[part 20 of 23: package /ComponentTypes]
AUTOSAR XML (schema 4-3-0)
package /ComponentTypes  (continued)
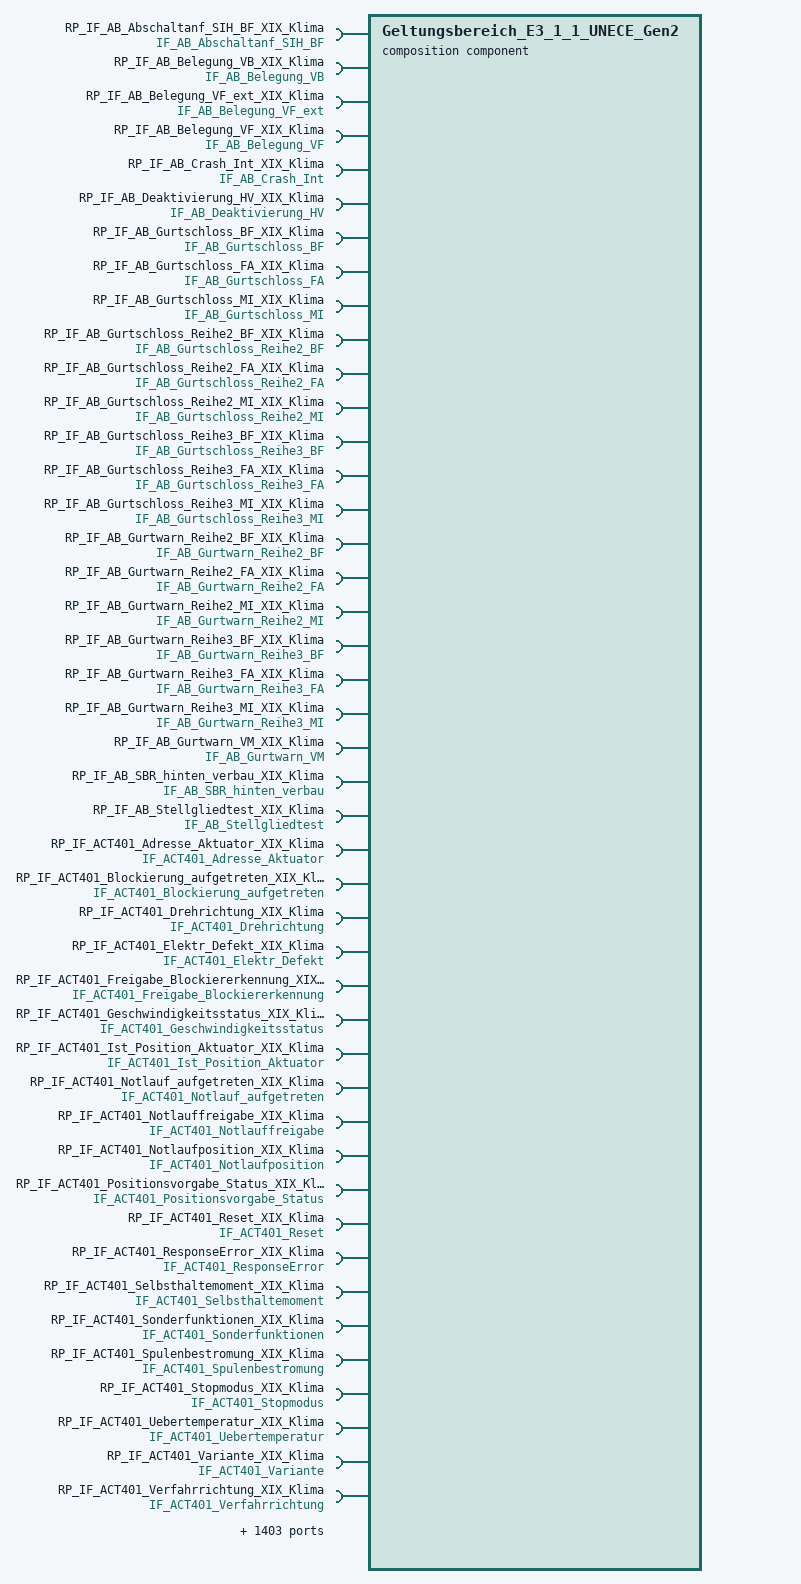
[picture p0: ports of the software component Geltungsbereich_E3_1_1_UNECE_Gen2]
  composition sw component type Geltungsbereich_E3_1_1_UNECE_Gen2  (continued)
    1485 x require port:
      RP_IF_AB_Abschaltanf_SIH_BF_XIX_Klima: required-interface=IF_AB_Abschaltanf_SIH_BF
      RP_IF_AB_Belegung_VB_XIX_Klima: required-interface=IF_AB_Belegung_VB
      RP_IF_AB_Belegung_VF_ext_XIX_Klima: required-interface=IF_AB_Belegung_VF_ext
      RP_IF_AB_Belegung_VF_XIX_Klima: required-interface=IF_AB_Belegung_VF
      RP_IF_AB_Crash_Int_XIX_Klima: required-interface=IF_AB_Crash_Int
      RP_IF_AB_Deaktivierung_HV_XIX_Klima: required-interface=IF_AB_Deaktivierung_HV
      RP_IF_AB_Gurtschloss_BF_XIX_Klima: required-interface=IF_AB_Gurtschloss_BF
      RP_IF_AB_Gurtschloss_FA_XIX_Klima: required-interface=IF_AB_Gurtschloss_FA
      RP_IF_AB_Gurtschloss_MI_XIX_Klima: required-interface=IF_AB_Gurtschloss_MI
      RP_IF_AB_Gurtschloss_Reihe2_BF_XIX_Klima: required-interface=IF_AB_Gurtschloss_Reihe2_BF
      RP_IF_AB_Gurtschloss_Reihe2_FA_XIX_Klima: required-interface=IF_AB_Gurtschloss_Reihe2_FA
      RP_IF_AB_Gurtschloss_Reihe2_MI_XIX_Klima: required-interface=IF_AB_Gurtschloss_Reihe2_MI
      RP_IF_AB_Gurtschloss_Reihe3_BF_XIX_Klima: required-interface=IF_AB_Gurtschloss_Reihe3_BF
      RP_IF_AB_Gurtschloss_Reihe3_FA_XIX_Klima: required-interface=IF_AB_Gurtschloss_Reihe3_FA
      RP_IF_AB_Gurtschloss_Reihe3_MI_XIX_Klima: required-interface=IF_AB_Gurtschloss_Reihe3_MI
      RP_IF_AB_Gurtwarn_Reihe2_BF_XIX_Klima: required-interface=IF_AB_Gurtwarn_Reihe2_BF
      RP_IF_AB_Gurtwarn_Reihe2_FA_XIX_Klima: required-interface=IF_AB_Gurtwarn_Reihe2_FA
      RP_IF_AB_Gurtwarn_Reihe2_MI_XIX_Klima: required-interface=IF_AB_Gurtwarn_Reihe2_MI
      RP_IF_AB_Gurtwarn_Reihe3_BF_XIX_Klima: required-interface=IF_AB_Gurtwarn_Reihe3_BF
      RP_IF_AB_Gurtwarn_Reihe3_FA_XIX_Klima: required-interface=IF_AB_Gurtwarn_Reihe3_FA
      RP_IF_AB_Gurtwarn_Reihe3_MI_XIX_Klima: required-interface=IF_AB_Gurtwarn_Reihe3_MI
      RP_IF_AB_Gurtwarn_VM_XIX_Klima: required-interface=IF_AB_Gurtwarn_VM
      RP_IF_AB_SBR_hinten_verbau_XIX_Klima: required-interface=IF_AB_SBR_hinten_verbau
      RP_IF_AB_Stellgliedtest_XIX_Klima: required-interface=IF_AB_Stellgliedtest
      RP_IF_ACT401_Adresse_Aktuator_XIX_Klima: required-interface=IF_ACT401_Adresse_Aktuator
      RP_IF_ACT401_Blockierung_aufgetreten_XIX_Klima: required-interface=IF_ACT401_Blockierung_aufgetreten
      RP_IF_ACT401_Drehrichtung_XIX_Klima: required-interface=IF_ACT401_Drehrichtung
      RP_IF_ACT401_Elektr_Defekt_XIX_Klima: required-interface=IF_ACT401_Elektr_Defekt
      RP_IF_ACT401_Freigabe_Blockiererkennung_XIX_Klima: required-interface=IF_ACT401_Freigabe_Blockiererkennung
      RP_IF_ACT401_Geschwindigkeitsstatus_XIX_Klima: required-interface=IF_ACT401_Geschwindigkeitsstatus
      RP_IF_ACT401_Ist_Position_Aktuator_XIX_Klima: required-interface=IF_ACT401_Ist_Position_Aktuator
      RP_IF_ACT401_Notlauf_aufgetreten_XIX_Klima: required-interface=IF_ACT401_Notlauf_aufgetreten
      RP_IF_ACT401_Notlauffreigabe_XIX_Klima: required-interface=IF_ACT401_Notlauffreigabe
      RP_IF_ACT401_Notlaufposition_XIX_Klima: required-interface=IF_ACT401_Notlaufposition
      RP_IF_ACT401_Positionsvorgabe_Status_XIX_Klima: required-interface=IF_ACT401_Positionsvorgabe_Status
      RP_IF_ACT401_Reset_XIX_Klima: required-interface=IF_ACT401_Reset
      RP_IF_ACT401_ResponseError_XIX_Klima: required-interface=IF_ACT401_ResponseError
      RP_IF_ACT401_Selbsthaltemoment_XIX_Klima: required-interface=IF_ACT401_Selbsthaltemoment
      RP_IF_ACT401_Sonderfunktionen_XIX_Klima: required-interface=IF_ACT401_Sonderfunktionen
      RP_IF_ACT401_Spulenbestromung_XIX_Klima: required-interface=IF_ACT401_Spulenbestromung
      RP_IF_ACT401_Stopmodus_XIX_Klima: required-interface=IF_ACT401_Stopmodus
      RP_IF_ACT401_Uebertemperatur_XIX_Klima: required-interface=IF_ACT401_Uebertemperatur
      RP_IF_ACT401_Variante_XIX_Klima: required-interface=IF_ACT401_Variante
      RP_IF_ACT401_Verfahrrichtung_XIX_Klima: required-interface=IF_ACT401_Verfahrrichtung
      RP_IF_ACT401_Versorgungsspannung_XIX_Klima: required-interface=IF_ACT401_Versorgungsspannung
      RP_IF_ACT402_Adresse_Aktuator_XIX_Klima: required-interface=IF_ACT402_Adresse_Aktuator
      RP_IF_ACT402_Blockierung_aufgetreten_XIX_Klima: required-interface=IF_ACT402_Blockierung_aufgetreten
      RP_IF_ACT402_Drehrichtung_XIX_Klima: required-interface=IF_ACT402_Drehrichtung
      RP_IF_ACT402_Elektr_Defekt_XIX_Klima: required-interface=IF_ACT402_Elektr_Defekt
      RP_IF_ACT402_Freigabe_Blockiererkennung_XIX_Klima: required-interface=IF_ACT402_Freigabe_Blockiererkennung
      RP_IF_ACT402_Geschwindigkeitsstatus_XIX_Klima: required-interface=IF_ACT402_Geschwindigkeitsstatus
      RP_IF_ACT402_Ist_Position_Aktuator_XIX_Klima: required-interface=IF_ACT402_Ist_Position_Aktuator
      RP_IF_ACT402_Notlauf_aufgetreten_XIX_Klima: required-interface=IF_ACT402_Notlauf_aufgetreten
      RP_IF_ACT402_Notlauffreigabe_XIX_Klima: required-interface=IF_ACT402_Notlauffreigabe
      RP_IF_ACT402_Notlaufposition_XIX_Klima: required-interface=IF_ACT402_Notlaufposition
      RP_IF_ACT402_Positionsvorgabe_Status_XIX_Klima: required-interface=IF_ACT402_Positionsvorgabe_Status
      RP_IF_ACT402_Reset_XIX_Klima: required-interface=IF_ACT402_Reset
      RP_IF_ACT402_ResponseError_XIX_Klima: required-interface=IF_ACT402_ResponseError
      RP_IF_ACT402_Selbsthaltemoment_XIX_Klima: required-interface=IF_ACT402_Selbsthaltemoment
      RP_IF_ACT402_Sonderfunktionen_XIX_Klima: required-interface=IF_ACT402_Sonderfunktionen
      RP_IF_ACT402_Spulenbestromung_XIX_Klima: required-interface=IF_ACT402_Spulenbestromung
      RP_IF_ACT402_Stopmodus_XIX_Klima: required-interface=IF_ACT402_Stopmodus
      RP_IF_ACT402_Uebertemperatur_XIX_Klima: required-interface=IF_ACT402_Uebertemperatur
      RP_IF_ACT402_Variante_XIX_Klima: required-interface=IF_ACT402_Variante
      RP_IF_ACT402_Verfahrrichtung_XIX_Klima: required-interface=IF_ACT402_Verfahrrichtung
      RP_IF_ACT402_Versorgungsspannung_XIX_Klima: required-interface=IF_ACT402_Versorgungsspannung
      RP_IF_ACT403_Adresse_Aktuator_XIX_Klima: required-interface=IF_ACT403_Adresse_Aktuator
      RP_IF_ACT403_Blockierung_aufgetreten_XIX_Klima: required-interface=IF_ACT403_Blockierung_aufgetreten
      RP_IF_ACT403_Drehrichtung_XIX_Klima: required-interface=IF_ACT403_Drehrichtung
      RP_IF_ACT403_Elektr_Defekt_XIX_Klima: required-interface=IF_ACT403_Elektr_Defekt
      RP_IF_ACT403_Freigabe_Blockiererkennung_XIX_Klima: required-interface=IF_ACT403_Freigabe_Blockiererkennung
      RP_IF_ACT403_Geschwindigkeitsstatus_XIX_Klima: required-interface=IF_ACT403_Geschwindigkeitsstatus
      RP_IF_ACT403_Ist_Position_Aktuator_XIX_Klima: required-interface=IF_ACT403_Ist_Position_Aktuator
      RP_IF_ACT403_Notlauf_aufgetreten_XIX_Klima: required-interface=IF_ACT403_Notlauf_aufgetreten
      RP_IF_ACT403_Notlauffreigabe_XIX_Klima: required-interface=IF_ACT403_Notlauffreigabe
      RP_IF_ACT403_Notlaufposition_XIX_Klima: required-interface=IF_ACT403_Notlaufposition
      RP_IF_ACT403_Positionsvorgabe_Status_XIX_Klima: required-interface=IF_ACT403_Positionsvorgabe_Status
      RP_IF_ACT403_Reset_XIX_Klima: required-interface=IF_ACT403_Reset
      RP_IF_ACT403_ResponseError_XIX_Klima: required-interface=IF_ACT403_ResponseError
      RP_IF_ACT403_Selbsthaltemoment_XIX_Klima: required-interface=IF_ACT403_Selbsthaltemoment
      RP_IF_ACT403_Sonderfunktionen_XIX_Klima: required-interface=IF_ACT403_Sonderfunktionen
      RP_IF_ACT403_Spulenbestromung_XIX_Klima: required-interface=IF_ACT403_Spulenbestromung
      RP_IF_ACT403_Stopmodus_XIX_Klima: required-interface=IF_ACT403_Stopmodus
      RP_IF_ACT403_Uebertemperatur_XIX_Klima: required-interface=IF_ACT403_Uebertemperatur
      RP_IF_ACT403_Variante_XIX_Klima: required-interface=IF_ACT403_Variante
      RP_IF_ACT403_Verfahrrichtung_XIX_Klima: required-interface=IF_ACT403_Verfahrrichtung
      RP_IF_ACT403_Versorgungsspannung_XIX_Klima: required-interface=IF_ACT403_Versorgungsspannung
      RP_IF_ACT404_Adresse_Aktuator_XIX_Klima: required-interface=IF_ACT404_Adresse_Aktuator
      RP_IF_ACT404_Blockierung_aufgetreten_XIX_Klima: required-interface=IF_ACT404_Blockierung_aufgetreten
      RP_IF_ACT404_Drehrichtung_XIX_Klima: required-interface=IF_ACT404_Drehrichtung
      RP_IF_ACT404_Elektr_Defekt_XIX_Klima: required-interface=IF_ACT404_Elektr_Defekt
      RP_IF_ACT404_Freigabe_Blockiererkennung_XIX_Klima: required-interface=IF_ACT404_Freigabe_Blockiererkennung
      RP_IF_ACT404_Geschwindigkeitsstatus_XIX_Klima: required-interface=IF_ACT404_Geschwindigkeitsstatus
      RP_IF_ACT404_Ist_Position_Aktuator_XIX_Klima: required-interface=IF_ACT404_Ist_Position_Aktuator
      RP_IF_ACT404_Notlauf_aufgetreten_XIX_Klima: required-interface=IF_ACT404_Notlauf_aufgetreten
      RP_IF_ACT404_Notlauffreigabe_XIX_Klima: required-interface=IF_ACT404_Notlauffreigabe
      RP_IF_ACT404_Notlaufposition_XIX_Klima: required-interface=IF_ACT404_Notlaufposition
      RP_IF_ACT404_Positionsvorgabe_Status_XIX_Klima: required-interface=IF_ACT404_Positionsvorgabe_Status
      RP_IF_ACT404_Reset_XIX_Klima: required-interface=IF_ACT404_Reset
      RP_IF_ACT404_ResponseError_XIX_Klima: required-interface=IF_ACT404_ResponseError
      RP_IF_ACT404_Selbsthaltemoment_XIX_Klima: required-interface=IF_ACT404_Selbsthaltemoment
      RP_IF_ACT404_Sonderfunktionen_XIX_Klima: required-interface=IF_ACT404_Sonderfunktionen
      RP_IF_ACT404_Spulenbestromung_XIX_Klima: required-interface=IF_ACT404_Spulenbestromung
      RP_IF_ACT404_Stopmodus_XIX_Klima: required-interface=IF_ACT404_Stopmodus
      RP_IF_ACT404_Uebertemperatur_XIX_Klima: required-interface=IF_ACT404_Uebertemperatur
      RP_IF_ACT404_Variante_XIX_Klima: required-interface=IF_ACT404_Variante
      RP_IF_ACT404_Verfahrrichtung_XIX_Klima: required-interface=IF_ACT404_Verfahrrichtung
      RP_IF_ACT404_Versorgungsspannung_XIX_Klima: required-interface=IF_ACT404_Versorgungsspannung
      RP_IF_ACT405_Adresse_Aktuator_XIX_Klima: required-interface=IF_ACT405_Adresse_Aktuator
      RP_IF_ACT405_Blockierung_aufgetreten_XIX_Klima: required-interface=IF_ACT405_Blockierung_aufgetreten
      RP_IF_ACT405_Drehrichtung_XIX_Klima: required-interface=IF_ACT405_Drehrichtung
      RP_IF_ACT405_Elektr_Defekt_XIX_Klima: required-interface=IF_ACT405_Elektr_Defekt
      RP_IF_ACT405_Freigabe_Blockiererkennung_XIX_Klima: required-interface=IF_ACT405_Freigabe_Blockiererkennung
      RP_IF_ACT405_Geschwindigkeitsstatus_XIX_Klima: required-interface=IF_ACT405_Geschwindigkeitsstatus
      RP_IF_ACT405_Ist_Position_Aktuator_XIX_Klima: required-interface=IF_ACT405_Ist_Position_Aktuator
      RP_IF_ACT405_Notlauf_aufgetreten_XIX_Klima: required-interface=IF_ACT405_Notlauf_aufgetreten
      RP_IF_ACT405_Notlauffreigabe_XIX_Klima: required-interface=IF_ACT405_Notlauffreigabe
      RP_IF_ACT405_Notlaufposition_XIX_Klima: required-interface=IF_ACT405_Notlaufposition
      RP_IF_ACT405_Positionsvorgabe_Status_XIX_Klima: required-interface=IF_ACT405_Positionsvorgabe_Status
      RP_IF_ACT405_Reset_XIX_Klima: required-interface=IF_ACT405_Reset
      RP_IF_ACT405_ResponseError_XIX_Klima: required-interface=IF_ACT405_ResponseError
      RP_IF_ACT405_Selbsthaltemoment_XIX_Klima: required-interface=IF_ACT405_Selbsthaltemoment
      RP_IF_ACT405_Sonderfunktionen_XIX_Klima: required-interface=IF_ACT405_Sonderfunktionen
      RP_IF_ACT405_Spulenbestromung_XIX_Klima: required-interface=IF_ACT405_Spulenbestromung
      RP_IF_ACT405_Stopmodus_XIX_Klima: required-interface=IF_ACT405_Stopmodus
      RP_IF_ACT405_Uebertemperatur_XIX_Klima: required-interface=IF_ACT405_Uebertemperatur
      RP_IF_ACT405_Variante_XIX_Klima: required-interface=IF_ACT405_Variante
      RP_IF_ACT405_Verfahrrichtung_XIX_Klima: required-interface=IF_ACT405_Verfahrrichtung
      RP_IF_ACT405_Versorgungsspannung_XIX_Klima: required-interface=IF_ACT405_Versorgungsspannung
      RP_IF_ACT406_Adresse_Aktuator_XIX_Klima: required-interface=IF_ACT406_Adresse_Aktuator
      RP_IF_ACT406_Blockierung_aufgetreten_XIX_Klima: required-interface=IF_ACT406_Blockierung_aufgetreten
      RP_IF_ACT406_Drehrichtung_XIX_Klima: required-interface=IF_ACT406_Drehrichtung
      RP_IF_ACT406_Elektr_Defekt_XIX_Klima: required-interface=IF_ACT406_Elektr_Defekt
      RP_IF_ACT406_Freigabe_Blockiererkennung_XIX_Klima: required-interface=IF_ACT406_Freigabe_Blockiererkennung
      RP_IF_ACT406_Geschwindigkeitsstatus_XIX_Klima: required-interface=IF_ACT406_Geschwindigkeitsstatus
      RP_IF_ACT406_Ist_Position_Aktuator_XIX_Klima: required-interface=IF_ACT406_Ist_Position_Aktuator
      RP_IF_ACT406_Notlauf_aufgetreten_XIX_Klima: required-interface=IF_ACT406_Notlauf_aufgetreten
      RP_IF_ACT406_Notlauffreigabe_XIX_Klima: required-interface=IF_ACT406_Notlauffreigabe
      RP_IF_ACT406_Notlaufposition_XIX_Klima: required-interface=IF_ACT406_Notlaufposition
      RP_IF_ACT406_Positionsvorgabe_Status_XIX_Klima: required-interface=IF_ACT406_Positionsvorgabe_Status
      RP_IF_ACT406_Reset_XIX_Klima: required-interface=IF_ACT406_Reset
      RP_IF_ACT406_ResponseError_XIX_Klima: required-interface=IF_ACT406_ResponseError
      RP_IF_ACT406_Selbsthaltemoment_XIX_Klima: required-interface=IF_ACT406_Selbsthaltemoment
      RP_IF_ACT406_Sonderfunktionen_XIX_Klima: required-interface=IF_ACT406_Sonderfunktionen
      RP_IF_ACT406_Spulenbestromung_XIX_Klima: required-interface=IF_ACT406_Spulenbestromung
      RP_IF_ACT406_Stopmodus_XIX_Klima: required-interface=IF_ACT406_Stopmodus
      RP_IF_ACT406_Uebertemperatur_XIX_Klima: required-interface=IF_ACT406_Uebertemperatur
      RP_IF_ACT406_Variante_XIX_Klima: required-interface=IF_ACT406_Variante
      RP_IF_ACT406_Verfahrrichtung_XIX_Klima: required-interface=IF_ACT406_Verfahrrichtung
      RP_IF_ACT406_Versorgungsspannung_XIX_Klima: required-interface=IF_ACT406_Versorgungsspannung
      RP_IF_ACT407_Adresse_Aktuator_XIX_Klima: required-interface=IF_ACT407_Adresse_Aktuator
      RP_IF_ACT407_Blockierung_aufgetreten_XIX_Klima: required-interface=IF_ACT407_Blockierung_aufgetreten
      RP_IF_ACT407_Drehrichtung_XIX_Klima: required-interface=IF_ACT407_Drehrichtung
      RP_IF_ACT407_Elektr_Defekt_XIX_Klima: required-interface=IF_ACT407_Elektr_Defekt
      RP_IF_ACT407_Freigabe_Blockiererkennung_XIX_Klima: required-interface=IF_ACT407_Freigabe_Blockiererkennung
      RP_IF_ACT407_Geschwindigkeitsstatus_XIX_Klima: required-interface=IF_ACT407_Geschwindigkeitsstatus
      RP_IF_ACT407_Ist_Position_Aktuator_XIX_Klima: required-interface=IF_ACT407_Ist_Position_Aktuator
      RP_IF_ACT407_Notlauf_aufgetreten_XIX_Klima: required-interface=IF_ACT407_Notlauf_aufgetreten
      RP_IF_ACT407_Notlauffreigabe_XIX_Klima: required-interface=IF_ACT407_Notlauffreigabe
      RP_IF_ACT407_Notlaufposition_XIX_Klima: required-interface=IF_ACT407_Notlaufposition
      RP_IF_ACT407_Positionsvorgabe_Status_XIX_Klima: required-interface=IF_ACT407_Positionsvorgabe_Status
      RP_IF_ACT407_Reset_XIX_Klima: required-interface=IF_ACT407_Reset
      RP_IF_ACT407_ResponseError_XIX_Klima: required-interface=IF_ACT407_ResponseError
      RP_IF_ACT407_Selbsthaltemoment_XIX_Klima: required-interface=IF_ACT407_Selbsthaltemoment
      RP_IF_ACT407_Sonderfunktionen_XIX_Klima: required-interface=IF_ACT407_Sonderfunktionen
      RP_IF_ACT407_Spulenbestromung_XIX_Klima: required-interface=IF_ACT407_Spulenbestromung
      RP_IF_ACT407_Stopmodus_XIX_Klima: required-interface=IF_ACT407_Stopmodus
      RP_IF_ACT407_Uebertemperatur_XIX_Klima: required-interface=IF_ACT407_Uebertemperatur
      RP_IF_ACT407_Variante_XIX_Klima: required-interface=IF_ACT407_Variante
      RP_IF_ACT407_Verfahrrichtung_XIX_Klima: required-interface=IF_ACT407_Verfahrrichtung
      RP_IF_ACT407_Versorgungsspannung_XIX_Klima: required-interface=IF_ACT407_Versorgungsspannung
      RP_IF_ACT408_Adresse_Aktuator_XIX_Klima: required-interface=IF_ACT408_Adresse_Aktuator
      RP_IF_ACT408_Blockierung_aufgetreten_XIX_Klima: required-interface=IF_ACT408_Blockierung_aufgetreten
      RP_IF_ACT408_Drehrichtung_XIX_Klima: required-interface=IF_ACT408_Drehrichtung
      RP_IF_ACT408_Elektr_Defekt_XIX_Klima: required-interface=IF_ACT408_Elektr_Defekt
      RP_IF_ACT408_Freigabe_Blockiererkennung_XIX_Klima: required-interface=IF_ACT408_Freigabe_Blockiererkennung
      RP_IF_ACT408_Geschwindigkeitsstatus_XIX_Klima: required-interface=IF_ACT408_Geschwindigkeitsstatus
      RP_IF_ACT408_Ist_Position_Aktuator_XIX_Klima: required-interface=IF_ACT408_Ist_Position_Aktuator
      RP_IF_ACT408_Notlauf_aufgetreten_XIX_Klima: required-interface=IF_ACT408_Notlauf_aufgetreten
      RP_IF_ACT408_Notlauffreigabe_XIX_Klima: required-interface=IF_ACT408_Notlauffreigabe
      RP_IF_ACT408_Notlaufposition_XIX_Klima: required-interface=IF_ACT408_Notlaufposition
      RP_IF_ACT408_Positionsvorgabe_Status_XIX_Klima: required-interface=IF_ACT408_Positionsvorgabe_Status
      RP_IF_ACT408_Reset_XIX_Klima: required-interface=IF_ACT408_Reset
      RP_IF_ACT408_ResponseError_XIX_Klima: required-interface=IF_ACT408_ResponseError
      RP_IF_ACT408_Selbsthaltemoment_XIX_Klima: required-interface=IF_ACT408_Selbsthaltemoment
      RP_IF_ACT408_Sonderfunktionen_XIX_Klima: required-interface=IF_ACT408_Sonderfunktionen
      RP_IF_ACT408_Spulenbestromung_XIX_Klima: required-interface=IF_ACT408_Spulenbestromung
      RP_IF_ACT408_Stopmodus_XIX_Klima: required-interface=IF_ACT408_Stopmodus
      RP_IF_ACT408_Uebertemperatur_XIX_Klima: required-interface=IF_ACT408_Uebertemperatur
      RP_IF_ACT408_Variante_XIX_Klima: required-interface=IF_ACT408_Variante
      RP_IF_ACT408_Verfahrrichtung_XIX_Klima: required-interface=IF_ACT408_Verfahrrichtung
      RP_IF_ACT408_Versorgungsspannung_XIX_Klima: required-interface=IF_ACT408_Versorgungsspannung
      RP_IF_ACT409_Adresse_Aktuator_XIX_Klima: required-interface=IF_ACT409_Adresse_Aktuator
      RP_IF_ACT409_Blockierung_aufgetreten_XIX_Klima: required-interface=IF_ACT409_Blockierung_aufgetreten
      RP_IF_ACT409_Drehrichtung_XIX_Klima: required-interface=IF_ACT409_Drehrichtung
      RP_IF_ACT409_Elektr_Defekt_XIX_Klima: required-interface=IF_ACT409_Elektr_Defekt
      RP_IF_ACT409_Freigabe_Blockiererkennung_XIX_Klima: required-interface=IF_ACT409_Freigabe_Blockiererkennung
      RP_IF_ACT409_Geschwindigkeitsstatus_XIX_Klima: required-interface=IF_ACT409_Geschwindigkeitsstatus
      RP_IF_ACT409_Ist_Position_Aktuator_XIX_Klima: required-interface=IF_ACT409_Ist_Position_Aktuator
      RP_IF_ACT409_Notlauf_aufgetreten_XIX_Klima: required-interface=IF_ACT409_Notlauf_aufgetreten
      RP_IF_ACT409_Notlauffreigabe_XIX_Klima: required-interface=IF_ACT409_Notlauffreigabe
      RP_IF_ACT409_Notlaufposition_XIX_Klima: required-interface=IF_ACT409_Notlaufposition
      RP_IF_ACT409_Positionsvorgabe_Status_XIX_Klima: required-interface=IF_ACT409_Positionsvorgabe_Status
      RP_IF_ACT409_Reset_XIX_Klima: required-interface=IF_ACT409_Reset
      RP_IF_ACT409_ResponseError_XIX_Klima: required-interface=IF_ACT409_ResponseError
      RP_IF_ACT409_Selbsthaltemoment_XIX_Klima: required-interface=IF_ACT409_Selbsthaltemoment
      RP_IF_ACT409_Sonderfunktionen_XIX_Klima: required-interface=IF_ACT409_Sonderfunktionen
      RP_IF_ACT409_Spulenbestromung_XIX_Klima: required-interface=IF_ACT409_Spulenbestromung
      RP_IF_ACT409_Stopmodus_XIX_Klima: required-interface=IF_ACT409_Stopmodus
      RP_IF_ACT409_Uebertemperatur_XIX_Klima: required-interface=IF_ACT409_Uebertemperatur
      RP_IF_ACT409_Variante_XIX_Klima: required-interface=IF_ACT409_Variante
      RP_IF_ACT409_Verfahrrichtung_XIX_Klima: required-interface=IF_ACT409_Verfahrrichtung
      RP_IF_ACT409_Versorgungsspannung_XIX_Klima: required-interface=IF_ACT409_Versorgungsspannung
      RP_IF_ACT410_Adresse_Aktuator_XIX_Klima: required-interface=IF_ACT410_Adresse_Aktuator
      RP_IF_ACT410_Blockierung_aufgetreten_XIX_Klima: required-interface=IF_ACT410_Blockierung_aufgetreten
      RP_IF_ACT410_Drehrichtung_XIX_Klima: required-interface=IF_ACT410_Drehrichtung
      RP_IF_ACT410_Elektr_Defekt_XIX_Klima: required-interface=IF_ACT410_Elektr_Defekt
      RP_IF_ACT410_Freigabe_Blockiererkennung_XIX_Klima: required-interface=IF_ACT410_Freigabe_Blockiererkennung
      RP_IF_ACT410_Geschwindigkeitsstatus_XIX_Klima: required-interface=IF_ACT410_Geschwindigkeitsstatus
      RP_IF_ACT410_Ist_Position_Aktuator_XIX_Klima: required-interface=IF_ACT410_Ist_Position_Aktuator
      RP_IF_ACT410_Notlauf_aufgetreten_XIX_Klima: required-interface=IF_ACT410_Notlauf_aufgetreten
      RP_IF_ACT410_Notlauffreigabe_XIX_Klima: required-interface=IF_ACT410_Notlauffreigabe
      RP_IF_ACT410_Notlaufposition_XIX_Klima: required-interface=IF_ACT410_Notlaufposition
      RP_IF_ACT410_Positionsvorgabe_Status_XIX_Klima: required-interface=IF_ACT410_Positionsvorgabe_Status
      RP_IF_ACT410_Reset_XIX_Klima: required-interface=IF_ACT410_Reset
      RP_IF_ACT410_ResponseError_XIX_Klima: required-interface=IF_ACT410_ResponseError
      RP_IF_ACT410_Selbsthaltemoment_XIX_Klima: required-interface=IF_ACT410_Selbsthaltemoment
      RP_IF_ACT410_Sonderfunktionen_XIX_Klima: required-interface=IF_ACT410_Sonderfunktionen
      RP_IF_ACT410_Spulenbestromung_XIX_Klima: required-interface=IF_ACT410_Spulenbestromung
      RP_IF_ACT410_Stopmodus_XIX_Klima: required-interface=IF_ACT410_Stopmodus
      RP_IF_ACT410_Uebertemperatur_XIX_Klima: required-interface=IF_ACT410_Uebertemperatur
      RP_IF_ACT410_Variante_XIX_Klima: required-interface=IF_ACT410_Variante
      RP_IF_ACT410_Verfahrrichtung_XIX_Klima: required-interface=IF_ACT410_Verfahrrichtung
      RP_IF_ACT410_Versorgungsspannung_XIX_Klima: required-interface=IF_ACT410_Versorgungsspannung
      RP_IF_ACT411_Adresse_Aktuator_XIX_Klima: required-interface=IF_ACT411_Adresse_Aktuator
      RP_IF_ACT411_Blockierung_aufgetreten_XIX_Klima: required-interface=IF_ACT411_Blockierung_aufgetreten
      RP_IF_ACT411_Drehrichtung_XIX_Klima: required-interface=IF_ACT411_Drehrichtung
      RP_IF_ACT411_Elektr_Defekt_XIX_Klima: required-interface=IF_ACT411_Elektr_Defekt
      RP_IF_ACT411_Freigabe_Blockiererkennung_XIX_Klima: required-interface=IF_ACT411_Freigabe_Blockiererkennung
      RP_IF_ACT411_Geschwindigkeitsstatus_XIX_Klima: required-interface=IF_ACT411_Geschwindigkeitsstatus
      RP_IF_ACT411_Ist_Position_Aktuator_XIX_Klima: required-interface=IF_ACT411_Ist_Position_Aktuator
      RP_IF_ACT411_Notlauf_aufgetreten_XIX_Klima: required-interface=IF_ACT411_Notlauf_aufgetreten
      RP_IF_ACT411_Notlauffreigabe_XIX_Klima: required-interface=IF_ACT411_Notlauffreigabe
      RP_IF_ACT411_Notlaufposition_XIX_Klima: required-interface=IF_ACT411_Notlaufposition
      RP_IF_ACT411_Positionsvorgabe_Status_XIX_Klima: required-interface=IF_ACT411_Positionsvorgabe_Status
      RP_IF_ACT411_Reset_XIX_Klima: required-interface=IF_ACT411_Reset
      RP_IF_ACT411_ResponseError_XIX_Klima: required-interface=IF_ACT411_ResponseError
      RP_IF_ACT411_Selbsthaltemoment_XIX_Klima: required-interface=IF_ACT411_Selbsthaltemoment
      RP_IF_ACT411_Sonderfunktionen_XIX_Klima: required-interface=IF_ACT411_Sonderfunktionen
      RP_IF_ACT411_Spulenbestromung_XIX_Klima: required-interface=IF_ACT411_Spulenbestromung
      RP_IF_ACT411_Stopmodus_XIX_Klima: required-interface=IF_ACT411_Stopmodus
      RP_IF_ACT411_Uebertemperatur_XIX_Klima: required-interface=IF_ACT411_Uebertemperatur
      RP_IF_ACT411_Variante_XIX_Klima: required-interface=IF_ACT411_Variante
      RP_IF_ACT411_Verfahrrichtung_XIX_Klima: required-interface=IF_ACT411_Verfahrrichtung
      RP_IF_ACT411_Versorgungsspannung_XIX_Klima: required-interface=IF_ACT411_Versorgungsspannung
      RP_IF_ACT412_Adresse_Aktuator_XIX_Klima: required-interface=IF_ACT412_Adresse_Aktuator
      RP_IF_ACT412_Blockierung_aufgetreten_XIX_Klima: required-interface=IF_ACT412_Blockierung_aufgetreten
      RP_IF_ACT412_Drehrichtung_XIX_Klima: required-interface=IF_ACT412_Drehrichtung
      RP_IF_ACT412_Elektr_Defekt_XIX_Klima: required-interface=IF_ACT412_Elektr_Defekt
      RP_IF_ACT412_Freigabe_Blockiererkennung_XIX_Klima: required-interface=IF_ACT412_Freigabe_Blockiererkennung
      RP_IF_ACT412_Geschwindigkeitsstatus_XIX_Klima: required-interface=IF_ACT412_Geschwindigkeitsstatus
      RP_IF_ACT412_Ist_Position_Aktuator_XIX_Klima: required-interface=IF_ACT412_Ist_Position_Aktuator
      RP_IF_ACT412_Notlauf_aufgetreten_XIX_Klima: required-interface=IF_ACT412_Notlauf_aufgetreten
      RP_IF_ACT412_Notlauffreigabe_XIX_Klima: required-interface=IF_ACT412_Notlauffreigabe
      RP_IF_ACT412_Notlaufposition_XIX_Klima: required-interface=IF_ACT412_Notlaufposition
      RP_IF_ACT412_Positionsvorgabe_Status_XIX_Klima: required-interface=IF_ACT412_Positionsvorgabe_Status
      RP_IF_ACT412_Reset_XIX_Klima: required-interface=IF_ACT412_Reset
      RP_IF_ACT412_ResponseError_XIX_Klima: required-interface=IF_ACT412_ResponseError
      RP_IF_ACT412_Selbsthaltemoment_XIX_Klima: required-interface=IF_ACT412_Selbsthaltemoment
      RP_IF_ACT412_Sonderfunktionen_XIX_Klima: required-interface=IF_ACT412_Sonderfunktionen
      RP_IF_ACT412_Spulenbestromung_XIX_Klima: required-interface=IF_ACT412_Spulenbestromung
      RP_IF_ACT412_Stopmodus_XIX_Klima: required-interface=IF_ACT412_Stopmodus
      RP_IF_ACT412_Uebertemperatur_XIX_Klima: required-interface=IF_ACT412_Uebertemperatur
      RP_IF_ACT412_Variante_XIX_Klima: required-interface=IF_ACT412_Variante
      RP_IF_ACT412_Verfahrrichtung_XIX_Klima: required-interface=IF_ACT412_Verfahrrichtung
      RP_IF_ACT412_Versorgungsspannung_XIX_Klima: required-interface=IF_ACT412_Versorgungsspannung
      RP_IF_AQS_COBereich_XIX_Klima: required-interface=IF_AQS_COBereich
      RP_IF_AQS_COStatus_XIX_Klima: required-interface=IF_AQS_COStatus
      RP_IF_AQS_COWert_XIX_Klima: required-interface=IF_AQS_COWert
      RP_IF_AQS_HW_XIX_Klima: required-interface=IF_AQS_HW
      RP_IF_AQS_Luftguete_XIX_Klima: required-interface=IF_AQS_Luftguete
      RP_IF_AQS_NoxBereich_XIX_Klima: required-interface=IF_AQS_NoxBereich
      RP_IF_AQS_NoxStatus_XIX_Klima: required-interface=IF_AQS_NoxStatus
      RP_IF_AQS_NoxWert_XIX_Klima: required-interface=IF_AQS_NoxWert
      RP_IF_AQS_Parameter_XIX_Klima: required-interface=IF_AQS_Parameter
      RP_IF_AQS_ResponseError_XIX_Klima: required-interface=IF_AQS_ResponseError
      RP_IF_AQS_Sensorheizung_Status_XIX_Klima: required-interface=IF_AQS_Sensorheizung_Status
      RP_IF_AQS_SW_XIX_Klima: required-interface=IF_AQS_SW
      RP_IF_AQS_Toggle_XIX_Klima: required-interface=IF_AQS_Toggle
      RP_IF_AQS_Traffic_XIX_Klima: required-interface=IF_AQS_Traffic
      RP_IF_BCM1_Aussen_Temp_ungef_XIX_Klima: required-interface=IF_BCM1_Aussen_Temp_ungef
      RP_IF_BCM1_FStatus_Aussentemp_ungef_XIX_Klima: required-interface=IF_BCM1_FStatus_Aussentemp_ungef
      RP_IF_BCM1_OBD_FStatus_ATemp_XIX_Klima: required-interface=IF_BCM1_OBD_FStatus_ATemp
      RP_IF_BEM_Red_Innengeblaese_XIX_Klima: required-interface=IF_BEM_Red_Innengeblaese
      RP_IF_BLOWER1_HW_XIX_Klima: required-interface=IF_BLOWER1_HW
      RP_IF_BLOWER1_IBATT_XIX_Klima: required-interface=IF_BLOWER1_IBATT
      RP_IF_BLOWER1_ResponseError_XIX_Klima: required-interface=IF_BLOWER1_ResponseError
      RP_IF_BLOWER1_STATUS1_XIX_Klima: required-interface=IF_BLOWER1_STATUS1
      RP_IF_BLOWER1_STATUS2_XIX_Klima: required-interface=IF_BLOWER1_STATUS2
      RP_IF_BLOWER1_SUPPLIER_XIX_Klima: required-interface=IF_BLOWER1_SUPPLIER
      RP_IF_BLOWER1_SW_XIX_Klima: required-interface=IF_BLOWER1_SW
      RP_IF_BLOWER1_TEMPERATURE_XIX_Klima: required-interface=IF_BLOWER1_TEMPERATURE
      RP_IF_BLOWER1_UBATT_XIX_Klima: required-interface=IF_BLOWER1_UBATT
      RP_IF_BLOWER1_UMOTOR_XIX_Klima: required-interface=IF_BLOWER1_UMOTOR
      RP_IF_BLOWER1b_HW_XIX_Klima: required-interface=IF_BLOWER1b_HW
      RP_IF_BLOWER1b_IBATT_XIX_Klima: required-interface=IF_BLOWER1b_IBATT
      RP_IF_BLOWER1b_ResponseError_XIX_Klima: required-interface=IF_BLOWER1b_ResponseError
      RP_IF_BLOWER1b_STATUS1_XIX_Klima: required-interface=IF_BLOWER1b_STATUS1
      RP_IF_BLOWER1b_STATUS2_XIX_Klima: required-interface=IF_BLOWER1b_STATUS2
      RP_IF_BLOWER1b_SUPPLIER_XIX_Klima: required-interface=IF_BLOWER1b_SUPPLIER
      RP_IF_BLOWER1b_SW_XIX_Klima: required-interface=IF_BLOWER1b_SW
      RP_IF_BLOWER1b_TEMPERATURE_XIX_Klima: required-interface=IF_BLOWER1b_TEMPERATURE
      RP_IF_BLOWER1b_UBATT_XIX_Klima: required-interface=IF_BLOWER1b_UBATT
      RP_IF_BLOWER1b_UMOTOR_XIX_Klima: required-interface=IF_BLOWER1b_UMOTOR
      RP_IF_BLOWER1c_HW_XIX_Klima: required-interface=IF_BLOWER1c_HW
      RP_IF_BLOWER1c_IBATT_XIX_Klima: required-interface=IF_BLOWER1c_IBATT
      RP_IF_BLOWER1c_ResponseError_XIX_Klima: required-interface=IF_BLOWER1c_ResponseError
      RP_IF_BLOWER1c_STATUS1_XIX_Klima: required-interface=IF_BLOWER1c_STATUS1
      RP_IF_BLOWER1c_STATUS2_XIX_Klima: required-interface=IF_BLOWER1c_STATUS2
      RP_IF_BLOWER1c_SUPPLIER_XIX_Klima: required-interface=IF_BLOWER1c_SUPPLIER
      RP_IF_BLOWER1c_SW_XIX_Klima: required-interface=IF_BLOWER1c_SW
      RP_IF_BLOWER1c_TEMPERATURE_XIX_Klima: required-interface=IF_BLOWER1c_TEMPERATURE
      RP_IF_BLOWER1c_UBATT_XIX_Klima: required-interface=IF_BLOWER1c_UBATT
      RP_IF_BLOWER1c_UMOTOR_XIX_Klima: required-interface=IF_BLOWER1c_UMOTOR
      RP_IF_BLOWER2_HW_XIX_Klima: required-interface=IF_BLOWER2_HW
      RP_IF_BLOWER2_IBATT_XIX_Klima: required-interface=IF_BLOWER2_IBATT
      RP_IF_BLOWER2_ResponseError_XIX_Klima: required-interface=IF_BLOWER2_ResponseError
      RP_IF_BLOWER2_STATUS1_INVALID_XIX_Klima: required-interface=IF_BLOWER2_STATUS1_INVALID
      RP_IF_BLOWER2_STATUS1_XIX_Klima: required-interface=IF_BLOWER2_STATUS1
      RP_IF_BLOWER2_STATUS2_XIX_Klima: required-interface=IF_BLOWER2_STATUS2
      RP_IF_BLOWER2_SUPPLIER_XIX_Klima: required-interface=IF_BLOWER2_SUPPLIER
      RP_IF_BLOWER2_SW_XIX_Klima: required-interface=IF_BLOWER2_SW
      RP_IF_BLOWER2_TEMPERATURE_XIX_Klima: required-interface=IF_BLOWER2_TEMPERATURE
      RP_IF_BLOWER2_UBATT_XIX_Klima: required-interface=IF_BLOWER2_UBATT
      RP_IF_BLOWER2_UMOTOR_XIX_Klima: required-interface=IF_BLOWER2_UMOTOR
      RP_IF_BLOWER2b_HW_XIX_Klima: required-interface=IF_BLOWER2b_HW
      RP_IF_BLOWER2b_IBATT_XIX_Klima: required-interface=IF_BLOWER2b_IBATT
      RP_IF_BLOWER2b_ResponseError_XIX_Klima: required-interface=IF_BLOWER2b_ResponseError
      RP_IF_BLOWER2b_STATUS1_INVALID_XIX_Klima: required-interface=IF_BLOWER2b_STATUS1_INVALID
      RP_IF_BLOWER2b_STATUS1_XIX_Klima: required-interface=IF_BLOWER2b_STATUS1
      RP_IF_BLOWER2b_STATUS2_XIX_Klima: required-interface=IF_BLOWER2b_STATUS2
      RP_IF_BLOWER2b_SUPPLIER_XIX_Klima: required-interface=IF_BLOWER2b_SUPPLIER
      RP_IF_BLOWER2b_SW_XIX_Klima: required-interface=IF_BLOWER2b_SW
      RP_IF_BLOWER2b_TEMPERATURE_XIX_Klima: required-interface=IF_BLOWER2b_TEMPERATURE
      RP_IF_BLOWER2b_UBATT_XIX_Klima: required-interface=IF_BLOWER2b_UBATT
      RP_IF_BLOWER2b_UMOTOR_XIX_Klima: required-interface=IF_BLOWER2b_UMOTOR
      RP_IF_BLOWER_DIAG_FLAG1_XIX_Klima: required-interface=IF_BLOWER_DIAG_FLAG1
      RP_IF_BLOWER_DIAG_FLAG2_XIX_Klima: required-interface=IF_BLOWER_DIAG_FLAG2
      RP_IF_BLOWER_IBATT_XIX_Klima: required-interface=IF_BLOWER_IBATT
      RP_IF_BLOWER_ResponseError_XIX_Klima: required-interface=IF_BLOWER_ResponseError
      RP_IF_BLOWER_ROTATION_SPEED_XIX_Klima: required-interface=IF_BLOWER_ROTATION_SPEED
      RP_IF_BLOWER_STATUS_MOTOR_XIX_Klima: required-interface=IF_BLOWER_STATUS_MOTOR
      RP_IF_BLOWER_SUPPLIER_XIX_Klima: required-interface=IF_BLOWER_SUPPLIER
      RP_IF_BLOWER_TEMPERATURE_XIX_Klima: required-interface=IF_BLOWER_TEMPERATURE
      RP_IF_BLOWER_TORQUE_XIX_Klima: required-interface=IF_BLOWER_TORQUE
      RP_IF_BLOWER_UBATT_XIX_Klima: required-interface=IF_BLOWER_UBATT
      RP_IF_BLOWER_UMOTOR_XIX_Klima: required-interface=IF_BLOWER_UMOTOR
      RP_IF_BMS_BattHeizung_Anf_XIX_Klima: required-interface=IF_BMS_BattHeizung_Anf
      RP_IF_BMS_DC_Ladeprofil_XIX_Klima: required-interface=IF_BMS_DC_Ladeprofil
      RP_IF_BMS_Fehler_NTKreis_XIX_Klima: required-interface=IF_BMS_Fehler_NTKreis
      RP_IF_BMS_Kuehlung_Anf_XIX_Klima: required-interface=IF_BMS_Kuehlung_Anf
      RP_IF_BMS_KundenWarnung_XIX_Klima: required-interface=IF_BMS_KundenWarnung
      RP_IF_BMS_Ladezustand_XIX_Klima: required-interface=IF_BMS_Ladezustand
      RP_IF_BMS_Pumpe1_Ansteuerung_XIX_Klima: required-interface=IF_BMS_Pumpe1_Ansteuerung
      RP_IF_BMS_Pumpe2_Ansteuerung_XIX_Klima: required-interface=IF_BMS_Pumpe2_Ansteuerung
      RP_IF_BMS_RuecklaufTemperatur_XIX_Klima: required-interface=IF_BMS_RuecklaufTemperatur
      RP_IF_BMS_SollVorlauftemperatur_XIX_Klima: required-interface=IF_BMS_SollVorlauftemperatur
      RP_IF_BMS_Spannung_XIX_Klima: required-interface=IF_BMS_Spannung
      RP_IF_BMS_Status_Ventil1_XIX_Klima: required-interface=IF_BMS_Status_Ventil1
      RP_IF_BMS_Status_Ventil2_XIX_Klima: required-interface=IF_BMS_Status_Ventil2
      RP_IF_BMS_Strom_XIX_Klima: required-interface=IF_BMS_Strom
      RP_IF_BMS_Temperatur_XIX_Klima: required-interface=IF_BMS_Temperatur
      RP_IF_BMS_Temperierung_Anf_XIX_Klima: required-interface=IF_BMS_Temperierung_Anf
      RP_IF_BMS_TMA_Betriebsart_XIX_Klima: required-interface=IF_BMS_TMA_Betriebsart
      RP_IF_BMS_TMA_Kuehlkreis_Status_XIX_Klima: required-interface=IF_BMS_TMA_Kuehlkreis_Status
      RP_IF_BMS_UBE_T_XIX_Klima: required-interface=IF_BMS_UBE_T
      RP_IF_BMS_VorlaufTemperatur_XIX_Klima: required-interface=IF_BMS_VorlaufTemperatur
      RP_IF_BT_FH_Oeffnung_XIX_Klima: required-interface=IF_BT_FH_Oeffnung
      RP_IF_BT_Tuer_geoeffnet_XIX_Klima: required-interface=IF_BT_Tuer_geoeffnet
      RP_IF_CHA_Fahrer_Umschaltung_XIX_Klima: required-interface=IF_CHA_Fahrer_Umschaltung
      RP_IF_CHA_Ziel_FahrPr_KL_XIX_Klima: required-interface=IF_CHA_Ziel_FahrPr_KL
      RP_IF_DGN_Verlernzaehler_XIX_Klima: required-interface=IF_DGN_Verlernzaehler
      RP_IF_DI_KL_58xd_XIX_Klima: required-interface=IF_DI_KL_58xd
      RP_IF_DI_KL_58xs_XIX_Klima: required-interface=IF_DI_KL_58xs
      RP_IF_DiETa_Defrost_Taste_XIX_Klima: required-interface=IF_DiETa_Defrost_Taste
      RP_IF_DiETa_FSH_Taste_XIX_Klima: required-interface=IF_DiETa_FSH_Taste
      RP_IF_DiETa_HSH_Taste_XIX_Klima: required-interface=IF_DiETa_HSH_Taste
      RP_IF_DiETa_Klima_XIX_Klima: required-interface=IF_DiETa_Klima
      RP_IF_DS_BitError_XIX_Klima: required-interface=IF_DS_BitError
      RP_IF_DS_ChecksumError_XIX_Klima: required-interface=IF_DS_ChecksumError
      RP_IF_DS_DruckError_XIX_Klima: required-interface=IF_DS_DruckError
      RP_IF_DS_HW_XIX_Klima: required-interface=IF_DS_HW
      RP_IF_DS_Kaeltemittel_P_XIX_Klima: required-interface=IF_DS_Kaeltemittel_P
      RP_IF_DS_SW_XIX_Klima: required-interface=IF_DS_SW
      RP_IF_DS_TempError_XIX_Klima: required-interface=IF_DS_TempError
      RP_IF_DTS1_Fehler_XIX_Klima: required-interface=IF_DTS1_Fehler
      RP_IF_DTS1_interne_Sensor_T_XIX_Klima: required-interface=IF_DTS1_interne_Sensor_T
      RP_IF_DTS1_Kaeltemittel_p_XIX_Klima: required-interface=IF_DTS1_Kaeltemittel_p
      RP_IF_DTS1_Kaeltemittel_T_XIX_Klima: required-interface=IF_DTS1_Kaeltemittel_T
      RP_IF_DTS1_Kommunikation_XIX_Klima: required-interface=IF_DTS1_Kommunikation
      RP_IF_DTS1_R744_Fehler_XIX_Klima: required-interface=IF_DTS1_R744_Fehler
      RP_IF_DTS1_R744_interne_Sensor_T_XIX_Klima: required-interface=IF_DTS1_R744_interne_Sensor_T
      RP_IF_DTS1_R744_Kaeltemittel_p_XIX_Klima: required-interface=IF_DTS1_R744_Kaeltemittel_p
      RP_IF_DTS1_R744_Kaeltemittel_t_XIX_Klima: required-interface=IF_DTS1_R744_Kaeltemittel_t
      RP_IF_DTS1_R744_Kommunikation_XIX_Klima: required-interface=IF_DTS1_R744_Kommunikation
      RP_IF_DTS1_R744_ResponseError_XIX_Klima: required-interface=IF_DTS1_R744_ResponseError
      RP_IF_DTS1_R744_TNCTOC_XIX_Klima: required-interface=IF_DTS1_R744_TNCTOC
      RP_IF_DTS1_ResponseError_XIX_Klima: required-interface=IF_DTS1_ResponseError
      RP_IF_DTS1_TNCTOC_XIX_Klima: required-interface=IF_DTS1_TNCTOC
      RP_IF_DTS2_Fehler_XIX_Klima: required-interface=IF_DTS2_Fehler
      RP_IF_DTS2_interne_Sensor_T_XIX_Klima: required-interface=IF_DTS2_interne_Sensor_T
      RP_IF_DTS2_Kaeltemittel_p_XIX_Klima: required-interface=IF_DTS2_Kaeltemittel_p
      RP_IF_DTS2_Kaeltemittel_T_XIX_Klima: required-interface=IF_DTS2_Kaeltemittel_T
      RP_IF_DTS2_Kommunikation_XIX_Klima: required-interface=IF_DTS2_Kommunikation
      RP_IF_DTS2_R744_Fehler_XIX_Klima: required-interface=IF_DTS2_R744_Fehler
      RP_IF_DTS2_R744_interne_Sensor_T_XIX_Klima: required-interface=IF_DTS2_R744_interne_Sensor_T
      RP_IF_DTS2_R744_Kaeltemittel_p_XIX_Klima: required-interface=IF_DTS2_R744_Kaeltemittel_p
      RP_IF_DTS2_R744_Kaeltemittel_t_XIX_Klima: required-interface=IF_DTS2_R744_Kaeltemittel_t
      RP_IF_DTS2_R744_Kommunikation_XIX_Klima: required-interface=IF_DTS2_R744_Kommunikation
      RP_IF_DTS2_R744_ResponseError_XIX_Klima: required-interface=IF_DTS2_R744_ResponseError
      RP_IF_DTS2_R744_TNCTOC_XIX_Klima: required-interface=IF_DTS2_R744_TNCTOC
      RP_IF_DTS2_ResponseError_XIX_Klima: required-interface=IF_DTS2_ResponseError
      RP_IF_DTS2_TNCTOC_XIX_Klima: required-interface=IF_DTS2_TNCTOC
      RP_IF_DTS2b_R744_Fehler_XIX_Klima: required-interface=IF_DTS2b_R744_Fehler
      RP_IF_DTS2b_R744_interne_Sensor_T_XIX_Klima: required-interface=IF_DTS2b_R744_interne_Sensor_T
      RP_IF_DTS2b_R744_Kaeltemittel_p_XIX_Klima: required-interface=IF_DTS2b_R744_Kaeltemittel_p
      RP_IF_DTS2b_R744_Kaeltemittel_t_XIX_Klima: required-interface=IF_DTS2b_R744_Kaeltemittel_t
      RP_IF_DTS2b_R744_Kommunikation_XIX_Klima: required-interface=IF_DTS2b_R744_Kommunikation
      RP_IF_DTS2b_R744_ResponseError_XIX_Klima: required-interface=IF_DTS2b_R744_ResponseError
      RP_IF_DTS2b_R744_TNCTOC_XIX_Klima: required-interface=IF_DTS2b_R744_TNCTOC
      RP_IF_DTS2c_R744_Fehler_XIX_Klima: required-interface=IF_DTS2c_R744_Fehler
      RP_IF_DTS2c_R744_interne_Sensor_T_XIX_Klima: required-interface=IF_DTS2c_R744_interne_Sensor_T
      RP_IF_DTS2c_R744_Kaeltemittel_p_XIX_Klima: required-interface=IF_DTS2c_R744_Kaeltemittel_p
      RP_IF_DTS2c_R744_Kaeltemittel_t_XIX_Klima: required-interface=IF_DTS2c_R744_Kaeltemittel_t
      RP_IF_DTS2c_R744_Kommunikation_XIX_Klima: required-interface=IF_DTS2c_R744_Kommunikation
      RP_IF_DTS2c_R744_ResponseError_XIX_Klima: required-interface=IF_DTS2c_R744_ResponseError
      RP_IF_DTS2c_R744_TNCTOC_XIX_Klima: required-interface=IF_DTS2c_R744_TNCTOC
      RP_IF_DTS3_Fehler_XIX_Klima: required-interface=IF_DTS3_Fehler
      RP_IF_DTS3_interne_Sensor_T_XIX_Klima: required-interface=IF_DTS3_interne_Sensor_T
      RP_IF_DTS3_Kaeltemittel_p_XIX_Klima: required-interface=IF_DTS3_Kaeltemittel_p
      RP_IF_DTS3_Kaeltemittel_T_XIX_Klima: required-interface=IF_DTS3_Kaeltemittel_T
      RP_IF_DTS3_Kommunikation_XIX_Klima: required-interface=IF_DTS3_Kommunikation
      RP_IF_DTS3_R744_Fehler_XIX_Klima: required-interface=IF_DTS3_R744_Fehler
      RP_IF_DTS3_R744_interne_Sensor_T_XIX_Klima: required-interface=IF_DTS3_R744_interne_Sensor_T
      RP_IF_DTS3_R744_Kaeltemittel_p_XIX_Klima: required-interface=IF_DTS3_R744_Kaeltemittel_p
      RP_IF_DTS3_R744_Kaeltemittel_t_XIX_Klima: required-interface=IF_DTS3_R744_Kaeltemittel_t
      RP_IF_DTS3_R744_Kommunikation_XIX_Klima: required-interface=IF_DTS3_R744_Kommunikation
      RP_IF_DTS3_R744_ResponseError_XIX_Klima: required-interface=IF_DTS3_R744_ResponseError
      RP_IF_DTS3_R744_TNCTOC_XIX_Klima: required-interface=IF_DTS3_R744_TNCTOC
      RP_IF_DTS3_ResponseError_XIX_Klima: required-interface=IF_DTS3_ResponseError
      RP_IF_DTS3_TNCTOC_XIX_Klima: required-interface=IF_DTS3_TNCTOC
      RP_IF_DTS3b_R744_Fehler_XIX_Klima: required-interface=IF_DTS3b_R744_Fehler
      RP_IF_DTS3b_R744_interne_Sensor_T_XIX_Klima: required-interface=IF_DTS3b_R744_interne_Sensor_T
      RP_IF_DTS3b_R744_Kaeltemittel_p_XIX_Klima: required-interface=IF_DTS3b_R744_Kaeltemittel_p
      RP_IF_DTS3b_R744_Kaeltemittel_t_XIX_Klima: required-interface=IF_DTS3b_R744_Kaeltemittel_t
      RP_IF_DTS3b_R744_Kommunikation_XIX_Klima: required-interface=IF_DTS3b_R744_Kommunikation
      RP_IF_DTS3b_R744_ResponseError_XIX_Klima: required-interface=IF_DTS3b_R744_ResponseError
      RP_IF_DTS3b_R744_TNCTOC_XIX_Klima: required-interface=IF_DTS3b_R744_TNCTOC
      RP_IF_EASV1_Err_Blockierung_TF_XIX_Klima: required-interface=IF_EASV1_Err_Blockierung_TF
      RP_IF_EASV1_Err_Blockierung_TNCTOC_XIX_Klima: required-interface=IF_EASV1_Err_Blockierung_TNCTOC
      RP_IF_EASV1_Err_EDefekt_MoKomp_TF_XIX_Klima: required-interface=IF_EASV1_Err_EDefekt_MoKomp_TF
      RP_IF_EASV1_Err_EDefekt_MoKomp_TNCTOC_XIX_Klima: required-interface=IF_EASV1_Err_EDefekt_MoKomp_TNCTOC
      RP_IF_EASV1_Err_EDefekt_TSens_TF_XIX_Klima: required-interface=IF_EASV1_Err_EDefekt_TSens_TF
      RP_IF_EASV1_Err_EDefekt_TSens_TNCTOC_XIX_Klima: required-interface=IF_EASV1_Err_EDefekt_TSens_TNCTOC
      RP_IF_EASV1_Err_Notlaufpos_TF_XIX_Klima: required-interface=IF_EASV1_Err_Notlaufpos_TF
      RP_IF_EASV1_Err_Notlaufpos_TNCTOC_XIX_Klima: required-interface=IF_EASV1_Err_Notlaufpos_TNCTOC
      RP_IF_EASV1_Err_RAMROMNADChange_TF_XIX_Klima: required-interface=IF_EASV1_Err_RAMROMNADChange_TF
      RP_IF_EASV1_Err_RAMROMNADChange_TNCTOC_XIX_Klima: required-interface=IF_EASV1_Err_RAMROMNADChange_TNCTOC
      RP_IF_EASV1_Err_Ueberspannung_TF_XIX_Klima: required-interface=IF_EASV1_Err_Ueberspannung_TF
      RP_IF_EASV1_Err_Ueberspannung_TNCTOC_XIX_Klima: required-interface=IF_EASV1_Err_Ueberspannung_TNCTOC
      RP_IF_EASV1_Err_Uebertemperatur_TF_XIX_Klima: required-interface=IF_EASV1_Err_Uebertemperatur_TF
      RP_IF_EASV1_Err_Uebertemperatur_TNCTOC_XIX_Klima: required-interface=IF_EASV1_Err_Uebertemperatur_TNCTOC
      RP_IF_EASV1_Err_Unterspannung_TF_XIX_Klima: required-interface=IF_EASV1_Err_Unterspannung_TF
      RP_IF_EASV1_Err_Unterspannung_TNCTOC_XIX_Klima: required-interface=IF_EASV1_Err_Unterspannung_TNCTOC
      RP_IF_EASV1_ErrMem_State_XIX_Klima: required-interface=IF_EASV1_ErrMem_State
      RP_IF_EASV1_Geschwindigkeitsstatus_XIX_Klima: required-interface=IF_EASV1_Geschwindigkeitsstatus
      RP_IF_EASV1_Ist_Position_Aktuator_XIX_Klima: required-interface=IF_EASV1_Ist_Position_Aktuator
      RP_IF_EASV1_ResponseError_TNCTOC_XIX_Klima: required-interface=IF_EASV1_ResponseError_TNCTOC
      RP_IF_EASV1_ResponseError_XIX_Klima: required-interface=IF_EASV1_ResponseError
      RP_IF_EASV1_Spulenbestromung_XIX_Klima: required-interface=IF_EASV1_Spulenbestromung
      RP_IF_EASV1_Temp_Warning_XIX_Klima: required-interface=IF_EASV1_Temp_Warning
      RP_IF_EASV1_Temp_XIX_Klima: required-interface=IF_EASV1_Temp
      RP_IF_EASV2_Err_Blockierung_TF_XIX_Klima: required-interface=IF_EASV2_Err_Blockierung_TF
      RP_IF_EASV2_Err_Blockierung_TNCTOC_XIX_Klima: required-interface=IF_EASV2_Err_Blockierung_TNCTOC
      RP_IF_EASV2_Err_EDefekt_MoKomp_TF_XIX_Klima: required-interface=IF_EASV2_Err_EDefekt_MoKomp_TF
      RP_IF_EASV2_Err_EDefekt_MoKomp_TNCTOC_XIX_Klima: required-interface=IF_EASV2_Err_EDefekt_MoKomp_TNCTOC
      RP_IF_EASV2_Err_EDefekt_TSens_TF_XIX_Klima: required-interface=IF_EASV2_Err_EDefekt_TSens_TF
      RP_IF_EASV2_Err_EDefekt_TSens_TNCTOC_XIX_Klima: required-interface=IF_EASV2_Err_EDefekt_TSens_TNCTOC
      RP_IF_EASV2_Err_Notlaufpos_TF_XIX_Klima: required-interface=IF_EASV2_Err_Notlaufpos_TF
      RP_IF_EASV2_Err_Notlaufpos_TNCTOC_XIX_Klima: required-interface=IF_EASV2_Err_Notlaufpos_TNCTOC
      RP_IF_EASV2_Err_RAMROMNADChange_TF_XIX_Klima: required-interface=IF_EASV2_Err_RAMROMNADChange_TF
      RP_IF_EASV2_Err_RAMROMNADChange_TNCTOC_XIX_Klima: required-interface=IF_EASV2_Err_RAMROMNADChange_TNCTOC
      RP_IF_EASV2_Err_Ueberspannung_TF_XIX_Klima: required-interface=IF_EASV2_Err_Ueberspannung_TF
      RP_IF_EASV2_Err_Ueberspannung_TNCTOC_XIX_Klima: required-interface=IF_EASV2_Err_Ueberspannung_TNCTOC
      RP_IF_EASV2_Err_Uebertemperatur_TF_XIX_Klima: required-interface=IF_EASV2_Err_Uebertemperatur_TF
      RP_IF_EASV2_Err_Uebertemperatur_TNCTOC_XIX_Klima: required-interface=IF_EASV2_Err_Uebertemperatur_TNCTOC
      RP_IF_EASV2_Err_Unterspannung_TF_XIX_Klima: required-interface=IF_EASV2_Err_Unterspannung_TF
      RP_IF_EASV2_Err_Unterspannung_TNCTOC_XIX_Klima: required-interface=IF_EASV2_Err_Unterspannung_TNCTOC
      RP_IF_EASV2_ErrMem_State_XIX_Klima: required-interface=IF_EASV2_ErrMem_State
      RP_IF_EASV2_Geschwindigkeitsstatus_XIX_Klima: required-interface=IF_EASV2_Geschwindigkeitsstatus
      RP_IF_EASV2_Ist_Position_Aktuator_XIX_Klima: required-interface=IF_EASV2_Ist_Position_Aktuator
      RP_IF_EASV2_ResponseError_TNCTOC_XIX_Klima: required-interface=IF_EASV2_ResponseError_TNCTOC
      RP_IF_EASV2_ResponseError_XIX_Klima: required-interface=IF_EASV2_ResponseError
      RP_IF_EASV2_Spulenbestromung_XIX_Klima: required-interface=IF_EASV2_Spulenbestromung
      RP_IF_EASV2_Temp_Warning_XIX_Klima: required-interface=IF_EASV2_Temp_Warning
      RP_IF_EASV2_Temp_XIX_Klima: required-interface=IF_EASV2_Temp
      RP_IF_EASV3_Err_Blockierung_TF_XIX_Klima: required-interface=IF_EASV3_Err_Blockierung_TF
      RP_IF_EASV3_Err_Blockierung_TNCTOC_XIX_Klima: required-interface=IF_EASV3_Err_Blockierung_TNCTOC
      RP_IF_EASV3_Err_EDefekt_MoKomp_TF_XIX_Klima: required-interface=IF_EASV3_Err_EDefekt_MoKomp_TF
      RP_IF_EASV3_Err_EDefekt_MoKomp_TNCTOC_XIX_Klima: required-interface=IF_EASV3_Err_EDefekt_MoKomp_TNCTOC
      RP_IF_EASV3_Err_EDefekt_TSens_TF_XIX_Klima: required-interface=IF_EASV3_Err_EDefekt_TSens_TF
      RP_IF_EASV3_Err_EDefekt_TSens_TNCTOC_XIX_Klima: required-interface=IF_EASV3_Err_EDefekt_TSens_TNCTOC
      RP_IF_EASV3_Err_Notlaufpos_TF_XIX_Klima: required-interface=IF_EASV3_Err_Notlaufpos_TF
      RP_IF_EASV3_Err_Notlaufpos_TNCTOC_XIX_Klima: required-interface=IF_EASV3_Err_Notlaufpos_TNCTOC
      RP_IF_EASV3_Err_RAMROMNADChange_TF_XIX_Klima: required-interface=IF_EASV3_Err_RAMROMNADChange_TF
      RP_IF_EASV3_Err_RAMROMNADChange_TNCTOC_XIX_Klima: required-interface=IF_EASV3_Err_RAMROMNADChange_TNCTOC
      RP_IF_EASV3_Err_Ueberspannung_TF_XIX_Klima: required-interface=IF_EASV3_Err_Ueberspannung_TF
      RP_IF_EASV3_Err_Ueberspannung_TNCTOC_XIX_Klima: required-interface=IF_EASV3_Err_Ueberspannung_TNCTOC
      RP_IF_EASV3_Err_Uebertemperatur_TF_XIX_Klima: required-interface=IF_EASV3_Err_Uebertemperatur_TF
      RP_IF_EASV3_Err_Uebertemperatur_TNCTOC_XIX_Klima: required-interface=IF_EASV3_Err_Uebertemperatur_TNCTOC
      RP_IF_EASV3_Err_Unterspannung_TF_XIX_Klima: required-interface=IF_EASV3_Err_Unterspannung_TF
      RP_IF_EASV3_Err_Unterspannung_TNCTOC_XIX_Klima: required-interface=IF_EASV3_Err_Unterspannung_TNCTOC
      RP_IF_EASV3_ErrMem_State_XIX_Klima: required-interface=IF_EASV3_ErrMem_State
      RP_IF_EASV3_Geschwindigkeitsstatus_XIX_Klima: required-interface=IF_EASV3_Geschwindigkeitsstatus
      RP_IF_EASV3_Ist_Position_Aktuator_XIX_Klima: required-interface=IF_EASV3_Ist_Position_Aktuator
      RP_IF_EASV3_ResponseError_TNCTOC_XIX_Klima: required-interface=IF_EASV3_ResponseError_TNCTOC
      RP_IF_EASV3_ResponseError_XIX_Klima: required-interface=IF_EASV3_ResponseError
      RP_IF_EASV3_Spulenbestromung_XIX_Klima: required-interface=IF_EASV3_Spulenbestromung
      RP_IF_EASV3_Temp_Warning_XIX_Klima: required-interface=IF_EASV3_Temp_Warning
      RP_IF_EASV3_Temp_XIX_Klima: required-interface=IF_EASV3_Temp
      RP_IF_EASV4_Err_Blockierung_TF_XIX_Klima: required-interface=IF_EASV4_Err_Blockierung_TF
      RP_IF_EASV4_Err_Blockierung_TNCTOC_XIX_Klima: required-interface=IF_EASV4_Err_Blockierung_TNCTOC
      RP_IF_EASV4_Err_EDefekt_MoKomp_TF_XIX_Klima: required-interface=IF_EASV4_Err_EDefekt_MoKomp_TF
      RP_IF_EASV4_Err_EDefekt_MoKomp_TNCTOC_XIX_Klima: required-interface=IF_EASV4_Err_EDefekt_MoKomp_TNCTOC
      RP_IF_EASV4_Err_EDefekt_TSens_TF_XIX_Klima: required-interface=IF_EASV4_Err_EDefekt_TSens_TF
      RP_IF_EASV4_Err_EDefekt_TSens_TNCTOC_XIX_Klima: required-interface=IF_EASV4_Err_EDefekt_TSens_TNCTOC
      RP_IF_EASV4_Err_Notlaufpos_TF_XIX_Klima: required-interface=IF_EASV4_Err_Notlaufpos_TF
      RP_IF_EASV4_Err_Notlaufpos_TNCTOC_XIX_Klima: required-interface=IF_EASV4_Err_Notlaufpos_TNCTOC
      RP_IF_EASV4_Err_RAMROMNADChange_TF_XIX_Klima: required-interface=IF_EASV4_Err_RAMROMNADChange_TF
      RP_IF_EASV4_Err_RAMROMNADChange_TNCTOC_XIX_Klima: required-interface=IF_EASV4_Err_RAMROMNADChange_TNCTOC
      RP_IF_EASV4_Err_Ueberspannung_TF_XIX_Klima: required-interface=IF_EASV4_Err_Ueberspannung_TF
      RP_IF_EASV4_Err_Ueberspannung_TNCTOC_XIX_Klima: required-interface=IF_EASV4_Err_Ueberspannung_TNCTOC
      RP_IF_EASV4_Err_Uebertemperatur_TF_XIX_Klima: required-interface=IF_EASV4_Err_Uebertemperatur_TF
      RP_IF_EASV4_Err_Uebertemperatur_TNCTOC_XIX_Klima: required-interface=IF_EASV4_Err_Uebertemperatur_TNCTOC
      RP_IF_EASV4_Err_Unterspannung_TF_XIX_Klima: required-interface=IF_EASV4_Err_Unterspannung_TF
      RP_IF_EASV4_Err_Unterspannung_TNCTOC_XIX_Klima: required-interface=IF_EASV4_Err_Unterspannung_TNCTOC
      RP_IF_EASV4_ErrMem_State_XIX_Klima: required-interface=IF_EASV4_ErrMem_State
      RP_IF_EASV4_Geschwindigkeitsstatus_XIX_Klima: required-interface=IF_EASV4_Geschwindigkeitsstatus
      RP_IF_EASV4_Ist_Position_Aktuator_XIX_Klima: required-interface=IF_EASV4_Ist_Position_Aktuator
      RP_IF_EASV4_ResponseError_TNCTOC_XIX_Klima: required-interface=IF_EASV4_ResponseError_TNCTOC
      RP_IF_EASV4_ResponseError_XIX_Klima: required-interface=IF_EASV4_ResponseError
      RP_IF_EASV4_Spulenbestromung_XIX_Klima: required-interface=IF_EASV4_Spulenbestromung
      RP_IF_EASV4_Temp_Warning_XIX_Klima: required-interface=IF_EASV4_Temp_Warning
      RP_IF_EASV4_Temp_XIX_Klima: required-interface=IF_EASV4_Temp
      RP_IF_EASV5_Err_Blockierung_TF_XIX_Klima: required-interface=IF_EASV5_Err_Blockierung_TF
      RP_IF_EASV5_Err_Blockierung_TNCTOC_XIX_Klima: required-interface=IF_EASV5_Err_Blockierung_TNCTOC
      RP_IF_EASV5_Err_EDefekt_MoKomp_TF_XIX_Klima: required-interface=IF_EASV5_Err_EDefekt_MoKomp_TF
      RP_IF_EASV5_Err_EDefekt_MoKomp_TNCTOC_XIX_Klima: required-interface=IF_EASV5_Err_EDefekt_MoKomp_TNCTOC
      RP_IF_EASV5_Err_EDefekt_TSens_TF_XIX_Klima: required-interface=IF_EASV5_Err_EDefekt_TSens_TF
      RP_IF_EASV5_Err_EDefekt_TSens_TNCTOC_XIX_Klima: required-interface=IF_EASV5_Err_EDefekt_TSens_TNCTOC
      RP_IF_EASV5_Err_Notlaufpos_TF_XIX_Klima: required-interface=IF_EASV5_Err_Notlaufpos_TF
      RP_IF_EASV5_Err_Notlaufpos_TNCTOC_XIX_Klima: required-interface=IF_EASV5_Err_Notlaufpos_TNCTOC
      RP_IF_EASV5_Err_RAMROMNADChange_TF_XIX_Klima: required-interface=IF_EASV5_Err_RAMROMNADChange_TF
      RP_IF_EASV5_Err_RAMROMNADChange_TNCTOC_XIX_Klima: required-interface=IF_EASV5_Err_RAMROMNADChange_TNCTOC
      RP_IF_EASV5_Err_Ueberspannung_TF_XIX_Klima: required-interface=IF_EASV5_Err_Ueberspannung_TF
      RP_IF_EASV5_Err_Ueberspannung_TNCTOC_XIX_Klima: required-interface=IF_EASV5_Err_Ueberspannung_TNCTOC
      RP_IF_EASV5_Err_Uebertemperatur_TF_XIX_Klima: required-interface=IF_EASV5_Err_Uebertemperatur_TF
      RP_IF_EASV5_Err_Uebertemperatur_TNCTOC_XIX_Klima: required-interface=IF_EASV5_Err_Uebertemperatur_TNCTOC
      RP_IF_EASV5_Err_Unterspannung_TF_XIX_Klima: required-interface=IF_EASV5_Err_Unterspannung_TF
      RP_IF_EASV5_Err_Unterspannung_TNCTOC_XIX_Klima: required-interface=IF_EASV5_Err_Unterspannung_TNCTOC
      RP_IF_EASV5_ErrMem_State_XIX_Klima: required-interface=IF_EASV5_ErrMem_State
      RP_IF_EASV5_Geschwindigkeitsstatus_XIX_Klima: required-interface=IF_EASV5_Geschwindigkeitsstatus
      RP_IF_EASV5_Ist_Position_Aktuator_XIX_Klima: required-interface=IF_EASV5_Ist_Position_Aktuator
      RP_IF_EASV5_ResponseError_TNCTOC_XIX_Klima: required-interface=IF_EASV5_ResponseError_TNCTOC
      RP_IF_EASV5_ResponseError_XIX_Klima: required-interface=IF_EASV5_ResponseError
      RP_IF_EASV5_Spulenbestromung_XIX_Klima: required-interface=IF_EASV5_Spulenbestromung
      RP_IF_EASV5_Temp_Warning_XIX_Klima: required-interface=IF_EASV5_Temp_Warning
      RP_IF_EASV5_temp_XIX_Klima: required-interface=IF_EASV5_temp
      RP_IF_eCall_Funktionsstatus_02_XIX_Klima: required-interface=IF_eCall_Funktionsstatus_02
      RP_IF_EKK4_Comp_Error_Mask_Nr_XIX_Klima: required-interface=IF_EKK4_Comp_Error_Mask_Nr
      RP_IF_EKK4_COMP_SPEED_XIX_Klima: required-interface=IF_EKK4_COMP_SPEED
      RP_IF_EKK4_COMP_ST_XIX_Klima: required-interface=IF_EKK4_COMP_ST
      RP_IF_EKK4_Err_Ind_Nr_1_8_15_22_XIX_Klima: required-interface=IF_EKK4_Err_Ind_Nr_1_8_15_22
      RP_IF_EKK4_Err_Ind_Nr_2_9_16_23_XIX_Klima: required-interface=IF_EKK4_Err_Ind_Nr_2_9_16_23
      RP_IF_EKK4_Err_Ind_Nr_3_10_17_24_XIX_Klima: required-interface=IF_EKK4_Err_Ind_Nr_3_10_17_24
      RP_IF_EKK4_Err_Ind_Nr_4_11_18_25_XIX_Klima: required-interface=IF_EKK4_Err_Ind_Nr_4_11_18_25
      RP_IF_EKK4_Err_Ind_Nr_5_12_19_26_XIX_Klima: required-interface=IF_EKK4_Err_Ind_Nr_5_12_19_26
      RP_IF_EKK4_Err_Ind_Nr_6_13_20_27_XIX_Klima: required-interface=IF_EKK4_Err_Ind_Nr_6_13_20_27
      RP_IF_EKK4_Err_Ind_Nr_7_14_21_28_XIX_Klima: required-interface=IF_EKK4_Err_Ind_Nr_7_14_21_28
      RP_IF_EKK4_Err_Ind_TF_1_7_XIX_Klima: required-interface=IF_EKK4_Err_Ind_TF_1_7
      RP_IF_EKK4_Err_Ind_TF_2_8_XIX_Klima: required-interface=IF_EKK4_Err_Ind_TF_2_8
      RP_IF_EKK4_Err_Ind_TF_3_9_XIX_Klima: required-interface=IF_EKK4_Err_Ind_TF_3_9
      RP_IF_EKK4_Err_Ind_TF_4_10_XIX_Klima: required-interface=IF_EKK4_Err_Ind_TF_4_10
      RP_IF_EKK4_Err_Ind_TF_5_11_XIX_Klima: required-interface=IF_EKK4_Err_Ind_TF_5_11
      RP_IF_EKK4_Err_Ind_TF_6_12_XIX_Klima: required-interface=IF_EKK4_Err_Ind_TF_6_12
      RP_IF_EKK4_ErrMem_State_XIX_Klima: required-interface=IF_EKK4_ErrMem_State
      RP_IF_EKK4_Fehler_AE_XIX_Klima: required-interface=IF_EKK4_Fehler_AE
      RP_IF_EKK4_HIGH_VOLTAGE_XIX_Klima: required-interface=IF_EKK4_HIGH_VOLTAGE
      RP_IF_EKK4_INPUT_CURRENT_XIX_Klima: required-interface=IF_EKK4_INPUT_CURRENT
      RP_IF_EKK4_INV_TEMP_XIX_Klima: required-interface=IF_EKK4_INV_TEMP
      RP_IF_EKK4_Level_Rsp_XIX_Klima: required-interface=IF_EKK4_Level_Rsp
      RP_IF_EKK4_Match_XIX_Klima: required-interface=IF_EKK4_Match
      RP_IF_EKK4_MUX_Err_Ind_XIX_Klima: required-interface=IF_EKK4_MUX_Err_Ind
      RP_IF_EKK4_Number_of_Err_Ind_TF_XIX_Klima: required-interface=IF_EKK4_Number_of_Err_Ind_TF
      RP_IF_EKK4_ParameterChange_XIX_Klima: required-interface=IF_EKK4_ParameterChange
      RP_IF_EKK4_Q_High_Voltage_XIX_Klima: required-interface=IF_EKK4_Q_High_Voltage
      RP_IF_EKK4_Reason_Err_Ind_TF_1_7_XIX_Klima: required-interface=IF_EKK4_Reason_Err_Ind_TF_1_7
      RP_IF_EKK4_Reason_Err_Ind_TF_2_8_XIX_Klima: required-interface=IF_EKK4_Reason_Err_Ind_TF_2_8
      RP_IF_EKK4_Reason_Err_Ind_TF_3_9_XIX_Klima: required-interface=IF_EKK4_Reason_Err_Ind_TF_3_9
      RP_IF_EKK4_Reason_Err_Ind_TF_4_10_XIX_Klima: required-interface=IF_EKK4_Reason_Err_Ind_TF_4_10
      RP_IF_EKK4_Reason_Err_Ind_TF_5_11_XIX_Klima: required-interface=IF_EKK4_Reason_Err_Ind_TF_5_11
      RP_IF_EKK4_Reason_Err_Ind_TF_6_12_XIX_Klima: required-interface=IF_EKK4_Reason_Err_Ind_TF_6_12
      RP_IF_EKK4_ResponseError_XIX_Klima: required-interface=IF_EKK4_ResponseError
      RP_IF_EKK4_TF_Change_XIX_Klima: required-interface=IF_EKK4_TF_Change
      RP_IF_EM1_MinVorlauftemperatur_XIX_Klima: required-interface=IF_EM1_MinVorlauftemperatur
      RP_IF_ESC_Anf_KV_XIX_Klima: required-interface=IF_ESC_Anf_KV
      RP_IF_ESC_Anf_Mindestreku_XIX_Klima: required-interface=IF_ESC_Anf_Mindestreku
      RP_IF_ESP_QBit_v_Signal_XIX_Klima: required-interface=IF_ESP_QBit_v_Signal
      RP_IF_ESP_v_Signal_XIX_Klima: required-interface=IF_ESP_v_Signal
      RP_IF_eTM_Batterieheizen_Anf_XIX_Klima: required-interface=IF_eTM_Batterieheizen_Anf
      RP_IF_eTM_BMS_Pumpe1_Befuellung_XIX_Klima: required-interface=IF_eTM_BMS_Pumpe1_Befuellung
      RP_IF_eTM_BMS_Pumpe1_SollAnsteuerung_XIX_Klima: required-interface=IF_eTM_BMS_Pumpe1_SollAnsteuerung
      RP_IF_eTM_BMS_ThermischeIstLeistung_XIX_Klima: required-interface=IF_eTM_BMS_ThermischeIstLeistung
      RP_IF_eTM_BMS_Ventil1_Befuellung_XIX_Klima: required-interface=IF_eTM_BMS_Ventil1_Befuellung
      RP_IF_eTM_BMS_Ventil2_Befuellung_XIX_Klima: required-interface=IF_eTM_BMS_Ventil2_Befuellung
      RP_IF_eTM_HVBatt_IstVolumenstrom_XIX_Klima: required-interface=IF_eTM_HVBatt_IstVolumenstrom
      RP_IF_eTM_HWT_IstVolumenstrom_XIX_Klima: required-interface=IF_eTM_HWT_IstVolumenstrom
      RP_IF_eTM_Ist_rLM_XIX_Klima: required-interface=IF_eTM_Ist_rLM
      RP_IF_eTM_Kuehlung_Status_XIX_Klima: required-interface=IF_eTM_Kuehlung_Status
      RP_IF_eTM_Pumpe1_Status_XIX_Klima: required-interface=IF_eTM_Pumpe1_Status
      RP_IF_eTM_Pumpe1_Volumenstrom_XIX_Klima: required-interface=IF_eTM_Pumpe1_Volumenstrom
      RP_IF_eTM_Pumpe2_Status_XIX_Klima: required-interface=IF_eTM_Pumpe2_Status
      RP_IF_eTM_Pumpe2_Volumenstrom_XIX_Klima: required-interface=IF_eTM_Pumpe2_Volumenstrom
      RP_IF_eTM_PumpeAntrieb_Ansteuerung_XIX_Klima: required-interface=IF_eTM_PumpeAntrieb_Ansteuerung
      RP_IF_eTM_PumpeBat_Ansteuerung_XIX_Klima: required-interface=IF_eTM_PumpeBat_Ansteuerung
      RP_IF_eTM_PumpeHWT_Ansteuerung_XIX_Klima: required-interface=IF_eTM_PumpeHWT_Ansteuerung
      RP_IF_eTM_PV1_Ansteuerung_XIX_Klima: required-interface=IF_eTM_PV1_Ansteuerung
      RP_IF_eTM_PV2_Ansteuerung_XIX_Klima: required-interface=IF_eTM_PV2_Ansteuerung
      RP_IF_eTM_PWR_MinVorlaufTemp_XIX_Klima: required-interface=IF_eTM_PWR_MinVorlaufTemp
      RP_IF_eTM_Temperatur_1_XIX_Klima: required-interface=IF_eTM_Temperatur_1
      RP_IF_eTM_Temperatur_2_XIX_Klima: required-interface=IF_eTM_Temperatur_2
      RP_IF_eTM_Ventil{1..3}_Status_XIX_Klima: required-interface=IF_eTM_Ventil{1..3}_Status
      RP_IF_eTM_Wasserheizer_IstVolumenstrom_XIX_Klima: required-interface=IF_eTM_Wasserheizer_IstVolumenstrom
      RP_IF_eTM_Wasserheizer_SollTemp_Ausgng_XIX_Klima: required-interface=IF_eTM_Wasserheizer_SollTemp_Ausgng
      RP_IF_EXV1_Err_Blockierung_TF_XIX_Klima: required-interface=IF_EXV1_Err_Blockierung_TF
      RP_IF_EXV1_Err_Blockierung_TNCTOC_XIX_Klima: required-interface=IF_EXV1_Err_Blockierung_TNCTOC
      RP_IF_EXV1_Err_EDefekt_MoKomp_TF_XIX_Klima: required-interface=IF_EXV1_Err_EDefekt_MoKomp_TF
      RP_IF_EXV1_Err_EDefekt_MoKomp_TNCTOC_XIX_Klima: required-interface=IF_EXV1_Err_EDefekt_MoKomp_TNCTOC
      RP_IF_EXV1_Err_EDefekt_TSens_TF_XIX_Klima: required-interface=IF_EXV1_Err_EDefekt_TSens_TF
      RP_IF_EXV1_Err_EDefekt_TSens_TNCTOC_XIX_Klima: required-interface=IF_EXV1_Err_EDefekt_TSens_TNCTOC
      RP_IF_EXV1_Err_Notlaufpos_TF_XIX_Klima: required-interface=IF_EXV1_Err_Notlaufpos_TF
      RP_IF_EXV1_Err_Notlaufpos_TNCTOC_XIX_Klima: required-interface=IF_EXV1_Err_Notlaufpos_TNCTOC
      RP_IF_EXV1_Err_RAMROMNADChange_TF_XIX_Klima: required-interface=IF_EXV1_Err_RAMROMNADChange_TF
      RP_IF_EXV1_Err_RAMROMNADChange_TNCTOC_XIX_Klima: required-interface=IF_EXV1_Err_RAMROMNADChange_TNCTOC
      RP_IF_EXV1_Err_Ueberspannung_TF_XIX_Klima: required-interface=IF_EXV1_Err_Ueberspannung_TF
      RP_IF_EXV1_Err_Ueberspannung_TNCTOC_XIX_Klima: required-interface=IF_EXV1_Err_Ueberspannung_TNCTOC
      RP_IF_EXV1_Err_Uebertemperatur_TF_XIX_Klima: required-interface=IF_EXV1_Err_Uebertemperatur_TF
      RP_IF_EXV1_Err_Uebertemperatur_TNCTOC_XIX_Klima: required-interface=IF_EXV1_Err_Uebertemperatur_TNCTOC
      RP_IF_EXV1_Err_Unterspannung_TF_XIX_Klima: required-interface=IF_EXV1_Err_Unterspannung_TF
      RP_IF_EXV1_Err_Unterspannung_TNCTOC_XIX_Klima: required-interface=IF_EXV1_Err_Unterspannung_TNCTOC
      RP_IF_EXV1_ErrMem_State_XIX_Klima: required-interface=IF_EXV1_ErrMem_State
      RP_IF_EXV1_Geschwindigkeitsstatus_XIX_Klima: required-interface=IF_EXV1_Geschwindigkeitsstatus
      RP_IF_EXV1_Ist_Position_Aktuator_XIX_Klima: required-interface=IF_EXV1_Ist_Position_Aktuator
      RP_IF_EXV1_ResponseError_TNCTOC_XIX_Klima: required-interface=IF_EXV1_ResponseError_TNCTOC
      RP_IF_EXV1_ResponseError_XIX_Klima: required-interface=IF_EXV1_ResponseError
      RP_IF_EXV1_Spulenbestromung_XIX_Klima: required-interface=IF_EXV1_Spulenbestromung
      RP_IF_EXV1_Temp_Warning_XIX_Klima: required-interface=IF_EXV1_Temp_Warning
      RP_IF_EXV1_Temp_XIX_Klima: required-interface=IF_EXV1_Temp
      RP_IF_EXV2_Err_Blockierung_TF_XIX_Klima: required-interface=IF_EXV2_Err_Blockierung_TF
      RP_IF_EXV2_Err_Blockierung_TNCTOC_XIX_Klima: required-interface=IF_EXV2_Err_Blockierung_TNCTOC
      RP_IF_EXV2_Err_EDefekt_MoKomp_TF_XIX_Klima: required-interface=IF_EXV2_Err_EDefekt_MoKomp_TF
      RP_IF_EXV2_Err_EDefekt_MoKomp_TNCTOC_XIX_Klima: required-interface=IF_EXV2_Err_EDefekt_MoKomp_TNCTOC
      RP_IF_EXV2_Err_EDefekt_TSens_TF_XIX_Klima: required-interface=IF_EXV2_Err_EDefekt_TSens_TF
      RP_IF_EXV2_Err_EDefekt_TSens_TNCTOC_XIX_Klima: required-interface=IF_EXV2_Err_EDefekt_TSens_TNCTOC
      RP_IF_EXV2_Err_Notlaufpos_TF_XIX_Klima: required-interface=IF_EXV2_Err_Notlaufpos_TF
      RP_IF_EXV2_Err_Notlaufpos_TNCTOC_XIX_Klima: required-interface=IF_EXV2_Err_Notlaufpos_TNCTOC
      RP_IF_EXV2_Err_RAMROMNADChange_TF_XIX_Klima: required-interface=IF_EXV2_Err_RAMROMNADChange_TF
      RP_IF_EXV2_Err_RAMROMNADChange_TNCTOC_XIX_Klima: required-interface=IF_EXV2_Err_RAMROMNADChange_TNCTOC
      RP_IF_EXV2_Err_Ueberspannung_TF_XIX_Klima: required-interface=IF_EXV2_Err_Ueberspannung_TF
      RP_IF_EXV2_Err_Ueberspannung_TNCTOC_XIX_Klima: required-interface=IF_EXV2_Err_Ueberspannung_TNCTOC
      RP_IF_EXV2_Err_Uebertemperatur_TF_XIX_Klima: required-interface=IF_EXV2_Err_Uebertemperatur_TF
      RP_IF_EXV2_Err_Uebertemperatur_TNCTOC_XIX_Klima: required-interface=IF_EXV2_Err_Uebertemperatur_TNCTOC
      RP_IF_EXV2_Err_Unterspannung_TF_XIX_Klima: required-interface=IF_EXV2_Err_Unterspannung_TF
      RP_IF_EXV2_Err_Unterspannung_TNCTOC_XIX_Klima: required-interface=IF_EXV2_Err_Unterspannung_TNCTOC
      RP_IF_EXV2_ErrMem_State_XIX_Klima: required-interface=IF_EXV2_ErrMem_State
      RP_IF_EXV2_Geschwindigkeitsstatus_XIX_Klima: required-interface=IF_EXV2_Geschwindigkeitsstatus
      RP_IF_EXV2_Ist_Position_Aktuator_XIX_Klima: required-interface=IF_EXV2_Ist_Position_Aktuator
      RP_IF_EXV2_ResponseError_TNCTOC_XIX_Klima: required-interface=IF_EXV2_ResponseError_TNCTOC
      RP_IF_EXV2_ResponseError_XIX_Klima: required-interface=IF_EXV2_ResponseError
      RP_IF_EXV2_Spulenbestromung_XIX_Klima: required-interface=IF_EXV2_Spulenbestromung
      RP_IF_EXV2_Temp_Warning_XIX_Klima: required-interface=IF_EXV2_Temp_Warning
      RP_IF_EXV2_Temp_XIX_Klima: required-interface=IF_EXV2_Temp
      RP_IF_EXV3_Err_Blockierung_TF_XIX_Klima: required-interface=IF_EXV3_Err_Blockierung_TF
      RP_IF_EXV3_Err_Blockierung_TNCTOC_XIX_Klima: required-interface=IF_EXV3_Err_Blockierung_TNCTOC
      RP_IF_EXV3_Err_EDefekt_MoKomp_TF_XIX_Klima: required-interface=IF_EXV3_Err_EDefekt_MoKomp_TF
      RP_IF_EXV3_Err_EDefekt_MoKomp_TNCTOC_XIX_Klima: required-interface=IF_EXV3_Err_EDefekt_MoKomp_TNCTOC
      RP_IF_EXV3_Err_EDefekt_TSens_TF_XIX_Klima: required-interface=IF_EXV3_Err_EDefekt_TSens_TF
      RP_IF_EXV3_Err_EDefekt_TSens_TNCTOC_XIX_Klima: required-interface=IF_EXV3_Err_EDefekt_TSens_TNCTOC
      RP_IF_EXV3_Err_Notlaufpos_TF_XIX_Klima: required-interface=IF_EXV3_Err_Notlaufpos_TF
      RP_IF_EXV3_Err_Notlaufpos_TNCTOC_XIX_Klima: required-interface=IF_EXV3_Err_Notlaufpos_TNCTOC
      RP_IF_EXV3_Err_RAMROMNADChange_TF_XIX_Klima: required-interface=IF_EXV3_Err_RAMROMNADChange_TF
      RP_IF_EXV3_Err_RAMROMNADChange_TNCTOC_XIX_Klima: required-interface=IF_EXV3_Err_RAMROMNADChange_TNCTOC
      RP_IF_EXV3_Err_Ueberspannung_TF_XIX_Klima: required-interface=IF_EXV3_Err_Ueberspannung_TF
      RP_IF_EXV3_Err_Ueberspannung_TNCTOC_XIX_Klima: required-interface=IF_EXV3_Err_Ueberspannung_TNCTOC
      RP_IF_EXV3_Err_Uebertemperatur_TF_XIX_Klima: required-interface=IF_EXV3_Err_Uebertemperatur_TF
      RP_IF_EXV3_Err_Uebertemperatur_TNCTOC_XIX_Klima: required-interface=IF_EXV3_Err_Uebertemperatur_TNCTOC
      RP_IF_EXV3_Err_Unterspannung_TF_XIX_Klima: required-interface=IF_EXV3_Err_Unterspannung_TF
      RP_IF_EXV3_Err_Unterspannung_TNCTOC_XIX_Klima: required-interface=IF_EXV3_Err_Unterspannung_TNCTOC
      RP_IF_EXV3_ErrMem_State_XIX_Klima: required-interface=IF_EXV3_ErrMem_State
      RP_IF_EXV3_Geschwindigkeitsstatus_XIX_Klima: required-interface=IF_EXV3_Geschwindigkeitsstatus
      RP_IF_EXV3_Ist_Position_Aktuator_XIX_Klima: required-interface=IF_EXV3_Ist_Position_Aktuator
      RP_IF_EXV3_ResponseError_TNCTOC_XIX_Klima: required-interface=IF_EXV3_ResponseError_TNCTOC
      RP_IF_EXV3_ResponseError_XIX_Klima: required-interface=IF_EXV3_ResponseError
      RP_IF_EXV3_Spulenbestromung_XIX_Klima: required-interface=IF_EXV3_Spulenbestromung
      RP_IF_EXV3_Temp_Warning_XIX_Klima: required-interface=IF_EXV3_Temp_Warning
      RP_IF_EXV3_Temp_XIX_Klima: required-interface=IF_EXV3_Temp
      RP_IF_EXV4_Err_Blockierung_TF_XIX_Klima: required-interface=IF_EXV4_Err_Blockierung_TF
      RP_IF_EXV4_Err_Blockierung_TNCTOC_XIX_Klima: required-interface=IF_EXV4_Err_Blockierung_TNCTOC
      RP_IF_EXV4_Err_EDefekt_MoKomp_TF_XIX_Klima: required-interface=IF_EXV4_Err_EDefekt_MoKomp_TF
      RP_IF_EXV4_Err_EDefekt_MoKomp_TNCTOC_XIX_Klima: required-interface=IF_EXV4_Err_EDefekt_MoKomp_TNCTOC
      RP_IF_EXV4_Err_EDefekt_TSens_TF_XIX_Klima: required-interface=IF_EXV4_Err_EDefekt_TSens_TF
      RP_IF_EXV4_Err_EDefekt_TSens_TNCTOC_XIX_Klima: required-interface=IF_EXV4_Err_EDefekt_TSens_TNCTOC
      RP_IF_EXV4_Err_Notlaufpos_TF_XIX_Klima: required-interface=IF_EXV4_Err_Notlaufpos_TF
      RP_IF_EXV4_Err_Notlaufpos_TNCTOC_XIX_Klima: required-interface=IF_EXV4_Err_Notlaufpos_TNCTOC
      RP_IF_EXV4_Err_RAMROMNADChange_TF_XIX_Klima: required-interface=IF_EXV4_Err_RAMROMNADChange_TF
      RP_IF_EXV4_Err_RAMROMNADChange_TNCTOC_XIX_Klima: required-interface=IF_EXV4_Err_RAMROMNADChange_TNCTOC
      RP_IF_EXV4_Err_Ueberspannung_TF_XIX_Klima: required-interface=IF_EXV4_Err_Ueberspannung_TF
      RP_IF_EXV4_Err_Ueberspannung_TNCTOC_XIX_Klima: required-interface=IF_EXV4_Err_Ueberspannung_TNCTOC
      RP_IF_EXV4_Err_Uebertemperatur_TF_XIX_Klima: required-interface=IF_EXV4_Err_Uebertemperatur_TF
      RP_IF_EXV4_Err_Uebertemperatur_TNCTOC_XIX_Klima: required-interface=IF_EXV4_Err_Uebertemperatur_TNCTOC
      RP_IF_EXV4_Err_Unterspannung_TF_XIX_Klima: required-interface=IF_EXV4_Err_Unterspannung_TF
      RP_IF_EXV4_Err_Unterspannung_TNCTOC_XIX_Klima: required-interface=IF_EXV4_Err_Unterspannung_TNCTOC
      RP_IF_EXV4_ErrMem_State_XIX_Klima: required-interface=IF_EXV4_ErrMem_State
      RP_IF_EXV4_Geschwindigkeitsstatus_XIX_Klima: required-interface=IF_EXV4_Geschwindigkeitsstatus
      RP_IF_EXV4_Ist_Position_Aktuator_XIX_Klima: required-interface=IF_EXV4_Ist_Position_Aktuator
      RP_IF_EXV4_ResponseError_TNCTOC_XIX_Klima: required-interface=IF_EXV4_ResponseError_TNCTOC
      RP_IF_EXV4_ResponseError_XIX_Klima: required-interface=IF_EXV4_ResponseError
      RP_IF_EXV4_Spulenbestromung_XIX_Klima: required-interface=IF_EXV4_Spulenbestromung
      RP_IF_EXV4_Temp_Warning_XIX_Klima: required-interface=IF_EXV4_Temp_Warning
      RP_IF_EXV4_Temp_XIX_Klima: required-interface=IF_EXV4_Temp
      RP_IF_FoD_Transmission_Info_XIX_Klima: required-interface=IF_FoD_Transmission_Info
      RP_IF_FRS_active_container_XIX_Klima: required-interface=IF_FRS_active_container
      RP_IF_FRS_CurrentIntensity_XIX_Klima: required-interface=IF_FRS_CurrentIntensity
      RP_IF_FRS_Expiry_Container_{1..3}_XIX_Klima: required-interface=IF_FRS_Expiry_Container_{1..3}
      RP_IF_FRS_Fan_status_XIX_Klima: required-interface=IF_FRS_Fan_status
      RP_IF_FRS_FragranceID_Container_{1..3}_XIX_Klima: required-interface=IF_FRS_FragranceID_Container_{1..3}
      RP_IF_FRS_Level_Container_{1..3}_XIX_Klima: required-interface=IF_FRS_Level_Container_{1..3}
      RP_IF_FRS_ResponseError_XIX_Klima: required-interface=IF_FRS_ResponseError
      RP_IF_FRS_Status_UBatt_XIX_Klima: required-interface=IF_FRS_Status_UBatt
      RP_IF_FRS_Status_XIX_Klima: required-interface=IF_FRS_Status
      RP_IF_FRS_Stepper_Status_XIX_Klima: required-interface=IF_FRS_Stepper_Status
      RP_IF_FS_Luftfeuchte_rel_XIX_Klima: required-interface=IF_FS_Luftfeuchte_rel
      RP_IF_FS_ResponseError_XIX_Klima: required-interface=IF_FS_ResponseError
      RP_IF_FS_Taupunkt_XIX_Klima: required-interface=IF_FS_Taupunkt
      RP_IF_FS_Temp_Scheibe_XIX_Klima: required-interface=IF_FS_Temp_Scheibe
      RP_IF_FS_Temp_Sensor_XIX_Klima: required-interface=IF_FS_Temp_Sensor
      RP_IF_FSA_HW_XIX_Klima: required-interface=IF_FSA_HW
      RP_IF_FSA_Luftfeuchte_rel_XIX_Klima: required-interface=IF_FSA_Luftfeuchte_rel
      RP_IF_FSA_ResponseError_XIX_Klima: required-interface=IF_FSA_ResponseError
      RP_IF_FSA_Sensorheizung_Status_XIX_Klima: required-interface=IF_FSA_Sensorheizung_Status
      RP_IF_FSA_SW_XIX_Klima: required-interface=IF_FSA_SW
      RP_IF_FSA_Taupunkt_XIX_Klima: required-interface=IF_FSA_Taupunkt
      RP_IF_FSA_Temp_Luft_XIX_Klima: required-interface=IF_FSA_Temp_Luft
      RP_IF_FSA_Temp_Sensor_XIX_Klima: required-interface=IF_FSA_Temp_Sensor
      RP_IF_FT_FH_Oeffnung_XIX_Klima: required-interface=IF_FT_FH_Oeffnung
      RP_IF_FT_Tuer_geoeffnet_XIX_Klima: required-interface=IF_FT_Tuer_geoeffnet
      RP_IF_GNSS_Breite_Ortung_XIX_Klima: required-interface=IF_GNSS_Breite_Ortung
      RP_IF_GNSS_DR_Breite_Ortung_XIX_Klima: required-interface=IF_GNSS_DR_Breite_Ortung
      RP_IF_GNSS_DR_Laenge_Ortung_XIX_Klima: required-interface=IF_GNSS_DR_Laenge_Ortung
      RP_IF_GNSS_DR_Ortung_Ausrichtung_XIX_Klima: required-interface=IF_GNSS_DR_Ortung_Ausrichtung
      RP_IF_GNSS_DR_Ortung_Hoehe_XIX_Klima: required-interface=IF_GNSS_DR_Ortung_Hoehe
      RP_IF_GNSS_DR_Richtung_Breite_Ortung_XIX_Klima: required-interface=IF_GNSS_DR_Richtung_Breite_Ortung
      RP_IF_GNSS_DR_Richtung_Laenge_Ortung_XIX_Klima: required-interface=IF_GNSS_DR_Richtung_Laenge_Ortung
      RP_IF_GNSS_DR_UTC_Zeit_XIX_Klima: required-interface=IF_GNSS_DR_UTC_Zeit
      RP_IF_GNSS_Laenge_Ortung_XIX_Klima: required-interface=IF_GNSS_Laenge_Ortung
      RP_IF_GNSS_Ortung_Ausrichtung_XIX_Klima: required-interface=IF_GNSS_Ortung_Ausrichtung
      RP_IF_GNSS_Ortung_Hoehe_XIX_Klima: required-interface=IF_GNSS_Ortung_Hoehe
      RP_IF_GNSS_Richtung_Breite_Ortung_XIX_Klima: required-interface=IF_GNSS_Richtung_Breite_Ortung
      RP_IF_GNSS_Richtung_Laenge_Ortung_XIX_Klima: required-interface=IF_GNSS_Richtung_Laenge_Ortung
      RP_IF_GNSS_UTC_Zeit_XIX_Klima: required-interface=IF_GNSS_UTC_Zeit
      RP_IF_HBFS_FH_Oeffnung_XIX_Klima: required-interface=IF_HBFS_FH_Oeffnung
      RP_IF_HBFS_Tuer_geoeffnet_XIX_Klima: required-interface=IF_HBFS_Tuer_geoeffnet
      RP_IF_HDSG_Anf_Umluftklappe_XIX_Klima: required-interface=IF_HDSG_Anf_Umluftklappe
      RP_IF_HFS_FH_Oeffnung_XIX_Klima: required-interface=IF_HFS_FH_Oeffnung
      RP_IF_HFS_Tuer_geoeffnet_XIX_Klima: required-interface=IF_HFS_Tuer_geoeffnet
      RP_IF_HLR_FSH_Freigabe_XIX_Klima: required-interface=IF_HLR_FSH_Freigabe
      RP_IF_HLR_HSH_Freigabe_XIX_Klima: required-interface=IF_HLR_HSH_Freigabe
      RP_IF_HLR_LRH_Freigabe_XIX_Klima: required-interface=IF_HLR_LRH_Freigabe
      RP_IF_HLR_SIH_Freigabe_HL_XIX_Klima: required-interface=IF_HLR_SIH_Freigabe_HL
      RP_IF_HLR_SIH_Freigabe_HR_XIX_Klima: required-interface=IF_HLR_SIH_Freigabe_HR
      RP_IF_HLR_SIH_Freigabe_VL_XIX_Klima: required-interface=IF_HLR_SIH_Freigabe_VL
      RP_IF_HLR_SIH_Freigabe_VR_XIX_Klima: required-interface=IF_HLR_SIH_Freigabe_VR
      RP_IF_HLR_SIL_Freigabe_HL_XIX_Klima: required-interface=IF_HLR_SIL_Freigabe_HL
      RP_IF_HLR_SIL_Freigabe_HR_XIX_Klima: required-interface=IF_HLR_SIL_Freigabe_HR
      RP_IF_HLR_SIL_Freigabe_VL_XIX_Klima: required-interface=IF_HLR_SIL_Freigabe_VL
      RP_IF_HLR_SIL_Freigabe_VR_XIX_Klima: required-interface=IF_HLR_SIL_Freigabe_VR
      RP_IF_HSH_Status_XIX_Klima: required-interface=IF_HSH_Status
      RP_IF_HV_Bordnetz_aktiv_XIX_Klima: required-interface=IF_HV_Bordnetz_aktiv
      RP_IF_HV_Bordnetz_Fehler_XIX_Klima: required-interface=IF_HV_Bordnetz_Fehler
      RP_IF_HV_H3_Err_intern_XIX_Klima: required-interface=IF_HV_H3_Err_intern
      RP_IF_HV_H3_Err_Leckagestrom_XIX_Klima: required-interface=IF_HV_H3_Err_Leckagestrom
      RP_IF_HV_H3_Err_Temperaturschutz_XIX_Klima: required-interface=IF_HV_H3_Err_Temperaturschutz
      RP_IF_HV_H3_Err_Ueberstromabschaltung_XIX_Klima: required-interface=IF_HV_H3_Err_Ueberstromabschaltung
      RP_IF_HV_H3_HIGH_VOLTAGE_ERR_XIX_Klima: required-interface=IF_HV_H3_HIGH_VOLTAGE_ERR
      RP_IF_HV_H3_HIGH_VOLTAGE_XIX_Klima: required-interface=IF_HV_H3_HIGH_VOLTAGE
      RP_IF_HV_H3_I_ist_XIX_Klima: required-interface=IF_HV_H3_I_ist
      RP_IF_HV_H3_ResponseError_XIX_Klima: required-interface=IF_HV_H3_ResponseError
      RP_IF_HV_H3_Status_Heizer_XIX_Klima: required-interface=IF_HV_H3_Status_Heizer
      RP_IF_HV_H3_Status_Heizkreis_{1..4}_XIX_Klima: required-interface=IF_HV_H3_Status_Heizkreis_{1..4}
      RP_IF_HV_H3_Status_UBatt_NV_XIX_Klima: required-interface=IF_HV_H3_Status_UBatt_NV
      RP_IF_HV_H3_Temp_PCB_XIX_Klima: required-interface=IF_HV_H3_Temp_PCB
      RP_IF_HV_H3_TimeOut_Fehler_XIX_Klima: required-interface=IF_HV_H3_TimeOut_Fehler
      RP_IF_HV_H3_UBatt_NV_XIX_Klima: required-interface=IF_HV_H3_UBatt_NV
      RP_IF_HV_H3b_Err_intern_XIX_Klima: required-interface=IF_HV_H3b_Err_intern
      RP_IF_HV_H3b_Err_Leckagestrom_XIX_Klima: required-interface=IF_HV_H3b_Err_Leckagestrom
      RP_IF_HV_H3b_Err_Temperaturschutz_XIX_Klima: required-interface=IF_HV_H3b_Err_Temperaturschutz
      RP_IF_HV_H3b_Err_Ueberstromabschaltung_XIX_Klima: required-interface=IF_HV_H3b_Err_Ueberstromabschaltung
      RP_IF_HV_H3b_HIGH_VOLTAGE_ERR_XIX_Klima: required-interface=IF_HV_H3b_HIGH_VOLTAGE_ERR
      RP_IF_HV_H3b_HIGH_VOLTAGE_XIX_Klima: required-interface=IF_HV_H3b_HIGH_VOLTAGE
      RP_IF_HV_H3b_I_ist_XIX_Klima: required-interface=IF_HV_H3b_I_ist
      RP_IF_HV_H3b_ResponseError_XIX_Klima: required-interface=IF_HV_H3b_ResponseError
      RP_IF_HV_H3b_Status_Heizer_XIX_Klima: required-interface=IF_HV_H3b_Status_Heizer
      RP_IF_HV_H3b_Status_Heizkreis_{1..4}_XIX_Klima: required-interface=IF_HV_H3b_Status_Heizkreis_{1..4}
      RP_IF_HV_H3b_Status_UBatt_NV_XIX_Klima: required-interface=IF_HV_H3b_Status_UBatt_NV
      RP_IF_HV_H3b_Temp_PCB_XIX_Klima: required-interface=IF_HV_H3b_Temp_PCB
      RP_IF_HV_H3b_TimeOut_Fehler_XIX_Klima: required-interface=IF_HV_H3b_TimeOut_Fehler
      RP_IF_HV_H3b_UBatt_NV_XIX_Klima: required-interface=IF_HV_H3b_UBatt_NV
      RP_IF_HV_H6_aktive_Entladung_Status_XIX_Klima: required-interface=IF_HV_H6_aktive_Entladung_Status
      RP_IF_HV_H6_Err_Leckagestrom_XIX_Klima: required-interface=IF_HV_H6_Err_Leckagestrom
      RP_IF_HV_H6_Error_HVH_XIX_Klima: required-interface=IF_HV_H6_Error_HVH
      RP_IF_HV_H6_Heizmedium_Sensor_1_XIX_Klima: required-interface=IF_HV_H6_Heizmedium_Sensor_1
      RP_IF_HV_H6_Heizmedium_Sensor_2_XIX_Klima: required-interface=IF_HV_H6_Heizmedium_Sensor_2
      RP_IF_HV_H6_High_Voltage_XIX_Klima: required-interface=IF_HV_H6_High_Voltage
      RP_IF_HV_H6_HV_ERR_XIX_Klima: required-interface=IF_HV_H6_HV_ERR
      RP_IF_HV_H6_I_ist_XIX_Klima: required-interface=IF_HV_H6_I_ist
      RP_IF_HV_H6_PTC_ResponseError_XIX_Klima: required-interface=IF_HV_H6_PTC_ResponseError
      RP_IF_HV_H6_Status_HVH_XIX_Klima: required-interface=IF_HV_H6_Status_HVH
      RP_IF_HV_H6_Status_UBatt_XIX_Klima: required-interface=IF_HV_H6_Status_UBatt
      RP_IF_HV_H6_Temp_PCB_XIX_Klima: required-interface=IF_HV_H6_Temp_PCB
      RP_IF_HV_H6_UBatt_XIX_Klima: required-interface=IF_HV_H6_UBatt
      RP_IF_HVEM_Energie_Klima_Vorgabe_HighR_XIX_Klima: required-interface=IF_HVEM_Energie_Klima_Vorgabe_HighR
      RP_IF_HVEM_Energie_Klima_Vorgabe_XIX_Klima: required-interface=IF_HVEM_Energie_Klima_Vorgabe
      RP_IF_HVEM_FreigabeBattHeizung_XIX_Klima: required-interface=IF_HVEM_FreigabeBattHeizung
      RP_IF_HVEM_FreigabeKlimatisierung_XIX_Klima: required-interface=IF_HVEM_FreigabeKlimatisierung
      RP_IF_HVEM_HV_Anf_XIX_Klima: required-interface=IF_HVEM_HV_Anf
      RP_IF_HVEM_Leistung_Bat_Kond_Vorgabe_XIX_Klima: required-interface=IF_HVEM_Leistung_Bat_Kond_Vorgabe
      RP_IF_HVEM_Leistung_Klima_Vorgabe_XIX_Klima: required-interface=IF_HVEM_Leistung_Klima_Vorgabe
      RP_IF_HVEM_Nutzbare_Energie_XIX_Klima: required-interface=IF_HVEM_Nutzbare_Energie
      RP_IF_HVH2_Err_Heizkreis_{1..3}_XIX_Klima: required-interface=IF_HVH2_Err_Heizkreis_{1..3}
      RP_IF_HVH2_Err_intern_XIX_Klima: required-interface=IF_HVH2_Err_intern
      RP_IF_HVH2_Err_Leckagestrom_XIX_Klima: required-interface=IF_HVH2_Err_Leckagestrom
      RP_IF_HVH2_Err_Temperaturschutz_XIX_Klima: required-interface=IF_HVH2_Err_Temperaturschutz
      RP_IF_HVH2_Err_Ueberstromabschaltung_XIX_Klima: required-interface=IF_HVH2_Err_Ueberstromabschaltung
      RP_IF_HVH2_Heizmedium_Sensor_1_XIX_Klima: required-interface=IF_HVH2_Heizmedium_Sensor_1
      RP_IF_HVH2_Heizmedium_Sensor_2_XIX_Klima: required-interface=IF_HVH2_Heizmedium_Sensor_2
      RP_IF_HVH2_High_Voltage_XIX_Klima: required-interface=IF_HVH2_High_Voltage
      RP_IF_HVH2_HV_ERR_XIX_Klima: required-interface=IF_HVH2_HV_ERR
      RP_IF_HVH2_I_ist_XIX_Klima: required-interface=IF_HVH2_I_ist
      RP_IF_HVH2_ResponseError_XIX_Klima: required-interface=IF_HVH2_ResponseError
      RP_IF_HVH2_Status_HVH_XIX_Klima: required-interface=IF_HVH2_Status_HVH
      RP_IF_HVH2_Status_UBatt_XIX_Klima: required-interface=IF_HVH2_Status_UBatt
      RP_IF_HVH2_Temp_PCB_XIX_Klima: required-interface=IF_HVH2_Temp_PCB
      RP_IF_HVH2_Timeout_Fehler_XIX_Klima: required-interface=IF_HVH2_Timeout_Fehler
      RP_IF_HVH2_UBatt_XIX_Klima: required-interface=IF_HVH2_UBatt
      RP_IF_HVH_ErrMem_State_XIX_Klima: required-interface=IF_HVH_ErrMem_State
      RP_IF_HVH_HV_Ilock_Status_XIX_Klima: required-interface=IF_HVH_HV_Ilock_Status
      RP_IF_HVH_HV_Voltage_Offset_XIX_Klima: required-interface=IF_HVH_HV_Voltage_Offset
      RP_IF_HVH_HV_Voltage_XIX_Klima: required-interface=IF_HVH_HV_Voltage
      RP_IF_HVH_HVb_Ilock_Status_XIX_Klima: required-interface=IF_HVH_HVb_Ilock_Status
      RP_IF_HVH_HVb_Voltage_Offset_XIX_Klima: required-interface=IF_HVH_HVb_Voltage_Offset
      RP_IF_HVH_HVb_Voltage_XIX_Klima: required-interface=IF_HVH_HVb_Voltage
      RP_IF_HVH_ParameterChange_XIX_Klima: required-interface=IF_HVH_ParameterChange
      RP_IF_HVHb_ErrMem_State_XIX_Klima: required-interface=IF_HVHb_ErrMem_State
      RP_IF_HVHb_ParameterChange_XIX_Klima: required-interface=IF_HVHb_ParameterChange
      RP_IF_HVK_AktiveEntladung_Anf_XIX_Klima: required-interface=IF_HVK_AktiveEntladung_Anf
      RP_IF_HVK_HV_Netz_Warnungen_XIX_Klima: required-interface=IF_HVK_HV_Netz_Warnungen
      RP_IF_HVK_Iso_Messung_Start_XIX_Klima: required-interface=IF_HVK_Iso_Messung_Start
      RP_IF_HVK_Notabschaltung_Anf_XIX_Klima: required-interface=IF_HVK_Notabschaltung_Anf
      RP_IF_HVK_Vorladung_aktiv_XIX_Klima: required-interface=IF_HVK_Vorladung_aktiv
      RP_IF_HVLM_DCBoostLaden_Anf_XIX_Klima: required-interface=IF_HVLM_DCBoostLaden_Anf
      RP_IF_IAA_Active_User_ID_XIX_Klima: required-interface=IF_IAA_Active_User_ID
      RP_IF_IAA_Identified_User_ID_XIX_Klima: required-interface=IF_IAA_Identified_User_ID
      RP_IF_IAA_PSO_wake_up_XIX_Klima: required-interface=IF_IAA_PSO_wake_up
      RP_IF_ICO2_Alarm_XIX_Klima: required-interface=IF_ICO2_Alarm
      RP_IF_ICO2_BZ_XIX_Klima: required-interface=IF_ICO2_BZ
      RP_IF_ICO2_CO2_Wert_XIX_Klima: required-interface=IF_ICO2_CO2_Wert
      RP_IF_ICO2_defekt_XIX_Klima: required-interface=IF_ICO2_defekt
      RP_IF_ICO2_Gradient_XIX_Klima: required-interface=IF_ICO2_Gradient
      RP_IF_ICO2_Laufzeit_XIX_Klima: required-interface=IF_ICO2_Laufzeit
      RP_IF_ICO2_Luftdruck_XIX_Klima: required-interface=IF_ICO2_Luftdruck
      RP_IF_ICO2_ResponseError_XIX_Klima: required-interface=IF_ICO2_ResponseError
      RP_IF_ICO2b_Alarm_XIX_Klima: required-interface=IF_ICO2b_Alarm
      RP_IF_ICO2b_BZ_XIX_Klima: required-interface=IF_ICO2b_BZ
      RP_IF_ICO2b_CO2_Wert_XIX_Klima: required-interface=IF_ICO2b_CO2_Wert
      RP_IF_ICO2b_defekt_XIX_Klima: required-interface=IF_ICO2b_defekt
      RP_IF_ICO2b_Gradient_XIX_Klima: required-interface=IF_ICO2b_Gradient
      RP_IF_ICO2b_Laufzeit_XIX_Klima: required-interface=IF_ICO2b_Laufzeit
      RP_IF_ICO2b_Luftdruck_XIX_Klima: required-interface=IF_ICO2b_Luftdruck
      RP_IF_ICO2b_ResponseError_XIX_Klima: required-interface=IF_ICO2b_ResponseError
      RP_IF_ION_0s_Dummy_XIX_Klima: required-interface=IF_ION_0s_Dummy
      RP_IF_ION_Adressegment_XIX_Klima: required-interface=IF_ION_Adressegment
      RP_IF_ION_Adressinhalt_XIX_Klima: required-interface=IF_ION_Adressinhalt
      RP_IF_ION_BZ_XIX_Klima: required-interface=IF_ION_BZ
      RP_IF_ION_Fehler_Emitter_2_XIX_Klima: required-interface=IF_ION_Fehler_Emitter_2
      RP_IF_ION_Fehler_Emitter_XIX_Klima: required-interface=IF_ION_Fehler_Emitter
      RP_IF_ION_Fehler_Intern_XIX_Klima: required-interface=IF_ION_Fehler_Intern
      RP_IF_ION_Fehler_LED_XIX_Klima: required-interface=IF_ION_Fehler_LED
      RP_IF_ION_Fehler_Taster_XIX_Klima: required-interface=IF_ION_Fehler_Taster
      RP_IF_ION_FehlerGueltigkeit_XIX_Klima: required-interface=IF_ION_FehlerGueltigkeit
      RP_IF_ION_HW_XIX_Klima: required-interface=IF_ION_HW
      RP_IF_ION_ResponseError_XIX_Klima: required-interface=IF_ION_ResponseError
      RP_IF_ION_Status_LED_XIX_Klima: required-interface=IF_ION_Status_LED
      RP_IF_ION_Status_Taster_XIX_Klima: required-interface=IF_ION_Status_Taster
      RP_IF_ION_Status_XIX_Klima: required-interface=IF_ION_Status
      RP_IF_ION_SW_XIX_Klima: required-interface=IF_ION_SW
      RP_IF_KBF_defekt_XIX_Klima: required-interface=IF_KBF_defekt
      RP_IF_KBF_Einheiten_XIX_Klima: required-interface=IF_KBF_Einheiten
      RP_IF_KBF_ResponseError_XIX_Klima: required-interface=IF_KBF_ResponseError
      RP_IF_KBF_SIH_Diag_XIX_Klima: required-interface=IF_KBF_SIH_Diag
      RP_IF_KBF_SIH_hl_Status_XIX_Klima: required-interface=IF_KBF_SIH_hl_Status
      RP_IF_KBF_SIH_hr_Status_XIX_Klima: required-interface=IF_KBF_SIH_hr_Status
      RP_IF_KBF_Strom_SIH_hl_XIX_Klima: required-interface=IF_KBF_Strom_SIH_hl
      RP_IF_KBF_Strom_SIH_hr_XIX_Klima: required-interface=IF_KBF_Strom_SIH_hr
      RP_IF_KBF_Tasten_Fehler_XIX_Klima: required-interface=IF_KBF_Tasten_Fehler
      RP_IF_KBF_Temp_Fuss_Fond_XIX_Klima: required-interface=IF_KBF_Temp_Fuss_Fond
      RP_IF_KBF_Temp_MA_Fond_XIX_Klima: required-interface=IF_KBF_Temp_MA_Fond
      RP_IF_KBF_Temp_SIH_hl_XIX_Klima: required-interface=IF_KBF_Temp_SIH_hl
      RP_IF_KBF_Temp_SIH_hr_XIX_Klima: required-interface=IF_KBF_Temp_SIH_hr
      RP_IF_KBI_Aussen_Temp_gef_XIX_Klima: required-interface=IF_KBI_Aussen_Temp_gef
      RP_IF_KBI_Einheit_Temp_XIX_Klima: required-interface=IF_KBI_Einheit_Temp
      RP_IF_KBI_Kilometerstand_XIX_Klima: required-interface=IF_KBI_Kilometerstand
      RP_IF_KBI_QBit_Aussen_Temp_gef_XIX_Klima: required-interface=IF_KBI_QBit_Aussen_Temp_gef
      RP_IF_KL_Fond_Status_XIX_Klima: required-interface=IF_KL_Fond_Status
      RP_IF_KL_SL_Soll_hl_XIX_Klima: required-interface=IF_KL_SL_Soll_hl
      RP_IF_KL_SL_Soll_hr_XIX_Klima: required-interface=IF_KL_SL_Soll_hr
      RP_IF_KL_Temp_hl_XIX_Klima: required-interface=IF_KL_Temp_hl
      RP_IF_KL_Temp_Status_hl_XIX_Klima: required-interface=IF_KL_Temp_Status_hl
      RP_IF_KLh_aus_XIX_Klima: required-interface=IF_KLh_aus
      RP_IF_KLh_Ausstattung_KlimaHeck_XIX_Klima: required-interface=IF_KLh_Ausstattung_KlimaHeck
      RP_IF_KLh_Fehler{1..8}_XIX_Klima: required-interface=IF_KLh_Fehler{1..8}
      RP_IF_KLh_Seite_defog_hl_XIX_Klima: required-interface=IF_KLh_Seite_defog_hl
      RP_IF_KLh_SIH_Last_defekt_hl_XIX_Klima: required-interface=IF_KLh_SIH_Last_defekt_hl
      RP_IF_KLh_SIH_Last_defekt_hr_XIX_Klima: required-interface=IF_KLh_SIH_Last_defekt_hr
      RP_IF_KLh_SIH_NTC_defekt_hl_XIX_Klima: required-interface=IF_KLh_SIH_NTC_defekt_hl
      RP_IF_KLh_SIH_NTC_defekt_hr_XIX_Klima: required-interface=IF_KLh_SIH_NTC_defekt_hr
      RP_IF_KLh_SIH_Stufe_hl_XIX_Klima: required-interface=IF_KLh_SIH_Stufe_hl
      RP_IF_KLh_SIH_Stufe_hr_XIX_Klima: required-interface=IF_KLh_SIH_Stufe_hr
      RP_IF_KLh_toggle_LVT_XIX_Klima: required-interface=IF_KLh_toggle_LVT
      RP_IF_KLhl_GeblaeseSoll_XIX_Klima: required-interface=IF_KLhl_GeblaeseSoll
      RP_IF_KLhl_Luft_auto_XIX_Klima: required-interface=IF_KLhl_Luft_auto
      RP_IF_KLhl_Luft_mitte_XIX_Klima: required-interface=IF_KLhl_Luft_mitte
      RP_IF_KLhl_Luft_oben_XIX_Klima: required-interface=IF_KLhl_Luft_oben
      RP_IF_KLhl_Luft_seite_XIX_Klima: required-interface=IF_KLhl_Luft_seite
      RP_IF_KLhl_Luft_unten_XIX_Klima: required-interface=IF_KLhl_Luft_unten
      RP_IF_KLhl_ResponseError_XIX_Klima: required-interface=IF_KLhl_ResponseError
      RP_IF_KLhl_TempSoll_XIX_Klima: required-interface=IF_KLhl_TempSoll
      RP_IF_KLhr_TempSoll_XIX_Klima: required-interface=IF_KLhr_TempSoll
      RP_IF_KPV_AC_max_XIX_Klima: required-interface=IF_KPV_AC_max
      RP_IF_KPV_AC_Taste_XIX_Klima: required-interface=IF_KPV_AC_Taste
      RP_IF_KPV_AC_XIX_Klima: required-interface=IF_KPV_AC
      RP_IF_KPV_Auto_li_XIX_Klima: required-interface=IF_KPV_Auto_li
      RP_IF_KPV_Auto_Taste_XIX_Klima: required-interface=IF_KPV_Auto_Taste
      RP_IF_KPV_AutoSiKli_li_XIX_Klima: required-interface=IF_KPV_AutoSiKli_li
      RP_IF_KPV_AutoSiKli_re_XIX_Klima: required-interface=IF_KPV_AutoSiKli_re
      RP_IF_KPV_AutoUmluft_XIX_Klima: required-interface=IF_KPV_AutoUmluft
      RP_IF_KPV_Beduftung_XIX_Klima: required-interface=IF_KPV_Beduftung
      RP_IF_KPV_Defrost_XIX_Klima: required-interface=IF_KPV_Defrost
      RP_IF_KPV_DefrostMAX_Taste_XIX_Klima: required-interface=IF_KPV_DefrostMAX_Taste
      RP_IF_KPV_ECO_XIX_Klima: required-interface=IF_KPV_ECO
      RP_IF_KPV_FSH_XIX_Klima: required-interface=IF_KPV_FSH
      RP_IF_KPV_Geblaese_Auto_li_XIX_Klima: required-interface=IF_KPV_Geblaese_Auto_li
      RP_IF_KPV_Geblaese_Stufe_li_XIX_Klima: required-interface=IF_KPV_Geblaese_Stufe_li
      RP_IF_KPV_HSH_Taste_XIX_Klima: required-interface=IF_KPV_HSH_Taste
      RP_IF_KPV_HSH_XIX_Klima: required-interface=IF_KPV_HSH
      RP_IF_KPV_Init_2_XIX_Klima: required-interface=IF_KPV_Init_2
      RP_IF_KPV_Init_XIX_Klima: required-interface=IF_KPV_Init
      RP_IF_KPV_Ionisator_XIX_Klima: required-interface=IF_KPV_Ionisator
      RP_IF_KPV_Joker_Taste_XIX_Klima: required-interface=IF_KPV_Joker_Taste
      RP_IF_KPV_Klima_Menue_MMI_XIX_Klima: required-interface=IF_KPV_Klima_Menue_MMI
      RP_IF_KPV_Konditionierung_Taste_XIX_Klima: required-interface=IF_KPV_Konditionierung_Taste
      RP_IF_KPV_Kopfraumheizung_li_XIX_Klima: required-interface=IF_KPV_Kopfraumheizung_li
      RP_IF_KPV_Kopfraumheizung_re_XIX_Klima: required-interface=IF_KPV_Kopfraumheizung_re
      RP_IF_KPV_Lokalaktiv_XIX_Klima: required-interface=IF_KPV_Lokalaktiv
      RP_IF_KPV_Luftverteilung_Auto_li_XIX_Klima: required-interface=IF_KPV_Luftverteilung_Auto_li
      RP_IF_KPV_Luftverteilung_Mitte_li_XIX_Klima: required-interface=IF_KPV_Luftverteilung_Mitte_li
      RP_IF_KPV_Luftverteilung_Oben_li_XIX_Klima: required-interface=IF_KPV_Luftverteilung_Oben_li
      RP_IF_KPV_Luftverteilung_Unten_li_XIX_Klima: required-interface=IF_KPV_Luftverteilung_Unten_li
      RP_IF_KPV_OBD_Gruppe_XIX_Klima: required-interface=IF_KPV_OBD_Gruppe
      RP_IF_KPV_OBD_XIX_Klima: required-interface=IF_KPV_OBD
      RP_IF_KPV_Off_XIX_Klima: required-interface=IF_KPV_Off
      RP_IF_KPV_Panel_Error_XIX_Klima: required-interface=IF_KPV_Panel_Error
      RP_IF_KPV_Popup_Content_ZL1R_XIX_Klima: required-interface=IF_KPV_Popup_Content_ZL1R
      RP_IF_KPV_Popup_Content_ZR1R_XIX_Klima: required-interface=IF_KPV_Popup_Content_ZR1R
      RP_IF_KPV_PureAir_XIX_Klima: required-interface=IF_KPV_PureAir
      RP_IF_KPV_Rear_XIX_Klima: required-interface=IF_KPV_Rear
      RP_IF_KPV_ResponseError_XIX_Klima: required-interface=IF_KPV_ResponseError
      RP_IF_KPV_Restwaerme_XIX_Klima: required-interface=IF_KPV_Restwaerme
      RP_IF_KPV_Sitzheizung_li_XIX_Klima: required-interface=IF_KPV_Sitzheizung_li
      RP_IF_KPV_Sitzheizung_re_XIX_Klima: required-interface=IF_KPV_Sitzheizung_re
      RP_IF_KPV_Sitzlueftung_li_XIX_Klima: required-interface=IF_KPV_Sitzlueftung_li
      RP_IF_KPV_Sitzlueftung_re_XIX_Klima: required-interface=IF_KPV_Sitzlueftung_re
      RP_IF_KPV_Status_Spannung_XIX_Klima: required-interface=IF_KPV_Status_Spannung
      RP_IF_KPV_Sync_XIX_Klima: required-interface=IF_KPV_Sync
      RP_IF_KPV_Tasten_Fehler_XIX_Klima: required-interface=IF_KPV_Tasten_Fehler
      RP_IF_KPV_Temp_li_XIX_Klima: required-interface=IF_KPV_Temp_li
      RP_IF_KPV_Temp_Platine_XIX_Klima: required-interface=IF_KPV_Temp_Platine
      RP_IF_KPV_Temp_re_XIX_Klima: required-interface=IF_KPV_Temp_re
      RP_IF_KPV_Umluft_XIX_Klima: required-interface=IF_KPV_Umluft
      RP_IF_KPV_Zustand_Off_XIX_Klima: required-interface=IF_KPV_Zustand_Off
      RP_IF_KST_Sonderzustand_Status_XIX_Klima: required-interface=IF_KST_Sonderzustand_Status
      RP_IF_KVA_Ist_Pos_XIX_Klima: required-interface=IF_KVA_Ist_Pos
      RP_IF_Ladezustand_02_XIX_Klima: required-interface=IF_Ladezustand_02
      RP_IF_LHR_01_FnAbbruch_Heizkreis_A_XIX_Klima: required-interface=IF_LHR_01_FnAbbruch_Heizkreis_A
      RP_IF_LHR_01_FnAbbruch_Heizkreis_B_XIX_Klima: required-interface=IF_LHR_01_FnAbbruch_Heizkreis_B
      RP_IF_LHR_01_NTC_Temperatur_A_XIX_Klima: required-interface=IF_LHR_01_NTC_Temperatur_A
      RP_IF_LHR_01_NTC_Temperatur_B_XIX_Klima: required-interface=IF_LHR_01_NTC_Temperatur_B
      RP_IF_LHR_01_ResponseError_XIX_Klima: required-interface=IF_LHR_01_ResponseError
      RP_IF_LHR_01_SG_defekt_XIX_Klima: required-interface=IF_LHR_01_SG_defekt
      RP_IF_LHR_01_Status_Ausgang_A_02_XIX_Klima: required-interface=IF_LHR_01_Status_Ausgang_A_02
      RP_IF_LHR_01_Status_Ausgang_B_02_XIX_Klima: required-interface=IF_LHR_01_Status_Ausgang_B_02
      RP_IF_LHR_01_Status_CodierPins_XIX_Klima: required-interface=IF_LHR_01_Status_CodierPins
      RP_IF_LHR_01_Status_PCB_Uebertemp_XIX_Klima: required-interface=IF_LHR_01_Status_PCB_Uebertemp
      RP_IF_LHR_01_Status_Taster_A_XIX_Klima: required-interface=IF_LHR_01_Status_Taster_A
      RP_IF_LHR_01_Status_Taster_B_XIX_Klima: required-interface=IF_LHR_01_Status_Taster_B
      RP_IF_LiSi_Defrost_Taste_XIX_Klima: required-interface=IF_LiSi_Defrost_Taste
      RP_IF_LiSi_FSH_Taste_XIX_Klima: required-interface=IF_LiSi_FSH_Taste
      RP_IF_LiSi_HSH_Taste_XIX_Klima: required-interface=IF_LiSi_HSH_Taste
      RP_IF_LLR_LL1_Blockierung_XIX_Klima: required-interface=IF_LLR_LL1_Blockierung
      RP_IF_LLR_LL1_CodierPinError_XIX_Klima: required-interface=IF_LLR_LL1_CodierPinError
      RP_IF_LLR_LL1_Feuchte01_XIX_Klima: required-interface=IF_LLR_LL1_Feuchte01
      RP_IF_LLR_LL1_Feuchte02_XIX_Klima: required-interface=IF_LLR_LL1_Feuchte02
      RP_IF_LLR_LL1_Feuchtesensor_01_defekt_XIX_Klima: required-interface=IF_LLR_LL1_Feuchtesensor_01_defekt
      RP_IF_LLR_LL1_Feuchtesensor_02_defekt_XIX_Klima: required-interface=IF_LLR_LL1_Feuchtesensor_02_defekt
      RP_IF_LLR_LL1_Ist_Drehzahl_XIX_Klima: required-interface=IF_LLR_LL1_Ist_Drehzahl
      RP_IF_LLR_LL1_Lokalaktiv_XIX_Klima: required-interface=IF_LLR_LL1_Lokalaktiv
      RP_IF_LLR_LL1_Luefter_defekt_XIX_Klima: required-interface=IF_LLR_LL1_Luefter_defekt
      RP_IF_LLR_LL1_ResponseError_XIX_Klima: required-interface=IF_LLR_LL1_ResponseError
      RP_IF_LLR_LL1_Temperatur_01_XIX_Klima: required-interface=IF_LLR_LL1_Temperatur_01
      RP_IF_LLR_LL1_Temperatur_02_XIX_Klima: required-interface=IF_LLR_LL1_Temperatur_02
      RP_IF_LLR_LL1_Ueberspannung_XIX_Klima: required-interface=IF_LLR_LL1_Ueberspannung
      RP_IF_LLR_LL1_Uebertemperatur_XIX_Klima: required-interface=IF_LLR_LL1_Uebertemperatur
      RP_IF_LLR_LL1_Unterspannung_XIX_Klima: required-interface=IF_LLR_LL1_Unterspannung
      RP_IF_LLR_LS1_Blockierung_XIX_Klima: required-interface=IF_LLR_LS1_Blockierung
      RP_IF_LLR_LS1_CodierPinError_XIX_Klima: required-interface=IF_LLR_LS1_CodierPinError
      RP_IF_LLR_LS1_Feuchte01_XIX_Klima: required-interface=IF_LLR_LS1_Feuchte01
      RP_IF_LLR_LS1_Feuchte02_XIX_Klima: required-interface=IF_LLR_LS1_Feuchte02
      RP_IF_LLR_LS1_Feuchtesensor_01_defekt_XIX_Klima: required-interface=IF_LLR_LS1_Feuchtesensor_01_defekt
      RP_IF_LLR_LS1_Feuchtesensor_02_defekt_XIX_Klima: required-interface=IF_LLR_LS1_Feuchtesensor_02_defekt
      RP_IF_LLR_LS1_Ist_Drehzahl_XIX_Klima: required-interface=IF_LLR_LS1_Ist_Drehzahl
      RP_IF_LLR_LS1_Lokalaktiv_XIX_Klima: required-interface=IF_LLR_LS1_Lokalaktiv
      RP_IF_LLR_LS1_Luefter_defekt_XIX_Klima: required-interface=IF_LLR_LS1_Luefter_defekt
      RP_IF_LLR_LS1_ResponseError_XIX_Klima: required-interface=IF_LLR_LS1_ResponseError
      RP_IF_LLR_LS1_Temperatur_01_XIX_Klima: required-interface=IF_LLR_LS1_Temperatur_01
      RP_IF_LLR_LS1_Temperatur_02_XIX_Klima: required-interface=IF_LLR_LS1_Temperatur_02
      RP_IF_LLR_LS1_Ueberspannung_XIX_Klima: required-interface=IF_LLR_LS1_Ueberspannung
      RP_IF_LLR_LS1_Uebertemperatur_XIX_Klima: required-interface=IF_LLR_LS1_Uebertemperatur
      RP_IF_LLR_LS1_Unterspannung_XIX_Klima: required-interface=IF_LLR_LS1_Unterspannung
      RP_IF_LLR_LS2_Blockierung_XIX_Klima: required-interface=IF_LLR_LS2_Blockierung
      RP_IF_LLR_LS2_CodierPinError_XIX_Klima: required-interface=IF_LLR_LS2_CodierPinError
      RP_IF_LLR_LS2_Ist_Drehzahl_XIX_Klima: required-interface=IF_LLR_LS2_Ist_Drehzahl
      RP_IF_LLR_LS2_Lokalaktiv_XIX_Klima: required-interface=IF_LLR_LS2_Lokalaktiv
      RP_IF_LLR_LS2_Luefter_defekt_XIX_Klima: required-interface=IF_LLR_LS2_Luefter_defekt
      RP_IF_LLR_LS2_ResponseError_XIX_Klima: required-interface=IF_LLR_LS2_ResponseError
      RP_IF_LLR_LS2_Ueberspannung_XIX_Klima: required-interface=IF_LLR_LS2_Ueberspannung
      RP_IF_LLR_LS2_Uebertemperatur_XIX_Klima: required-interface=IF_LLR_LS2_Uebertemperatur
      RP_IF_LLR_LS2_Unterspannung_XIX_Klima: required-interface=IF_LLR_LS2_Unterspannung
      RP_IF_LLR_RL1_Blockierung_XIX_Klima: required-interface=IF_LLR_RL1_Blockierung
      RP_IF_LLR_RL1_CodierPinError_XIX_Klima: required-interface=IF_LLR_RL1_CodierPinError
      RP_IF_LLR_RL1_Feuchte01_XIX_Klima: required-interface=IF_LLR_RL1_Feuchte01
      RP_IF_LLR_RL1_Feuchte02_XIX_Klima: required-interface=IF_LLR_RL1_Feuchte02
      RP_IF_LLR_RL1_Feuchtesensor_01_defekt_XIX_Klima: required-interface=IF_LLR_RL1_Feuchtesensor_01_defekt
      RP_IF_LLR_RL1_Feuchtesensor_02_defekt_XIX_Klima: required-interface=IF_LLR_RL1_Feuchtesensor_02_defekt
      RP_IF_LLR_RL1_Ist_Drehzahl_XIX_Klima: required-interface=IF_LLR_RL1_Ist_Drehzahl
      RP_IF_LLR_RL1_Lokalaktiv_XIX_Klima: required-interface=IF_LLR_RL1_Lokalaktiv
      RP_IF_LLR_RL1_Luefter_defekt_XIX_Klima: required-interface=IF_LLR_RL1_Luefter_defekt
      RP_IF_LLR_RL1_ResponseError_XIX_Klima: required-interface=IF_LLR_RL1_ResponseError
      RP_IF_LLR_RL1_Temperatur_01_XIX_Klima: required-interface=IF_LLR_RL1_Temperatur_01
      RP_IF_LLR_RL1_Temperatur_02_XIX_Klima: required-interface=IF_LLR_RL1_Temperatur_02
      RP_IF_LLR_RL1_Ueberspannung_XIX_Klima: required-interface=IF_LLR_RL1_Ueberspannung
      RP_IF_LLR_RL1_Uebertemperatur_XIX_Klima: required-interface=IF_LLR_RL1_Uebertemperatur
      RP_IF_LLR_RL1_Unterspannung_XIX_Klima: required-interface=IF_LLR_RL1_Unterspannung
      RP_IF_LLR_RS1_Blockierung_XIX_Klima: required-interface=IF_LLR_RS1_Blockierung
      RP_IF_LLR_RS1_CodierPinError_XIX_Klima: required-interface=IF_LLR_RS1_CodierPinError
      RP_IF_LLR_RS1_Feuchte01_XIX_Klima: required-interface=IF_LLR_RS1_Feuchte01
      RP_IF_LLR_RS1_Feuchte02_XIX_Klima: required-interface=IF_LLR_RS1_Feuchte02
      RP_IF_LLR_RS1_Feuchtesensor_01_defekt_XIX_Klima: required-interface=IF_LLR_RS1_Feuchtesensor_01_defekt
      RP_IF_LLR_RS1_Feuchtesensor_02_defekt_XIX_Klima: required-interface=IF_LLR_RS1_Feuchtesensor_02_defekt
      RP_IF_LLR_RS1_Ist_Drehzahl_XIX_Klima: required-interface=IF_LLR_RS1_Ist_Drehzahl
      RP_IF_LLR_RS1_Lokalaktiv_XIX_Klima: required-interface=IF_LLR_RS1_Lokalaktiv
      RP_IF_LLR_RS1_Luefter_defekt_XIX_Klima: required-interface=IF_LLR_RS1_Luefter_defekt
      RP_IF_LLR_RS1_ResponseError_XIX_Klima: required-interface=IF_LLR_RS1_ResponseError
      RP_IF_LLR_RS1_Temperatur_01_XIX_Klima: required-interface=IF_LLR_RS1_Temperatur_01
      RP_IF_LLR_RS1_Temperatur_02_XIX_Klima: required-interface=IF_LLR_RS1_Temperatur_02
      RP_IF_LLR_RS1_Ueberspannung_XIX_Klima: required-interface=IF_LLR_RS1_Ueberspannung
      RP_IF_LLR_RS1_Uebertemperatur_XIX_Klima: required-interface=IF_LLR_RS1_Uebertemperatur
      RP_IF_LLR_RS1_Unterspannung_XIX_Klima: required-interface=IF_LLR_RS1_Unterspannung
      RP_IF_LLR_RS2_Blockierung_XIX_Klima: required-interface=IF_LLR_RS2_Blockierung
      RP_IF_LLR_RS2_CodierPinError_XIX_Klima: required-interface=IF_LLR_RS2_CodierPinError
      RP_IF_LLR_RS2_Ist_Drehzahl_XIX_Klima: required-interface=IF_LLR_RS2_Ist_Drehzahl
      RP_IF_LLR_RS2_Lokalaktiv_XIX_Klima: required-interface=IF_LLR_RS2_Lokalaktiv
      RP_IF_LLR_RS2_Luefter_defekt_XIX_Klima: required-interface=IF_LLR_RS2_Luefter_defekt
      RP_IF_LLR_RS2_ResponseError_XIX_Klima: required-interface=IF_LLR_RS2_ResponseError
      RP_IF_LLR_RS2_Ueberspannung_XIX_Klima: required-interface=IF_LLR_RS2_Ueberspannung
      RP_IF_LLR_RS2_Uebertemperatur_XIX_Klima: required-interface=IF_LLR_RS2_Uebertemperatur
      RP_IF_LLR_RS2_Unterspannung_XIX_Klima: required-interface=IF_LLR_RS2_Unterspannung
      RP_IF_LR_HZG_Konfiguration_XIX_Klima: required-interface=IF_LR_HZG_Konfiguration
      RP_IF_LR_HZG_Temp_Sensor_XIX_Klima: required-interface=IF_LR_HZG_Temp_Sensor
      RP_IF_LRH_On_Off_XIX_Klima: required-interface=IF_LRH_On_Off
      RP_IF_LS_Helligkeit_IR_XIX_Klima: required-interface=IF_LS_Helligkeit_IR
      RP_IF_MD1_Lage_XIX_Klima: required-interface=IF_MD1_Lage
      RP_IF_MD1_Position_XIX_Klima: required-interface=IF_MD1_Position
      RP_IF_MD3_Lage_XIX_Klima: required-interface=IF_MD3_Lage
      RP_IF_MFL_Eventcode_1_XIX_Klima: required-interface=IF_MFL_Eventcode_1
      RP_IF_MFL_Eventcode_2_XIX_Klima: required-interface=IF_MFL_Eventcode_2
      RP_IF_MFL_Tastencode_1_XIX_Klima: required-interface=IF_MFL_Tastencode_1
      RP_IF_MFL_Tastencode_2_XIX_Klima: required-interface=IF_MFL_Tastencode_2
      RP_IF_MFL_Variante_XIX_Klima: required-interface=IF_MFL_Variante
      RP_IF_MIK_PetsMode_state_XIX_Klima: required-interface=IF_MIK_PetsMode_state
      RP_IF_MO_HVEM_MaxLeistung_XIX_Klima: required-interface=IF_MO_HVEM_MaxLeistung
      RP_IF_MO_HYB_Fahrbereitschaft_XIX_Klima: required-interface=IF_MO_HYB_Fahrbereitschaft
      RP_IF_MO_Hybridfahrzeug_XIX_Klima: required-interface=IF_MO_Hybridfahrzeug
      RP_IF_MO_Klima_Regelmodus_XIX_Klima: required-interface=IF_MO_Klima_Regelmodus
      RP_IF_MO_Kuehlerluefter_1_XIX_Klima: required-interface=IF_MO_Kuehlerluefter_1
      RP_IF_MO_Kuehlerluefter_2_XIX_Klima: required-interface=IF_MO_Kuehlerluefter_2
      RP_IF_MO_Kuehlerluefter_MUX_XIX_Klima: required-interface=IF_MO_Kuehlerluefter_MUX
      RP_IF_MO_OBD_Typ_XIX_Klima: required-interface=IF_MO_OBD_Typ
      RP_IF_MO_QBit_Aussen_Temp_XIX_Klima: required-interface=IF_MO_QBit_Aussen_Temp
      RP_IF_MO_RedFahrleistung_Lampe_XIX_Klima: required-interface=IF_MO_RedFahrleistung_Lampe
      RP_IF_MRollo_Lage_XIX_Klima: required-interface=IF_MRollo_Lage
      RP_IF_MRollo_Position_XIX_Klima: required-interface=IF_MRollo_Position
      RP_IF_ND_PSD_Tunnel_Status_XIX_Klima: required-interface=IF_ND_PSD_Tunnel_Status
      RP_IF_NM_DCDC_NV_NM_State_XIX_Klima: required-interface=IF_NM_DCDC_NV_NM_State
      RP_IF_NM_Gateway_NM_State_XIX_Klima: required-interface=IF_NM_Gateway_NM_State
      RP_IF_NM_Hybrid_01_NM_State_XIX_Klima: required-interface=IF_NM_Hybrid_01_NM_State
      RP_IF_NM_Ladegeraet_NM_State_XIX_Klima: required-interface=IF_NM_Ladegeraet_NM_State
      RP_IF_NVEM_Abschaltstufe_XIX_Klima: required-interface=IF_NVEM_Abschaltstufe
      RP_IF_NVEM_Last_Anf_XIX_Klima: required-interface=IF_NVEM_Last_Anf
      RP_IF_OBD_Abs_Load_Val_XIX_Klima: required-interface=IF_OBD_Abs_Load_Val
      RP_IF_OBD_Abs_Pedal_Pos_XIX_Klima: required-interface=IF_OBD_Abs_Pedal_Pos
      RP_IF_OBD_Abs_Throttle_Pos_XIX_Klima: required-interface=IF_OBD_Abs_Throttle_Pos
      RP_IF_OBD_Calc_Load_Val_XIX_Klima: required-interface=IF_OBD_Calc_Load_Val
      RP_IF_OBD_Driving_Cycle_XIX_Klima: required-interface=IF_OBD_Driving_Cycle
      RP_IF_OBD_Eng_Cool_Temp_XIX_Klima: required-interface=IF_OBD_Eng_Cool_Temp
      RP_IF_OBD_Kaltstart_Denominator_XIX_Klima: required-interface=IF_OBD_Kaltstart_Denominator
      RP_IF_OBD_Minimum_Trip_XIX_Klima: required-interface=IF_OBD_Minimum_Trip
      RP_IF_OBD_Normed_Trip_XIX_Klima: required-interface=IF_OBD_Normed_Trip
      RP_IF_OBD_Sperrung_IUMPR_XIX_Klima: required-interface=IF_OBD_Sperrung_IUMPR
      RP_IF_OBD_Warm_Up_Cycle_XIX_Klima: required-interface=IF_OBD_Warm_Up_Cycle
      RP_IF_OBDProtocol_req_XIX_Klima: required-interface=IF_OBDProtocol_req
      RP_IF_OPS_ComfortReadyStatus_XIX_Klima: required-interface=IF_OPS_ComfortReadyStatus
      RP_IF_OPS_DriverPresenceStatus_XIX_Klima: required-interface=IF_OPS_DriverPresenceStatus
      RP_IF_OPS_OccupantPresenceStatus_XIX_Klima: required-interface=IF_OPS_OccupantPresenceStatus
      RP_IF_OPS_QBit_DriverPresence_XIX_Klima: required-interface=IF_OPS_QBit_DriverPresence
      RP_IF_ORU_AP_Mode_XIX_Klima: required-interface=IF_ORU_AP_Mode
      RP_IF_ORU_EM_Anfrage_Flashdauer_XIX_Klima: required-interface=IF_ORU_EM_Anfrage_Flashdauer
      RP_IF_ORU_EM_Anfrage_freigegebeneNetze_XIX_Klima: required-interface=IF_ORU_EM_Anfrage_freigegebeneNetze
      RP_IF_ORU_EM_Anfrage_Stromaufnahme_XIX_Klima: required-interface=IF_ORU_EM_Anfrage_Stromaufnahme
      RP_IF_ORU_Status_XIX_Klima: required-interface=IF_ORU_Status
      RP_IF_PCU_Adressinhalt_XIX_Klima: required-interface=IF_PCU_Adressinhalt
      RP_IF_PCU_Betriebsstunden_XIX_Klima: required-interface=IF_PCU_Betriebsstunden
      RP_IF_PCU_Defekt_XIX_Klima: required-interface=IF_PCU_Defekt
      RP_IF_PCU_Fehler_Emitter_XIX_Klima: required-interface=IF_PCU_Fehler_Emitter
      RP_IF_PCU_Fehler_Intern_XIX_Klima: required-interface=IF_PCU_Fehler_Intern
      RP_IF_PCU_I_Sec_XIX_Klima: required-interface=IF_PCU_I_Sec
      RP_IF_PCU_Polarisation_XIX_Klima: required-interface=IF_PCU_Polarisation
      RP_IF_PCU_ResponseError_XIX_Klima: required-interface=IF_PCU_ResponseError
      RP_IF_PCU_State_Polarisation_XIX_Klima: required-interface=IF_PCU_State_Polarisation
      RP_IF_PCU_Status_LED_XIX_Klima: required-interface=IF_PCU_Status_LED
      RP_IF_PCU_Status_XIX_Klima: required-interface=IF_PCU_Status
      RP_IF_PCU_Temp_PCB_XIX_Klima: required-interface=IF_PCU_Temp_PCB
      RP_IF_PCU_U_Sec_XIX_Klima: required-interface=IF_PCU_U_Sec
      RP_IF_Perso_Aktiv_XIX_Klima: required-interface=IF_Perso_Aktiv
      RP_IF_Perso_Bedienstelle_XIX_Klima: required-interface=IF_Perso_Bedienstelle
      RP_IF_Perso_Fahrernummer_XIX_Klima: required-interface=IF_Perso_Fahrernummer
      RP_IF_Perso_Freigabe_Verstellung_XIX_Klima: required-interface=IF_Perso_Freigabe_Verstellung
      RP_IF_Perso_Kontonummer_XIX_Klima: required-interface=IF_Perso_Kontonummer
      RP_IF_Perso_Schreibschutz_XIX_Klima: required-interface=IF_Perso_Schreibschutz
      RP_IF_Perso_Status_XIX_Klima: required-interface=IF_Perso_Status
      RP_IF_Perso_Steuerung_XIX_Klima: required-interface=IF_Perso_Steuerung
      RP_IF_Perso_Steuerungsparameter_XIX_Klima: required-interface=IF_Perso_Steuerungsparameter
      RP_IF_PMS1_Partikel_XIX_Klima: required-interface=IF_PMS1_Partikel
      RP_IF_PMS1_ResponseError_XIX_Klima: required-interface=IF_PMS1_ResponseError
      RP_IF_PMS1_Status_XIX_Klima: required-interface=IF_PMS1_Status
      RP_IF_PSD_06_Mux_XIX_Klima: required-interface=IF_PSD_06_Mux
      RP_IF_PSD_Abzweigerichtung_XIX_Klima: required-interface=IF_PSD_Abzweigerichtung
      RP_IF_PSD_Abzweigewinkel_XIX_Klima: required-interface=IF_PSD_Abzweigewinkel
      RP_IF_PSD_ADAS_Qualitaet_XIX_Klima: required-interface=IF_PSD_ADAS_Qualitaet
      RP_IF_PSD_Anfangskruemmung_Vorz_XIX_Klima: required-interface=IF_PSD_Anfangskruemmung_Vorz
      RP_IF_PSD_Anfangskruemmung_XIX_Klima: required-interface=IF_PSD_Anfangskruemmung
      RP_IF_PSD_Attribut_1_ID_XIX_Klima: required-interface=IF_PSD_Attribut_1_ID
      RP_IF_PSD_Attribut_1_Offset_XIX_Klima: required-interface=IF_PSD_Attribut_1_Offset
      RP_IF_PSD_Attribut_1_Wert_XIX_Klima: required-interface=IF_PSD_Attribut_1_Wert
      RP_IF_PSD_Attribut_2_ID_XIX_Klima: required-interface=IF_PSD_Attribut_2_ID
      RP_IF_PSD_Attribut_2_Offset_XIX_Klima: required-interface=IF_PSD_Attribut_2_Offset
      RP_IF_PSD_Attribut_2_Wert_XIX_Klima: required-interface=IF_PSD_Attribut_2_Wert
      RP_IF_PSD_Attribut_3_ID_XIX_Klima: required-interface=IF_PSD_Attribut_3_ID
      RP_IF_PSD_Attribut_3_Offset_XIX_Klima: required-interface=IF_PSD_Attribut_3_Offset
      RP_IF_PSD_Attribut_3_Wert_XIX_Klima: required-interface=IF_PSD_Attribut_3_Wert
      RP_IF_PSD_Attribut_4_ID_XIX_Klima: required-interface=IF_PSD_Attribut_4_ID
      RP_IF_PSD_Attribut_4_Offset_XIX_Klima: required-interface=IF_PSD_Attribut_4_Offset
      RP_IF_PSD_Attribut_4_Wert_XIX_Klima: required-interface=IF_PSD_Attribut_4_Wert
      RP_IF_PSD_Attribut_5_ID_XIX_Klima: required-interface=IF_PSD_Attribut_5_ID
      RP_IF_PSD_Attribut_5_Offset_XIX_Klima: required-interface=IF_PSD_Attribut_5_Offset
      RP_IF_PSD_Attribut_5_Wert_XIX_Klima: required-interface=IF_PSD_Attribut_5_Wert
      RP_IF_PSD_Attribut_Segment_ID_05_XIX_Klima: required-interface=IF_PSD_Attribut_Segment_ID_05
      RP_IF_PSD_Attribut_Segment_ID_XIX_Klima: required-interface=IF_PSD_Attribut_Segment_ID
      RP_IF_PSD_Attribute_Komplett_05_XIX_Klima: required-interface=IF_PSD_Attribute_Komplett_05
      RP_IF_PSD_Attribute_Komplett_06_XIX_Klima: required-interface=IF_PSD_Attribute_Komplett_06
      RP_IF_PSD_Baum_Ausrichtung_XIX_Klima: required-interface=IF_PSD_Baum_Ausrichtung
      RP_IF_PSD_Baum_Breite_VZ_XIX_Klima: required-interface=IF_PSD_Baum_Breite_VZ
      RP_IF_PSD_Baum_Laenge_VZ_XIX_Klima: required-interface=IF_PSD_Baum_Laenge_VZ
      RP_IF_PSD_Baum_Laenge_XIX_Klima: required-interface=IF_PSD_Baum_Laenge
      RP_IF_PSD_Bebauung_XIX_Klima: required-interface=IF_PSD_Bebauung
      RP_IF_PSD_Endkruemmung_Vorz_XIX_Klima: required-interface=IF_PSD_Endkruemmung_Vorz
      RP_IF_PSD_Endkruemmung_XIX_Klima: required-interface=IF_PSD_Endkruemmung
      RP_IF_PSD_Fahrspuren_Anzahl_XIX_Klima: required-interface=IF_PSD_Fahrspuren_Anzahl
      RP_IF_PSD_Geradester_Pfad_XIX_Klima: required-interface=IF_PSD_Geradester_Pfad
      RP_IF_PSD_Ges_Attribute_Komplett_XIX_Klima: required-interface=IF_PSD_Ges_Attribute_Komplett
      RP_IF_PSD_Ges_Geschwindigkeit_Gespann_XIX_Klima: required-interface=IF_PSD_Ges_Geschwindigkeit_Gespann
      RP_IF_PSD_Ges_Geschwindigkeit_Std_Anf_XIX_Klima: required-interface=IF_PSD_Ges_Geschwindigkeit_Std_Anf
      RP_IF_PSD_Ges_Geschwindigkeit_Std_Ende_XIX_Klima: required-interface=IF_PSD_Ges_Geschwindigkeit_Std_Ende
      RP_IF_PSD_Ges_Geschwindigkeit_Tag_Anf_XIX_Klima: required-interface=IF_PSD_Ges_Geschwindigkeit_Tag_Anf
      RP_IF_PSD_Ges_Geschwindigkeit_Tag_Ende_XIX_Klima: required-interface=IF_PSD_Ges_Geschwindigkeit_Tag_Ende
      RP_IF_PSD_Ges_Geschwindigkeit_Witter_XIX_Klima: required-interface=IF_PSD_Ges_Geschwindigkeit_Witter
      RP_IF_PSD_Ges_Geschwindigkeit_XIX_Klima: required-interface=IF_PSD_Ges_Geschwindigkeit
      RP_IF_PSD_Ges_Gesetzlich_Kategorie_XIX_Klima: required-interface=IF_PSD_Ges_Gesetzlich_Kategorie
      RP_IF_PSD_Ges_Gesetzlich_Zusatz_XIX_Klima: required-interface=IF_PSD_Ges_Gesetzlich_Zusatz
      RP_IF_PSD_Ges_Offset_XIX_Klima: required-interface=IF_PSD_Ges_Offset
      RP_IF_PSD_Ges_Segment_ID_XIX_Klima: required-interface=IF_PSD_Ges_Segment_ID
      RP_IF_PSD_Ges_Spur_Geschw_Begrenzung_XIX_Klima: required-interface=IF_PSD_Ges_Spur_Geschw_Begrenzung
      RP_IF_PSD_Ges_Typ_XIX_Klima: required-interface=IF_PSD_Ges_Typ
      RP_IF_PSD_Ges_Ueberholverbot_XIX_Klima: required-interface=IF_PSD_Ges_Ueberholverbot
      RP_IF_PSD_Ges_Verkehrszeichen_Quelle_XIX_Klima: required-interface=IF_PSD_Ges_Verkehrszeichen_Quelle
      RP_IF_PSD_Ges_Wechselverkehrszeichen_XIX_Klima: required-interface=IF_PSD_Ges_Wechselverkehrszeichen
      RP_IF_PSD_Idenditaets_ID_XIX_Klima: required-interface=IF_PSD_Idenditaets_ID
      RP_IF_PSD_LR_01_MUX_XIX_Klima: required-interface=IF_PSD_LR_01_MUX
      RP_IF_PSD_LR_Attribut_1_Offset_XIX_Klima: required-interface=IF_PSD_LR_Attribut_1_Offset
      RP_IF_PSD_LR_Attribut_1_Wert_XIX_Klima: required-interface=IF_PSD_LR_Attribut_1_Wert
      RP_IF_PSD_LR_Attribut_2_Offset_XIX_Klima: required-interface=IF_PSD_LR_Attribut_2_Offset
      RP_IF_PSD_LR_Attribut_2_Wert_XIX_Klima: required-interface=IF_PSD_LR_Attribut_2_Wert
      RP_IF_PSD_LR_Attribut_3_Offset_XIX_Klima: required-interface=IF_PSD_LR_Attribut_3_Offset
      RP_IF_PSD_LR_Attribut_3_Wert_XIX_Klima: required-interface=IF_PSD_LR_Attribut_3_Wert
      RP_IF_PSD_LR_Fahrzeug_Pos_XIX_Klima: required-interface=IF_PSD_LR_Fahrzeug_Pos
      RP_IF_PSD_LR_Globale_Steigung_Vorz_XIX_Klima: required-interface=IF_PSD_LR_Globale_Steigung_Vorz
      RP_IF_PSD_LR_Globale_Steigung_XIX_Klima: required-interface=IF_PSD_LR_Globale_Steigung
      RP_IF_PSD_LR_Profil_Laenge_XIX_Klima: required-interface=IF_PSD_LR_Profil_Laenge
      RP_IF_PSD_LR_Profil_Nummer_XIX_Klima: required-interface=IF_PSD_LR_Profil_Nummer
      RP_IF_PSD_LR_Reset_XIX_Klima: required-interface=IF_PSD_LR_Reset
      RP_IF_PSD_LR_Steigung_1_Offset_XIX_Klima: required-interface=IF_PSD_LR_Steigung_1_Offset
      RP_IF_PSD_LR_Steigung_1_Vorz_XIX_Klima: required-interface=IF_PSD_LR_Steigung_1_Vorz
      RP_IF_PSD_LR_Steigung_1_Wert_XIX_Klima: required-interface=IF_PSD_LR_Steigung_1_Wert
      RP_IF_PSD_LR_Steigung_2_Offset_XIX_Klima: required-interface=IF_PSD_LR_Steigung_2_Offset
      RP_IF_PSD_LR_Steigung_2_Vorz_XIX_Klima: required-interface=IF_PSD_LR_Steigung_2_Vorz
      RP_IF_PSD_LR_Steigung_2_Wert_XIX_Klima: required-interface=IF_PSD_LR_Steigung_2_Wert
      RP_IF_PSD_LR_Steigung_3_Offset_XIX_Klima: required-interface=IF_PSD_LR_Steigung_3_Offset
      RP_IF_PSD_LR_Steigung_3_Vorz_XIX_Klima: required-interface=IF_PSD_LR_Steigung_3_Vorz
      RP_IF_PSD_LR_Steigung_3_Wert_XIX_Klima: required-interface=IF_PSD_LR_Steigung_3_Wert
      RP_IF_PSD_Pos_Fahrspur_XIX_Klima: required-interface=IF_PSD_Pos_Fahrspur
      RP_IF_PSD_Pos_Fehler_Laengsrichtung_XIX_Klima: required-interface=IF_PSD_Pos_Fehler_Laengsrichtung
      RP_IF_PSD_Pos_Inhibitzeit_XIX_Klima: required-interface=IF_PSD_Pos_Inhibitzeit
      RP_IF_PSD_Pos_Segment_ID_XIX_Klima: required-interface=IF_PSD_Pos_Segment_ID
      RP_IF_PSD_Pos_Segmentlaenge_XIX_Klima: required-interface=IF_PSD_Pos_Segmentlaenge
      RP_IF_PSD_Pos_Standort_Eindeutig_XIX_Klima: required-interface=IF_PSD_Pos_Standort_Eindeutig
      RP_IF_PSD_Rampe_XIX_Klima: required-interface=IF_PSD_Rampe
      RP_IF_PSD_Segment_ID_XIX_Klima: required-interface=IF_PSD_Segment_ID
      RP_IF_PSD_Segment_Komplett_XIX_Klima: required-interface=IF_PSD_Segment_Komplett
      RP_IF_PSD_Segmentlaenge_XIX_Klima: required-interface=IF_PSD_Segmentlaenge
      RP_IF_PSD_Steigung_1_A_Offset_XIX_Klima: required-interface=IF_PSD_Steigung_1_A_Offset
      RP_IF_PSD_Steigung_1_A_Steigung_XIX_Klima: required-interface=IF_PSD_Steigung_1_A_Steigung
      RP_IF_PSD_Steigung_1_A_Vorz_XIX_Klima: required-interface=IF_PSD_Steigung_1_A_Vorz
      RP_IF_PSD_Steigung_1_Attribute_kompl_XIX_Klima: required-interface=IF_PSD_Steigung_1_Attribute_kompl
      RP_IF_PSD_Steigung_1_B_Offset_XIX_Klima: required-interface=IF_PSD_Steigung_1_B_Offset
      RP_IF_PSD_Steigung_1_B_Steigung_XIX_Klima: required-interface=IF_PSD_Steigung_1_B_Steigung
      RP_IF_PSD_Steigung_1_B_Vorz_XIX_Klima: required-interface=IF_PSD_Steigung_1_B_Vorz
      RP_IF_PSD_Steigung_1_Segment_ID_XIX_Klima: required-interface=IF_PSD_Steigung_1_Segment_ID
      RP_IF_PSD_Steigung_2_Attribute_kompl_XIX_Klima: required-interface=IF_PSD_Steigung_2_Attribute_kompl
      RP_IF_PSD_Steigung_2_Offset_XIX_Klima: required-interface=IF_PSD_Steigung_2_Offset
      RP_IF_PSD_Steigung_2_Segment_ID_XIX_Klima: required-interface=IF_PSD_Steigung_2_Segment_ID
      RP_IF_PSD_Steigung_2_Steigung_XIX_Klima: required-interface=IF_PSD_Steigung_2_Steigung
      RP_IF_PSD_Steigung_2_Vorz_XIX_Klima: required-interface=IF_PSD_Steigung_2_Vorz
      RP_IF_PSD_Strassenkategorie_XIX_Klima: required-interface=IF_PSD_Strassenkategorie
      RP_IF_PSD_Sys_Alter_Karte_XIX_Klima: required-interface=IF_PSD_Sys_Alter_Karte
      RP_IF_PSD_Sys_Geometrieguete_erweitert_XIX_Klima: required-interface=IF_PSD_Sys_Geometrieguete_erweitert
      RP_IF_PSD_Sys_Geometrieguete_XIX_Klima: required-interface=IF_PSD_Sys_Geometrieguete
      RP_IF_PSD_Sys_Geschwindigkeit_Einheit_XIX_Klima: required-interface=IF_PSD_Sys_Geschwindigkeit_Einheit
      RP_IF_PSD_Sys_Laendercode_XIX_Klima: required-interface=IF_PSD_Sys_Laendercode
      RP_IF_PSD_Sys_Mapmatchingguete_XIX_Klima: required-interface=IF_PSD_Sys_Mapmatchingguete
      RP_IF_PSD_Sys_Quali_Geometrien_XIX_Klima: required-interface=IF_PSD_Sys_Quali_Geometrien
      RP_IF_PSD_Sys_Quali_Ortsinfo_XIX_Klima: required-interface=IF_PSD_Sys_Quali_Ortsinfo
      RP_IF_PSD_Sys_Quali_sonstige_Attribute_XIX_Klima: required-interface=IF_PSD_Sys_Quali_sonstige_Attribute
      RP_IF_PSD_Sys_Quali_Steigungen_XIX_Klima: required-interface=IF_PSD_Sys_Quali_Steigungen
      RP_IF_PSD_Sys_Quali_Strassenkennz_XIX_Klima: required-interface=IF_PSD_Sys_Quali_Strassenkennz
      RP_IF_PSD_Sys_Quali_Tempolimits_XIX_Klima: required-interface=IF_PSD_Sys_Quali_Tempolimits
      RP_IF_PSD_Sys_Quali_verfuegbar_XIX_Klima: required-interface=IF_PSD_Sys_Quali_verfuegbar
      RP_IF_PSD_Sys_Quali_Vorfahrtsregelung_XIX_Klima: required-interface=IF_PSD_Sys_Quali_Vorfahrtsregelung
      RP_IF_PSD_Sys_Segment_ID_XIX_Klima: required-interface=IF_PSD_Sys_Segment_ID
      RP_IF_PSD_Sys_US_State_XIX_Klima: required-interface=IF_PSD_Sys_US_State
      RP_IF_PSD_Sys_Verkehrsrichtung_XIX_Klima: required-interface=IF_PSD_Sys_Verkehrsrichtung
      RP_IF_PSD_Sys_Zielfuehrung_geaendert_XIX_Klima: required-interface=IF_PSD_Sys_Zielfuehrung_geaendert
      RP_IF_PSD_Sys_Zielfuehrung_XIX_Klima: required-interface=IF_PSD_Sys_Zielfuehrung
      RP_IF_PSD_Vorgaenger_Segment_ID_XIX_Klima: required-interface=IF_PSD_Vorgaenger_Segment_ID
      RP_IF_PSD_wahrscheinlichster_Pfad_XIX_Klima: required-interface=IF_PSD_wahrscheinlichster_Pfad
      RP_IF_PSD_Wechselverkehrszeichen_Typ_XIX_Klima: required-interface=IF_PSD_Wechselverkehrszeichen_Typ
      RP_IF_PTC_HV_Err_Heizkreis_1_TNCTOC_XIX_Klima: required-interface=IF_PTC_HV_Err_Heizkreis_1_TNCTOC
      RP_IF_PTC_HV_Err_Heizkreis_1_XIX_Klima: required-interface=IF_PTC_HV_Err_Heizkreis_1
      RP_IF_PTC_HV_Err_Heizkreis_2_TNCTOC_XIX_Klima: required-interface=IF_PTC_HV_Err_Heizkreis_2_TNCTOC
      RP_IF_PTC_HV_Err_Heizkreis_2_XIX_Klima: required-interface=IF_PTC_HV_Err_Heizkreis_2
      RP_IF_PTC_HV_Err_Heizkreis_3_TNCTOC_XIX_Klima: required-interface=IF_PTC_HV_Err_Heizkreis_3_TNCTOC
      RP_IF_PTC_HV_Err_Heizkreis_3_XIX_Klima: required-interface=IF_PTC_HV_Err_Heizkreis_3
      RP_IF_PTC_HV_Err_Intern_TNCTOC_XIX_Klima: required-interface=IF_PTC_HV_Err_Intern_TNCTOC
      RP_IF_PTC_HV_Err_intern_XIX_Klima: required-interface=IF_PTC_HV_Err_intern
      RP_IF_PTC_HV_Err_Leckagestrom_TNCTOC_XIX_Klima: required-interface=IF_PTC_HV_Err_Leckagestrom_TNCTOC
      RP_IF_PTC_HV_Err_Leckagestrom_XIX_Klima: required-interface=IF_PTC_HV_Err_Leckagestrom
      RP_IF_PTC_HV_Err_Temperaturschutz_XIX_Klima: required-interface=IF_PTC_HV_Err_Temperaturschutz
      RP_IF_PTC_HV_Err_TempSchutz_TNCTOC_XIX_Klima: required-interface=IF_PTC_HV_Err_TempSchutz_TNCTOC
      RP_IF_PTC_HV_ERR_TNCTOC_XIX_Klima: required-interface=IF_PTC_HV_ERR_TNCTOC
      RP_IF_PTC_HV_Err_Ueberstromabs_TNCTOC_XIX_Klima: required-interface=IF_PTC_HV_Err_Ueberstromabs_TNCTOC
      RP_IF_PTC_HV_Err_Ueberstromabschaltung_XIX_Klima: required-interface=IF_PTC_HV_Err_Ueberstromabschaltung
      RP_IF_PTC_HV_ERR_XIX_Klima: required-interface=IF_PTC_HV_ERR
      RP_IF_PTC_HV_Heizmedium_Sensor_1_XIX_Klima: required-interface=IF_PTC_HV_Heizmedium_Sensor_1
      RP_IF_PTC_HV_Heizmedium_Sensor_2_XIX_Klima: required-interface=IF_PTC_HV_Heizmedium_Sensor_2
      RP_IF_PTC_HV_I_ist_XIX_Klima: required-interface=IF_PTC_HV_I_ist
      RP_IF_PTC_HV_ResponseError_XIX_Klima: required-interface=IF_PTC_HV_ResponseError
      RP_IF_PTC_HV_Status_PTC_XIX_Klima: required-interface=IF_PTC_HV_Status_PTC
      RP_IF_PTC_HV_Status_UBatt_XIX_Klima: required-interface=IF_PTC_HV_Status_UBatt
      RP_IF_PTC_HV_Temp_PCB_XIX_Klima: required-interface=IF_PTC_HV_Temp_PCB
      RP_IF_PTC_HV_TimeOut_Fehler_XIX_Klima: required-interface=IF_PTC_HV_TimeOut_Fehler
      RP_IF_PTC_HV_UBatt_XIX_Klima: required-interface=IF_PTC_HV_UBatt
      RP_IF_PTC_HVb_Err_Heizkreis_1_TNCTOC_XIX_Klima: required-interface=IF_PTC_HVb_Err_Heizkreis_1_TNCTOC
      RP_IF_PTC_HVb_Err_Heizkreis_1_XIX_Klima: required-interface=IF_PTC_HVb_Err_Heizkreis_1
      RP_IF_PTC_HVb_Err_Heizkreis_2_TNCTOC_XIX_Klima: required-interface=IF_PTC_HVb_Err_Heizkreis_2_TNCTOC
      RP_IF_PTC_HVb_Err_Heizkreis_2_XIX_Klima: required-interface=IF_PTC_HVb_Err_Heizkreis_2
      RP_IF_PTC_HVb_Err_Heizkreis_3_TNCTOC_XIX_Klima: required-interface=IF_PTC_HVb_Err_Heizkreis_3_TNCTOC
      RP_IF_PTC_HVb_Err_Heizkreis_3_XIX_Klima: required-interface=IF_PTC_HVb_Err_Heizkreis_3
      RP_IF_PTC_HVb_Err_Intern_TNCTOC_XIX_Klima: required-interface=IF_PTC_HVb_Err_Intern_TNCTOC
      RP_IF_PTC_HVb_Err_intern_XIX_Klima: required-interface=IF_PTC_HVb_Err_intern
      RP_IF_PTC_HVb_Err_Leckagestrom_TNCTOC_XIX_Klima: required-interface=IF_PTC_HVb_Err_Leckagestrom_TNCTOC
      RP_IF_PTC_HVb_Err_Leckagestrom_XIX_Klima: required-interface=IF_PTC_HVb_Err_Leckagestrom
      RP_IF_PTC_HVb_Err_Temperaturschutz_XIX_Klima: required-interface=IF_PTC_HVb_Err_Temperaturschutz
      RP_IF_PTC_HVb_Err_TempSchutz_TNCTOC_XIX_Klima: required-interface=IF_PTC_HVb_Err_TempSchutz_TNCTOC
      RP_IF_PTC_HVb_ERR_TNCTOC_XIX_Klima: required-interface=IF_PTC_HVb_ERR_TNCTOC
      RP_IF_PTC_HVb_Err_Ueberstromabs_TNCTOC_XIX_Klima: required-interface=IF_PTC_HVb_Err_Ueberstromabs_TNCTOC
      RP_IF_PTC_HVb_Err_Ueberstromabschaltung_XIX_Klima: required-interface=IF_PTC_HVb_Err_Ueberstromabschaltung
      RP_IF_PTC_HVb_ERR_XIX_Klima: required-interface=IF_PTC_HVb_ERR
      RP_IF_PTC_HVb_Heizmedium_Sensor_1_XIX_Klima: required-interface=IF_PTC_HVb_Heizmedium_Sensor_1
      RP_IF_PTC_HVb_Heizmedium_Sensor_2_XIX_Klima: required-interface=IF_PTC_HVb_Heizmedium_Sensor_2
      RP_IF_PTC_HVb_I_ist_XIX_Klima: required-interface=IF_PTC_HVb_I_ist
      RP_IF_PTC_HVb_ResponseError_XIX_Klima: required-interface=IF_PTC_HVb_ResponseError
      RP_IF_PTC_HVb_Status_PTC_XIX_Klima: required-interface=IF_PTC_HVb_Status_PTC
      RP_IF_PTC_HVb_Status_UBatt_XIX_Klima: required-interface=IF_PTC_HVb_Status_UBatt
      RP_IF_PTC_HVb_Temp_PCB_XIX_Klima: required-interface=IF_PTC_HVb_Temp_PCB
      RP_IF_PTC_HVb_TimeOut_Fehler_XIX_Klima: required-interface=IF_PTC_HVb_TimeOut_Fehler
      RP_IF_PTC_HVb_UBatt_XIX_Klima: required-interface=IF_PTC_HVb_UBatt
      RP_IF_PTC_HW_XIX_Klima: required-interface=IF_PTC_HW
      RP_IF_PTC_I_ist_XIX_Klima: required-interface=IF_PTC_I_ist
      RP_IF_PTC_P_ist_XIX_Klima: required-interface=IF_PTC_P_ist
      RP_IF_PTC_ResponseError_XIX_Klima: required-interface=IF_PTC_ResponseError
      RP_IF_PTC_Status_PTC_XIX_Klima: required-interface=IF_PTC_Status_PTC
      RP_IF_PTC_Status_UBatt_XIX_Klima: required-interface=IF_PTC_Status_UBatt
      RP_IF_PTC_Status_XIX_Klima: required-interface=IF_PTC_Status
      RP_IF_PTC_SW_XIX_Klima: required-interface=IF_PTC_SW
      RP_IF_PTC_Temp_PCB_XIX_Klima: required-interface=IF_PTC_Temp_PCB
      RP_IF_PTC_TimeOut_Fehler_XIX_Klima: required-interface=IF_PTC_TimeOut_Fehler
      RP_IF_PTC_UBatt_XIX_Klima: required-interface=IF_PTC_UBatt
      RP_IF_RS_defekt_XIX_Klima: required-interface=IF_RS_defekt
      RP_IF_RS_Regenmenge_XIX_Klima: required-interface=IF_RS_Regenmenge
      RP_IF_RS_Wischergeschwindigkeit_XIX_Klima: required-interface=IF_RS_Wischergeschwindigkeit
      RP_IF_SI_BUS_04_XIX_Klima: required-interface=IF_SI_BUS_04
      RP_IF_SI_CAB_V15_XIX_Klima: required-interface=IF_SI_CAB_V15
      RP_IF_SI_NWDF_gueltig_XIX_Klima: required-interface=IF_SI_NWDF_gueltig
      RP_IF_SI_NWDF_XIX_Klima: required-interface=IF_SI_NWDF
      RP_IF_SI_P_Mode_gueltig_XIX_Klima: required-interface=IF_SI_P_Mode_gueltig
      RP_IF_SI_P_Mode_XIX_Klima: required-interface=IF_SI_P_Mode
      RP_IF_SI_QRS_Mode_XIX_Klima: required-interface=IF_SI_QRS_Mode
      RP_IF_SI_T_Mode_XIX_Klima: required-interface=IF_SI_T_Mode
      RP_IF_SI_T_Schutz_XIX_Klima: required-interface=IF_SI_T_Schutz
      RP_IF_SIL_Stufe_LED_li_XIX_Klima: required-interface=IF_SIL_Stufe_LED_li
      RP_IF_SIL_Stufe_LED_re_XIX_Klima: required-interface=IF_SIL_Stufe_LED_re
      RP_IF_SMod_SIH_Stufe_hl_XIX_Klima: required-interface=IF_SMod_SIH_Stufe_hl
      RP_IF_SMod_SIH_Stufe_hr_XIX_Klima: required-interface=IF_SMod_SIH_Stufe_hr
      RP_IF_SMod_SIL_Stufe_hl_XIX_Klima: required-interface=IF_SMod_SIL_Stufe_hl
      RP_IF_SMod_SIL_Stufe_hr_XIX_Klima: required-interface=IF_SMod_SIL_Stufe_hr
      RP_IF_SMod_SRH_Fehler_XIX_Klima: required-interface=IF_SMod_SRH_Fehler
      RP_IF_SMod_SRH_ResponseError_XIX_Klima: required-interface=IF_SMod_SRH_ResponseError
      RP_IF_SOK_FoD_Klima_Resp_Challenge_XIX_Klima: required-interface=IF_SOK_FoD_Klima_Resp_Challenge
      RP_IF_SoSe_SunInt_2D_Li_XIX_Klima: required-interface=IF_SoSe_SunInt_2D_Li
      RP_IF_SoSe_SunInt_2D_Re_XIX_Klima: required-interface=IF_SoSe_SunInt_2D_Re
      RP_IF_ST_VLD_BLW_CTRL_1_LIN_XIX_Klima: required-interface=IF_ST_VLD_BLW_CTRL_1_LIN
      RP_IF_ST_VLD_BLWb_CTRL_1_LIN_XIX_Klima: required-interface=IF_ST_VLD_BLWb_CTRL_1_LIN
      RP_IF_ST_VLD_BLWc_CTRL_1_LIN_XIX_Klima: required-interface=IF_ST_VLD_BLWc_CTRL_1_LIN
      RP_IF_STK_AirCLeaner_Anf_XIX_Klima: required-interface=IF_STK_AirCLeaner_Anf
      RP_IF_STK_Anf_AussenspiegelHZ_XIX_Klima: required-interface=IF_STK_Anf_AussenspiegelHZ
      RP_IF_STK_Berechnungsphase_XIX_Klima: required-interface=IF_STK_Berechnungsphase
      RP_IF_STK_Betriebsdauer_XIX_Klima: required-interface=IF_STK_Betriebsdauer
      RP_IF_STK_ErwVK_Anf_XIX_Klima: required-interface=IF_STK_ErwVK_Anf
      RP_IF_STK_ErwVK_Beifahrerzone_XIX_Klima: required-interface=IF_STK_ErwVK_Beifahrerzone
      RP_IF_STK_ErwVK_Fahrerzone_XIX_Klima: required-interface=IF_STK_ErwVK_Fahrerzone
      RP_IF_STK_ErwVK_Heckzone_links_XIX_Klima: required-interface=IF_STK_ErwVK_Heckzone_links
      RP_IF_STK_ErwVK_Heckzone_rechts_XIX_Klima: required-interface=IF_STK_ErwVK_Heckzone_rechts
      RP_IF_STK_ErwVK_Modus_XIX_Klima: required-interface=IF_STK_ErwVK_Modus
      RP_IF_STK_ErwVK_Scheibenheizung_XIX_Klima: required-interface=IF_STK_ErwVK_Scheibenheizung
      RP_IF_STK_FSH_Anf_XIX_Klima: required-interface=IF_STK_FSH_Anf
      RP_IF_STK_HSH_Anf_XIX_Klima: required-interface=IF_STK_HSH_Anf
      RP_IF_STK_Klima_Temp_XIX_Klima: required-interface=IF_STK_Klima_Temp
      RP_IF_STK_KurzVK_Anf_XIX_Klima: required-interface=IF_STK_KurzVK_Anf
      RP_IF_STK_Sofortstart_Sperre_FFB_XIX_Klima: required-interface=IF_STK_Sofortstart_Sperre_FFB
      RP_IF_STK_Standklima_Anf_XIX_Klima: required-interface=IF_STK_Standklima_Anf
      RP_IF_STK_Standklima_Timer_Status_XIX_Klima: required-interface=IF_STK_Standklima_Timer_Status
      RP_IF_STK_VK_Modus_XIX_Klima: required-interface=IF_STK_VK_Modus
      RP_IF_TSK_QBit_Steigung_XIX_Klima: required-interface=IF_TSK_QBit_Steigung
      RP_IF_TSK_Steigung_02_XIX_Klima: required-interface=IF_TSK_Steigung_02
      RP_IF_UH_Jahr_XIX_Klima: required-interface=IF_UH_Jahr
      RP_IF_UH_Minute_XIX_Klima: required-interface=IF_UH_Minute
      RP_IF_UH_Monat_XIX_Klima: required-interface=IF_UH_Monat
      RP_IF_UH_Sekunde_XIX_Klima: required-interface=IF_UH_Sekunde
      RP_IF_UH_Stunde_XIX_Klima: required-interface=IF_UH_Stunde
      RP_IF_UH_Tag_XIX_Klima: required-interface=IF_UH_Tag
      RP_IF_UIF_Itos_roh_XIX_Klima: required-interface=IF_UIF_Itos_roh
      RP_IF_UIF_Ref_roh_XIX_Klima: required-interface=IF_UIF_Ref_roh
      RP_IF_UIF_ResponseError_XIX_Klima: required-interface=IF_UIF_ResponseError
      RP_IF_UIF_Status_XIX_Klima: required-interface=IF_UIF_Status
      RP_IF_UIF_Sun_roh_XIX_Klima: required-interface=IF_UIF_Sun_roh
      RP_IF_UIF_SunInt_XIX_Klima: required-interface=IF_UIF_SunInt
      RP_IF_UIF_Temp_OutOfRange_XIX_Klima: required-interface=IF_UIF_Temp_OutOfRange
      RP_IF_UIF_Temperatur_XIX_Klima: required-interface=IF_UIF_Temperatur
      RP_IF_Vehicle_Driving_Cycle_XIX_Klima: required-interface=IF_Vehicle_Driving_Cycle
      RP_IF_VIN_01_MUX_XIX_Klima: required-interface=IF_VIN_01_MUX
      RP_IF_VIN_{10..17}_XIX_Klima: required-interface=IF_VIN_{10..17}
      RP_IF_VIN_{1..9}_XIX_Klima: required-interface=IF_VIN_{1..9}
      RP_IF_Waschen_vorne_aktiv_XIX_Klima: required-interface=IF_Waschen_vorne_aktiv
      RP_IF_Wischer1_Wischgeschwindigkeit_XIX_Klima: required-interface=IF_Wischer1_Wischgeschwindigkeit
      RP_IF_Wischer_vorne_aktiv_XIX_Klima: required-interface=IF_Wischer_vorne_aktiv
      RP_IF_Wischer_vorne_defekt_XIX_Klima: required-interface=IF_Wischer_vorne_defekt
      RP_IF_ZAS_Kl_15_XIX_Klima: required-interface=IF_ZAS_Kl_15
      RP_IF_ZAS_Kl_S_XIX_Klima: required-interface=IF_ZAS_Kl_S
      RP_IF_ZM_Standzeit_XIX_Klima: required-interface=IF_ZM_Standzeit
      RP_IF_ZV_BT_offen_XIX_Klima: required-interface=IF_ZV_BT_offen
      RP_IF_ZV_FT_offen_XIX_Klima: required-interface=IF_ZV_FT_offen
      RP_IF_ZV_gesafet_extern_ist_XIX_Klima: required-interface=IF_ZV_gesafet_extern_ist
      RP_IF_ZV_HBFS_offen_XIX_Klima: required-interface=IF_ZV_HBFS_offen
      RP_IF_ZV_HD_offen_XIX_Klima: required-interface=IF_ZV_HD_offen
      RP_IF_ZV_HFS_offen_XIX_Klima: required-interface=IF_ZV_HFS_offen
      RP_IF_ZV_Schluessel_Zugang_XIX_Klima: required-interface=IF_ZV_Schluessel_Zugang
      RP_IF_ZV_verriegelt_extern_ist_XIX_Klima: required-interface=IF_ZV_verriegelt_extern_ist
      RP_IF_ZV_verriegelt_extern_soll_XIX_Klima: required-interface=IF_ZV_verriegelt_extern_soll
      RP_IF_ZV_verriegelt_intern_ist_XIX_Klima: required-interface=IF_ZV_verriegelt_intern_ist
      RP_IF_ZV_verriegelt_intern_soll_XIX_Klima: required-interface=IF_ZV_verriegelt_intern_soll
    5 x component:
      Grundumfang_XIX_Klima: type=Grundumfang_XIX_Klima
      HVEM_Auto_NL_XIX_Klima: type=HVEM_Auto_NL_XIX_Klima
      KlimaStandklimatisierung_Klima_C_XIX_Standklima_XIX_Klima: type=KlimaStandklimatisierung_Klima_C_XIX_Standklima_XIX_Klima
      SC_447_FoD_Slave_8_XIX_Softwareblock_XIX_Klima: type=SC_447_FoD_Slave_8_XIX_Softwareblock_XIX_Klima
      VKMS_XIX_Klima: type=VKMS_XIX_Klima
    delegate Grundumfang_XIX_Klima.RP_IF_AB_Abschaltanf_SIH_BF_XIX_Grundumfang_XIX_Klima <-> outer port RP_IF_AB_Abschaltanf_SIH_BF_XIX_Klima
    delegate Grundumfang_XIX_Klima.RP_IF_AB_Belegung_VB_XIX_Grundumfang_XIX_Klima <-> outer port RP_IF_AB_Belegung_VB_XIX_Klima
    delegate Grundumfang_XIX_Klima.RP_IF_AB_Belegung_VF_ext_XIX_Grundumfang_XIX_Klima <-> outer port RP_IF_AB_Belegung_VF_ext_XIX_Klima
    delegate Grundumfang_XIX_Klima.RP_IF_AB_Belegung_VF_XIX_Grundumfang_XIX_Klima <-> outer port RP_IF_AB_Belegung_VF_XIX_Klima
    delegate Grundumfang_XIX_Klima.RP_IF_AB_Crash_Int_XIX_Grundumfang_XIX_Klima <-> outer port RP_IF_AB_Crash_Int_XIX_Klima
    delegate Grundumfang_XIX_Klima.RP_IF_AB_Deaktivierung_HV_XIX_Grundumfang_XIX_Klima <-> outer port RP_IF_AB_Deaktivierung_HV_XIX_Klima
    delegate Grundumfang_XIX_Klima.RP_IF_AB_Gurtschloss_BF_XIX_Grundumfang_XIX_Klima <-> outer port RP_IF_AB_Gurtschloss_BF_XIX_Klima
    delegate Grundumfang_XIX_Klima.RP_IF_AB_Gurtschloss_FA_XIX_Grundumfang_XIX_Klima <-> outer port RP_IF_AB_Gurtschloss_FA_XIX_Klima
    delegate Grundumfang_XIX_Klima.RP_IF_AB_Gurtschloss_MI_XIX_Grundumfang_XIX_Klima <-> outer port RP_IF_AB_Gurtschloss_MI_XIX_Klima
    delegate Grundumfang_XIX_Klima.RP_IF_AB_Gurtschloss_Reihe2_BF_XIX_Grundumfang_XIX_Klima <-> outer port RP_IF_AB_Gurtschloss_Reihe2_BF_XIX_Klima
    delegate Grundumfang_XIX_Klima.RP_IF_AB_Gurtschloss_Reihe2_FA_XIX_Grundumfang_XIX_Klima <-> outer port RP_IF_AB_Gurtschloss_Reihe2_FA_XIX_Klima
    delegate Grundumfang_XIX_Klima.RP_IF_AB_Gurtschloss_Reihe2_MI_XIX_Grundumfang_XIX_Klima <-> outer port RP_IF_AB_Gurtschloss_Reihe2_MI_XIX_Klima
    delegate Grundumfang_XIX_Klima.RP_IF_AB_Gurtschloss_Reihe3_BF_XIX_Grundumfang_XIX_Klima <-> outer port RP_IF_AB_Gurtschloss_Reihe3_BF_XIX_Klima
    delegate Grundumfang_XIX_Klima.RP_IF_AB_Gurtschloss_Reihe3_FA_XIX_Grundumfang_XIX_Klima <-> outer port RP_IF_AB_Gurtschloss_Reihe3_FA_XIX_Klima
    delegate Grundumfang_XIX_Klima.RP_IF_AB_Gurtschloss_Reihe3_MI_XIX_Grundumfang_XIX_Klima <-> outer port RP_IF_AB_Gurtschloss_Reihe3_MI_XIX_Klima
    delegate Grundumfang_XIX_Klima.RP_IF_AB_Gurtwarn_Reihe2_BF_XIX_Grundumfang_XIX_Klima <-> outer port RP_IF_AB_Gurtwarn_Reihe2_BF_XIX_Klima
    delegate Grundumfang_XIX_Klima.RP_IF_AB_Gurtwarn_Reihe2_FA_XIX_Grundumfang_XIX_Klima <-> outer port RP_IF_AB_Gurtwarn_Reihe2_FA_XIX_Klima
    delegate Grundumfang_XIX_Klima.RP_IF_AB_Gurtwarn_Reihe2_MI_XIX_Grundumfang_XIX_Klima <-> outer port RP_IF_AB_Gurtwarn_Reihe2_MI_XIX_Klima
    delegate Grundumfang_XIX_Klima.RP_IF_AB_Gurtwarn_Reihe3_BF_XIX_Grundumfang_XIX_Klima <-> outer port RP_IF_AB_Gurtwarn_Reihe3_BF_XIX_Klima
    delegate Grundumfang_XIX_Klima.RP_IF_AB_Gurtwarn_Reihe3_FA_XIX_Grundumfang_XIX_Klima <-> outer port RP_IF_AB_Gurtwarn_Reihe3_FA_XIX_Klima
    delegate Grundumfang_XIX_Klima.RP_IF_AB_Gurtwarn_Reihe3_MI_XIX_Grundumfang_XIX_Klima <-> outer port RP_IF_AB_Gurtwarn_Reihe3_MI_XIX_Klima
    delegate Grundumfang_XIX_Klima.RP_IF_AB_Gurtwarn_VM_XIX_Grundumfang_XIX_Klima <-> outer port RP_IF_AB_Gurtwarn_VM_XIX_Klima
    delegate Grundumfang_XIX_Klima.RP_IF_AB_SBR_hinten_verbau_XIX_Grundumfang_XIX_Klima <-> outer port RP_IF_AB_SBR_hinten_verbau_XIX_Klima
    delegate Grundumfang_XIX_Klima.RP_IF_AB_Stellgliedtest_XIX_Grundumfang_XIX_Klima <-> outer port RP_IF_AB_Stellgliedtest_XIX_Klima
    delegate Grundumfang_XIX_Klima.RP_IF_ACT401_Adresse_Aktuator_XIX_Grundumfang_XIX_Klima <-> outer port RP_IF_ACT401_Adresse_Aktuator_XIX_Klima
    delegate Grundumfang_XIX_Klima.RP_IF_ACT401_Blockierung_aufgetreten_XIX_Grundumfang_XIX_Klima <-> outer port RP_IF_ACT401_Blockierung_aufgetreten_XIX_Klima
    delegate Grundumfang_XIX_Klima.RP_IF_ACT401_Drehrichtung_XIX_Grundumfang_XIX_Klima <-> outer port RP_IF_ACT401_Drehrichtung_XIX_Klima
    delegate Grundumfang_XIX_Klima.RP_IF_ACT401_Elektr_Defekt_XIX_Grundumfang_XIX_Klima <-> outer port RP_IF_ACT401_Elektr_Defekt_XIX_Klima
    delegate Grundumfang_XIX_Klima.RP_IF_ACT401_Freigabe_Blockiererkennung_XIX_Grundumfang_XIX_Klima <-> outer port RP_IF_ACT401_Freigabe_Blockiererkennung_XIX_Klima
    delegate Grundumfang_XIX_Klima.RP_IF_ACT401_Geschwindigkeitsstatus_XIX_Grundumfang_XIX_Klima <-> outer port RP_IF_ACT401_Geschwindigkeitsstatus_XIX_Klima
    delegate Grundumfang_XIX_Klima.RP_IF_ACT401_Ist_Position_Aktuator_XIX_Grundumfang_XIX_Klima <-> outer port RP_IF_ACT401_Ist_Position_Aktuator_XIX_Klima
    delegate Grundumfang_XIX_Klima.RP_IF_ACT401_Notlauf_aufgetreten_XIX_Grundumfang_XIX_Klima <-> outer port RP_IF_ACT401_Notlauf_aufgetreten_XIX_Klima
    delegate Grundumfang_XIX_Klima.RP_IF_ACT401_Notlauffreigabe_XIX_Grundumfang_XIX_Klima <-> outer port RP_IF_ACT401_Notlauffreigabe_XIX_Klima
    delegate Grundumfang_XIX_Klima.RP_IF_ACT401_Notlaufposition_XIX_Grundumfang_XIX_Klima <-> outer port RP_IF_ACT401_Notlaufposition_XIX_Klima
    delegate Grundumfang_XIX_Klima.RP_IF_ACT401_Positionsvorgabe_Status_XIX_Grundumfang_XIX_Klima <-> outer port RP_IF_ACT401_Positionsvorgabe_Status_XIX_Klima
    delegate Grundumfang_XIX_Klima.RP_IF_ACT401_Reset_XIX_Grundumfang_XIX_Klima <-> outer port RP_IF_ACT401_Reset_XIX_Klima
    delegate Grundumfang_XIX_Klima.RP_IF_ACT401_ResponseError_XIX_Grundumfang_XIX_Klima <-> outer port RP_IF_ACT401_ResponseError_XIX_Klima
    delegate Grundumfang_XIX_Klima.RP_IF_ACT401_Selbsthaltemoment_XIX_Grundumfang_XIX_Klima <-> outer port RP_IF_ACT401_Selbsthaltemoment_XIX_Klima
    delegate Grundumfang_XIX_Klima.RP_IF_ACT401_Sonderfunktionen_XIX_Grundumfang_XIX_Klima <-> outer port RP_IF_ACT401_Sonderfunktionen_XIX_Klima
    delegate Grundumfang_XIX_Klima.RP_IF_ACT401_Spulenbestromung_XIX_Grundumfang_XIX_Klima <-> outer port RP_IF_ACT401_Spulenbestromung_XIX_Klima
    delegate Grundumfang_XIX_Klima.RP_IF_ACT401_Stopmodus_XIX_Grundumfang_XIX_Klima <-> outer port RP_IF_ACT401_Stopmodus_XIX_Klima
    delegate Grundumfang_XIX_Klima.RP_IF_ACT401_Uebertemperatur_XIX_Grundumfang_XIX_Klima <-> outer port RP_IF_ACT401_Uebertemperatur_XIX_Klima
    delegate Grundumfang_XIX_Klima.RP_IF_ACT401_Variante_XIX_Grundumfang_XIX_Klima <-> outer port RP_IF_ACT401_Variante_XIX_Klima
    delegate Grundumfang_XIX_Klima.RP_IF_ACT401_Verfahrrichtung_XIX_Grundumfang_XIX_Klima <-> outer port RP_IF_ACT401_Verfahrrichtung_XIX_Klima
    delegate Grundumfang_XIX_Klima.RP_IF_ACT401_Versorgungsspannung_XIX_Grundumfang_XIX_Klima <-> outer port RP_IF_ACT401_Versorgungsspannung_XIX_Klima
    delegate Grundumfang_XIX_Klima.RP_IF_ACT402_Adresse_Aktuator_XIX_Grundumfang_XIX_Klima <-> outer port RP_IF_ACT402_Adresse_Aktuator_XIX_Klima
    delegate Grundumfang_XIX_Klima.RP_IF_ACT402_Blockierung_aufgetreten_XIX_Grundumfang_XIX_Klima <-> outer port RP_IF_ACT402_Blockierung_aufgetreten_XIX_Klima
    delegate Grundumfang_XIX_Klima.RP_IF_ACT402_Drehrichtung_XIX_Grundumfang_XIX_Klima <-> outer port RP_IF_ACT402_Drehrichtung_XIX_Klima
    delegate Grundumfang_XIX_Klima.RP_IF_ACT402_Elektr_Defekt_XIX_Grundumfang_XIX_Klima <-> outer port RP_IF_ACT402_Elektr_Defekt_XIX_Klima
    delegate Grundumfang_XIX_Klima.RP_IF_ACT402_Freigabe_Blockiererkennung_XIX_Grundumfang_XIX_Klima <-> outer port RP_IF_ACT402_Freigabe_Blockiererkennung_XIX_Klima
    delegate Grundumfang_XIX_Klima.RP_IF_ACT402_Geschwindigkeitsstatus_XIX_Grundumfang_XIX_Klima <-> outer port RP_IF_ACT402_Geschwindigkeitsstatus_XIX_Klima
    delegate Grundumfang_XIX_Klima.RP_IF_ACT402_Ist_Position_Aktuator_XIX_Grundumfang_XIX_Klima <-> outer port RP_IF_ACT402_Ist_Position_Aktuator_XIX_Klima
    delegate Grundumfang_XIX_Klima.RP_IF_ACT402_Notlauf_aufgetreten_XIX_Grundumfang_XIX_Klima <-> outer port RP_IF_ACT402_Notlauf_aufgetreten_XIX_Klima
    delegate Grundumfang_XIX_Klima.RP_IF_ACT402_Notlauffreigabe_XIX_Grundumfang_XIX_Klima <-> outer port RP_IF_ACT402_Notlauffreigabe_XIX_Klima
    delegate Grundumfang_XIX_Klima.RP_IF_ACT402_Notlaufposition_XIX_Grundumfang_XIX_Klima <-> outer port RP_IF_ACT402_Notlaufposition_XIX_Klima
    delegate Grundumfang_XIX_Klima.RP_IF_ACT402_Positionsvorgabe_Status_XIX_Grundumfang_XIX_Klima <-> outer port RP_IF_ACT402_Positionsvorgabe_Status_XIX_Klima
    delegate Grundumfang_XIX_Klima.RP_IF_ACT402_Reset_XIX_Grundumfang_XIX_Klima <-> outer port RP_IF_ACT402_Reset_XIX_Klima
    delegate Grundumfang_XIX_Klima.RP_IF_ACT402_ResponseError_XIX_Grundumfang_XIX_Klima <-> outer port RP_IF_ACT402_ResponseError_XIX_Klima
    delegate Grundumfang_XIX_Klima.RP_IF_ACT402_Selbsthaltemoment_XIX_Grundumfang_XIX_Klima <-> outer port RP_IF_ACT402_Selbsthaltemoment_XIX_Klima
    delegate Grundumfang_XIX_Klima.RP_IF_ACT402_Sonderfunktionen_XIX_Grundumfang_XIX_Klima <-> outer port RP_IF_ACT402_Sonderfunktionen_XIX_Klima
    delegate Grundumfang_XIX_Klima.RP_IF_ACT402_Spulenbestromung_XIX_Grundumfang_XIX_Klima <-> outer port RP_IF_ACT402_Spulenbestromung_XIX_Klima
    delegate Grundumfang_XIX_Klima.RP_IF_ACT402_Stopmodus_XIX_Grundumfang_XIX_Klima <-> outer port RP_IF_ACT402_Stopmodus_XIX_Klima
    delegate Grundumfang_XIX_Klima.RP_IF_ACT402_Uebertemperatur_XIX_Grundumfang_XIX_Klima <-> outer port RP_IF_ACT402_Uebertemperatur_XIX_Klima
    delegate Grundumfang_XIX_Klima.RP_IF_ACT402_Variante_XIX_Grundumfang_XIX_Klima <-> outer port RP_IF_ACT402_Variante_XIX_Klima
    delegate Grundumfang_XIX_Klima.RP_IF_ACT402_Verfahrrichtung_XIX_Grundumfang_XIX_Klima <-> outer port RP_IF_ACT402_Verfahrrichtung_XIX_Klima
    delegate Grundumfang_XIX_Klima.RP_IF_ACT402_Versorgungsspannung_XIX_Grundumfang_XIX_Klima <-> outer port RP_IF_ACT402_Versorgungsspannung_XIX_Klima
    delegate Grundumfang_XIX_Klima.RP_IF_ACT403_Adresse_Aktuator_XIX_Grundumfang_XIX_Klima <-> outer port RP_IF_ACT403_Adresse_Aktuator_XIX_Klima
    delegate Grundumfang_XIX_Klima.RP_IF_ACT403_Blockierung_aufgetreten_XIX_Grundumfang_XIX_Klima <-> outer port RP_IF_ACT403_Blockierung_aufgetreten_XIX_Klima
    delegate Grundumfang_XIX_Klima.RP_IF_ACT403_Drehrichtung_XIX_Grundumfang_XIX_Klima <-> outer port RP_IF_ACT403_Drehrichtung_XIX_Klima
    delegate Grundumfang_XIX_Klima.RP_IF_ACT403_Elektr_Defekt_XIX_Grundumfang_XIX_Klima <-> outer port RP_IF_ACT403_Elektr_Defekt_XIX_Klima
    delegate Grundumfang_XIX_Klima.RP_IF_ACT403_Freigabe_Blockiererkennung_XIX_Grundumfang_XIX_Klima <-> outer port RP_IF_ACT403_Freigabe_Blockiererkennung_XIX_Klima
    delegate Grundumfang_XIX_Klima.RP_IF_ACT403_Geschwindigkeitsstatus_XIX_Grundumfang_XIX_Klima <-> outer port RP_IF_ACT403_Geschwindigkeitsstatus_XIX_Klima
    delegate Grundumfang_XIX_Klima.RP_IF_ACT403_Ist_Position_Aktuator_XIX_Grundumfang_XIX_Klima <-> outer port RP_IF_ACT403_Ist_Position_Aktuator_XIX_Klima
    delegate Grundumfang_XIX_Klima.RP_IF_ACT403_Notlauf_aufgetreten_XIX_Grundumfang_XIX_Klima <-> outer port RP_IF_ACT403_Notlauf_aufgetreten_XIX_Klima
    delegate Grundumfang_XIX_Klima.RP_IF_ACT403_Notlauffreigabe_XIX_Grundumfang_XIX_Klima <-> outer port RP_IF_ACT403_Notlauffreigabe_XIX_Klima
    delegate Grundumfang_XIX_Klima.RP_IF_ACT403_Notlaufposition_XIX_Grundumfang_XIX_Klima <-> outer port RP_IF_ACT403_Notlaufposition_XIX_Klima
    delegate Grundumfang_XIX_Klima.RP_IF_ACT403_Positionsvorgabe_Status_XIX_Grundumfang_XIX_Klima <-> outer port RP_IF_ACT403_Positionsvorgabe_Status_XIX_Klima
    delegate Grundumfang_XIX_Klima.RP_IF_ACT403_Reset_XIX_Grundumfang_XIX_Klima <-> outer port RP_IF_ACT403_Reset_XIX_Klima
    delegate Grundumfang_XIX_Klima.RP_IF_ACT403_ResponseError_XIX_Grundumfang_XIX_Klima <-> outer port RP_IF_ACT403_ResponseError_XIX_Klima
    delegate Grundumfang_XIX_Klima.RP_IF_ACT403_Selbsthaltemoment_XIX_Grundumfang_XIX_Klima <-> outer port RP_IF_ACT403_Selbsthaltemoment_XIX_Klima
    delegate Grundumfang_XIX_Klima.RP_IF_ACT403_Sonderfunktionen_XIX_Grundumfang_XIX_Klima <-> outer port RP_IF_ACT403_Sonderfunktionen_XIX_Klima
    delegate Grundumfang_XIX_Klima.RP_IF_ACT403_Spulenbestromung_XIX_Grundumfang_XIX_Klima <-> outer port RP_IF_ACT403_Spulenbestromung_XIX_Klima
    delegate Grundumfang_XIX_Klima.RP_IF_ACT403_Stopmodus_XIX_Grundumfang_XIX_Klima <-> outer port RP_IF_ACT403_Stopmodus_XIX_Klima
    delegate Grundumfang_XIX_Klima.RP_IF_ACT403_Uebertemperatur_XIX_Grundumfang_XIX_Klima <-> outer port RP_IF_ACT403_Uebertemperatur_XIX_Klima
    delegate Grundumfang_XIX_Klima.RP_IF_ACT403_Variante_XIX_Grundumfang_XIX_Klima <-> outer port RP_IF_ACT403_Variante_XIX_Klima
    delegate Grundumfang_XIX_Klima.RP_IF_ACT403_Verfahrrichtung_XIX_Grundumfang_XIX_Klima <-> outer port RP_IF_ACT403_Verfahrrichtung_XIX_Klima
    delegate Grundumfang_XIX_Klima.RP_IF_ACT403_Versorgungsspannung_XIX_Grundumfang_XIX_Klima <-> outer port RP_IF_ACT403_Versorgungsspannung_XIX_Klima
    delegate Grundumfang_XIX_Klima.RP_IF_ACT404_Adresse_Aktuator_XIX_Grundumfang_XIX_Klima <-> outer port RP_IF_ACT404_Adresse_Aktuator_XIX_Klima
    delegate Grundumfang_XIX_Klima.RP_IF_ACT404_Blockierung_aufgetreten_XIX_Grundumfang_XIX_Klima <-> outer port RP_IF_ACT404_Blockierung_aufgetreten_XIX_Klima
    delegate Grundumfang_XIX_Klima.RP_IF_ACT404_Drehrichtung_XIX_Grundumfang_XIX_Klima <-> outer port RP_IF_ACT404_Drehrichtung_XIX_Klima
    delegate Grundumfang_XIX_Klima.RP_IF_ACT404_Elektr_Defekt_XIX_Grundumfang_XIX_Klima <-> outer port RP_IF_ACT404_Elektr_Defekt_XIX_Klima
    delegate Grundumfang_XIX_Klima.RP_IF_ACT404_Freigabe_Blockiererkennung_XIX_Grundumfang_XIX_Klima <-> outer port RP_IF_ACT404_Freigabe_Blockiererkennung_XIX_Klima
    delegate Grundumfang_XIX_Klima.RP_IF_ACT404_Geschwindigkeitsstatus_XIX_Grundumfang_XIX_Klima <-> outer port RP_IF_ACT404_Geschwindigkeitsstatus_XIX_Klima
    delegate Grundumfang_XIX_Klima.RP_IF_ACT404_Ist_Position_Aktuator_XIX_Grundumfang_XIX_Klima <-> outer port RP_IF_ACT404_Ist_Position_Aktuator_XIX_Klima
    delegate Grundumfang_XIX_Klima.RP_IF_ACT404_Notlauf_aufgetreten_XIX_Grundumfang_XIX_Klima <-> outer port RP_IF_ACT404_Notlauf_aufgetreten_XIX_Klima
    delegate Grundumfang_XIX_Klima.RP_IF_ACT404_Notlauffreigabe_XIX_Grundumfang_XIX_Klima <-> outer port RP_IF_ACT404_Notlauffreigabe_XIX_Klima
    delegate Grundumfang_XIX_Klima.RP_IF_ACT404_Notlaufposition_XIX_Grundumfang_XIX_Klima <-> outer port RP_IF_ACT404_Notlaufposition_XIX_Klima
    delegate Grundumfang_XIX_Klima.RP_IF_ACT404_Positionsvorgabe_Status_XIX_Grundumfang_XIX_Klima <-> outer port RP_IF_ACT404_Positionsvorgabe_Status_XIX_Klima
    delegate Grundumfang_XIX_Klima.RP_IF_ACT404_Reset_XIX_Grundumfang_XIX_Klima <-> outer port RP_IF_ACT404_Reset_XIX_Klima
    delegate Grundumfang_XIX_Klima.RP_IF_ACT404_ResponseError_XIX_Grundumfang_XIX_Klima <-> outer port RP_IF_ACT404_ResponseError_XIX_Klima
    delegate Grundumfang_XIX_Klima.RP_IF_ACT404_Selbsthaltemoment_XIX_Grundumfang_XIX_Klima <-> outer port RP_IF_ACT404_Selbsthaltemoment_XIX_Klima
    delegate Grundumfang_XIX_Klima.RP_IF_ACT404_Sonderfunktionen_XIX_Grundumfang_XIX_Klima <-> outer port RP_IF_ACT404_Sonderfunktionen_XIX_Klima
    delegate Grundumfang_XIX_Klima.RP_IF_ACT404_Spulenbestromung_XIX_Grundumfang_XIX_Klima <-> outer port RP_IF_ACT404_Spulenbestromung_XIX_Klima
    delegate Grundumfang_XIX_Klima.RP_IF_ACT404_Stopmodus_XIX_Grundumfang_XIX_Klima <-> outer port RP_IF_ACT404_Stopmodus_XIX_Klima
    delegate Grundumfang_XIX_Klima.RP_IF_ACT404_Uebertemperatur_XIX_Grundumfang_XIX_Klima <-> outer port RP_IF_ACT404_Uebertemperatur_XIX_Klima
    delegate Grundumfang_XIX_Klima.RP_IF_ACT404_Variante_XIX_Grundumfang_XIX_Klima <-> outer port RP_IF_ACT404_Variante_XIX_Klima
    delegate Grundumfang_XIX_Klima.RP_IF_ACT404_Verfahrrichtung_XIX_Grundumfang_XIX_Klima <-> outer port RP_IF_ACT404_Verfahrrichtung_XIX_Klima
    delegate Grundumfang_XIX_Klima.RP_IF_ACT404_Versorgungsspannung_XIX_Grundumfang_XIX_Klima <-> outer port RP_IF_ACT404_Versorgungsspannung_XIX_Klima
    delegate Grundumfang_XIX_Klima.RP_IF_ACT405_Adresse_Aktuator_XIX_Grundumfang_XIX_Klima <-> outer port RP_IF_ACT405_Adresse_Aktuator_XIX_Klima
    delegate Grundumfang_XIX_Klima.RP_IF_ACT405_Blockierung_aufgetreten_XIX_Grundumfang_XIX_Klima <-> outer port RP_IF_ACT405_Blockierung_aufgetreten_XIX_Klima
    delegate Grundumfang_XIX_Klima.RP_IF_ACT405_Drehrichtung_XIX_Grundumfang_XIX_Klima <-> outer port RP_IF_ACT405_Drehrichtung_XIX_Klima
    delegate Grundumfang_XIX_Klima.RP_IF_ACT405_Elektr_Defekt_XIX_Grundumfang_XIX_Klima <-> outer port RP_IF_ACT405_Elektr_Defekt_XIX_Klima
    delegate Grundumfang_XIX_Klima.RP_IF_ACT405_Freigabe_Blockiererkennung_XIX_Grundumfang_XIX_Klima <-> outer port RP_IF_ACT405_Freigabe_Blockiererkennung_XIX_Klima
    delegate Grundumfang_XIX_Klima.RP_IF_ACT405_Geschwindigkeitsstatus_XIX_Grundumfang_XIX_Klima <-> outer port RP_IF_ACT405_Geschwindigkeitsstatus_XIX_Klima
    delegate Grundumfang_XIX_Klima.RP_IF_ACT405_Ist_Position_Aktuator_XIX_Grundumfang_XIX_Klima <-> outer port RP_IF_ACT405_Ist_Position_Aktuator_XIX_Klima
    delegate Grundumfang_XIX_Klima.RP_IF_ACT405_Notlauf_aufgetreten_XIX_Grundumfang_XIX_Klima <-> outer port RP_IF_ACT405_Notlauf_aufgetreten_XIX_Klima
    delegate Grundumfang_XIX_Klima.RP_IF_ACT405_Notlauffreigabe_XIX_Grundumfang_XIX_Klima <-> outer port RP_IF_ACT405_Notlauffreigabe_XIX_Klima
    delegate Grundumfang_XIX_Klima.RP_IF_ACT405_Notlaufposition_XIX_Grundumfang_XIX_Klima <-> outer port RP_IF_ACT405_Notlaufposition_XIX_Klima
    delegate Grundumfang_XIX_Klima.RP_IF_ACT405_Positionsvorgabe_Status_XIX_Grundumfang_XIX_Klima <-> outer port RP_IF_ACT405_Positionsvorgabe_Status_XIX_Klima
    delegate Grundumfang_XIX_Klima.RP_IF_ACT405_Reset_XIX_Grundumfang_XIX_Klima <-> outer port RP_IF_ACT405_Reset_XIX_Klima
    delegate Grundumfang_XIX_Klima.RP_IF_ACT405_ResponseError_XIX_Grundumfang_XIX_Klima <-> outer port RP_IF_ACT405_ResponseError_XIX_Klima
    delegate Grundumfang_XIX_Klima.RP_IF_ACT405_Selbsthaltemoment_XIX_Grundumfang_XIX_Klima <-> outer port RP_IF_ACT405_Selbsthaltemoment_XIX_Klima
    delegate Grundumfang_XIX_Klima.RP_IF_ACT405_Sonderfunktionen_XIX_Grundumfang_XIX_Klima <-> outer port RP_IF_ACT405_Sonderfunktionen_XIX_Klima
    delegate Grundumfang_XIX_Klima.RP_IF_ACT405_Spulenbestromung_XIX_Grundumfang_XIX_Klima <-> outer port RP_IF_ACT405_Spulenbestromung_XIX_Klima
    delegate Grundumfang_XIX_Klima.RP_IF_ACT405_Stopmodus_XIX_Grundumfang_XIX_Klima <-> outer port RP_IF_ACT405_Stopmodus_XIX_Klima
    delegate Grundumfang_XIX_Klima.RP_IF_ACT405_Uebertemperatur_XIX_Grundumfang_XIX_Klima <-> outer port RP_IF_ACT405_Uebertemperatur_XIX_Klima
    delegate Grundumfang_XIX_Klima.RP_IF_ACT405_Variante_XIX_Grundumfang_XIX_Klima <-> outer port RP_IF_ACT405_Variante_XIX_Klima
    delegate Grundumfang_XIX_Klima.RP_IF_ACT405_Verfahrrichtung_XIX_Grundumfang_XIX_Klima <-> outer port RP_IF_ACT405_Verfahrrichtung_XIX_Klima
    delegate Grundumfang_XIX_Klima.RP_IF_ACT405_Versorgungsspannung_XIX_Grundumfang_XIX_Klima <-> outer port RP_IF_ACT405_Versorgungsspannung_XIX_Klima
    delegate Grundumfang_XIX_Klima.RP_IF_ACT406_Adresse_Aktuator_XIX_Grundumfang_XIX_Klima <-> outer port RP_IF_ACT406_Adresse_Aktuator_XIX_Klima
    delegate Grundumfang_XIX_Klima.RP_IF_ACT406_Blockierung_aufgetreten_XIX_Grundumfang_XIX_Klima <-> outer port RP_IF_ACT406_Blockierung_aufgetreten_XIX_Klima
    delegate Grundumfang_XIX_Klima.RP_IF_ACT406_Drehrichtung_XIX_Grundumfang_XIX_Klima <-> outer port RP_IF_ACT406_Drehrichtung_XIX_Klima
    delegate Grundumfang_XIX_Klima.RP_IF_ACT406_Elektr_Defekt_XIX_Grundumfang_XIX_Klima <-> outer port RP_IF_ACT406_Elektr_Defekt_XIX_Klima
    delegate Grundumfang_XIX_Klima.RP_IF_ACT406_Freigabe_Blockiererkennung_XIX_Grundumfang_XIX_Klima <-> outer port RP_IF_ACT406_Freigabe_Blockiererkennung_XIX_Klima
    delegate Grundumfang_XIX_Klima.RP_IF_ACT406_Geschwindigkeitsstatus_XIX_Grundumfang_XIX_Klima <-> outer port RP_IF_ACT406_Geschwindigkeitsstatus_XIX_Klima
    delegate Grundumfang_XIX_Klima.RP_IF_ACT406_Ist_Position_Aktuator_XIX_Grundumfang_XIX_Klima <-> outer port RP_IF_ACT406_Ist_Position_Aktuator_XIX_Klima
    delegate Grundumfang_XIX_Klima.RP_IF_ACT406_Notlauf_aufgetreten_XIX_Grundumfang_XIX_Klima <-> outer port RP_IF_ACT406_Notlauf_aufgetreten_XIX_Klima
    delegate Grundumfang_XIX_Klima.RP_IF_ACT406_Notlauffreigabe_XIX_Grundumfang_XIX_Klima <-> outer port RP_IF_ACT406_Notlauffreigabe_XIX_Klima
    delegate Grundumfang_XIX_Klima.RP_IF_ACT406_Notlaufposition_XIX_Grundumfang_XIX_Klima <-> outer port RP_IF_ACT406_Notlaufposition_XIX_Klima
    delegate Grundumfang_XIX_Klima.RP_IF_ACT406_Positionsvorgabe_Status_XIX_Grundumfang_XIX_Klima <-> outer port RP_IF_ACT406_Positionsvorgabe_Status_XIX_Klima
    delegate Grundumfang_XIX_Klima.RP_IF_ACT406_Reset_XIX_Grundumfang_XIX_Klima <-> outer port RP_IF_ACT406_Reset_XIX_Klima
    delegate Grundumfang_XIX_Klima.RP_IF_ACT406_ResponseError_XIX_Grundumfang_XIX_Klima <-> outer port RP_IF_ACT406_ResponseError_XIX_Klima
    delegate Grundumfang_XIX_Klima.RP_IF_ACT406_Selbsthaltemoment_XIX_Grundumfang_XIX_Klima <-> outer port RP_IF_ACT406_Selbsthaltemoment_XIX_Klima
    delegate Grundumfang_XIX_Klima.RP_IF_ACT406_Sonderfunktionen_XIX_Grundumfang_XIX_Klima <-> outer port RP_IF_ACT406_Sonderfunktionen_XIX_Klima
    delegate Grundumfang_XIX_Klima.RP_IF_ACT406_Spulenbestromung_XIX_Grundumfang_XIX_Klima <-> outer port RP_IF_ACT406_Spulenbestromung_XIX_Klima
    delegate Grundumfang_XIX_Klima.RP_IF_ACT406_Stopmodus_XIX_Grundumfang_XIX_Klima <-> outer port RP_IF_ACT406_Stopmodus_XIX_Klima
    delegate Grundumfang_XIX_Klima.RP_IF_ACT406_Uebertemperatur_XIX_Grundumfang_XIX_Klima <-> outer port RP_IF_ACT406_Uebertemperatur_XIX_Klima
    delegate Grundumfang_XIX_Klima.RP_IF_ACT406_Variante_XIX_Grundumfang_XIX_Klima <-> outer port RP_IF_ACT406_Variante_XIX_Klima
    delegate Grundumfang_XIX_Klima.RP_IF_ACT406_Verfahrrichtung_XIX_Grundumfang_XIX_Klima <-> outer port RP_IF_ACT406_Verfahrrichtung_XIX_Klima
    delegate Grundumfang_XIX_Klima.RP_IF_ACT406_Versorgungsspannung_XIX_Grundumfang_XIX_Klima <-> outer port RP_IF_ACT406_Versorgungsspannung_XIX_Klima
    delegate Grundumfang_XIX_Klima.RP_IF_ACT407_Adresse_Aktuator_XIX_Grundumfang_XIX_Klima <-> outer port RP_IF_ACT407_Adresse_Aktuator_XIX_Klima
    delegate Grundumfang_XIX_Klima.RP_IF_ACT407_Blockierung_aufgetreten_XIX_Grundumfang_XIX_Klima <-> outer port RP_IF_ACT407_Blockierung_aufgetreten_XIX_Klima
    delegate Grundumfang_XIX_Klima.RP_IF_ACT407_Drehrichtung_XIX_Grundumfang_XIX_Klima <-> outer port RP_IF_ACT407_Drehrichtung_XIX_Klima
    delegate Grundumfang_XIX_Klima.RP_IF_ACT407_Elektr_Defekt_XIX_Grundumfang_XIX_Klima <-> outer port RP_IF_ACT407_Elektr_Defekt_XIX_Klima
    delegate Grundumfang_XIX_Klima.RP_IF_ACT407_Freigabe_Blockiererkennung_XIX_Grundumfang_XIX_Klima <-> outer port RP_IF_ACT407_Freigabe_Blockiererkennung_XIX_Klima
    delegate Grundumfang_XIX_Klima.RP_IF_ACT407_Geschwindigkeitsstatus_XIX_Grundumfang_XIX_Klima <-> outer port RP_IF_ACT407_Geschwindigkeitsstatus_XIX_Klima
    delegate Grundumfang_XIX_Klima.RP_IF_ACT407_Ist_Position_Aktuator_XIX_Grundumfang_XIX_Klima <-> outer port RP_IF_ACT407_Ist_Position_Aktuator_XIX_Klima
    delegate Grundumfang_XIX_Klima.RP_IF_ACT407_Notlauf_aufgetreten_XIX_Grundumfang_XIX_Klima <-> outer port RP_IF_ACT407_Notlauf_aufgetreten_XIX_Klima
    delegate Grundumfang_XIX_Klima.RP_IF_ACT407_Notlauffreigabe_XIX_Grundumfang_XIX_Klima <-> outer port RP_IF_ACT407_Notlauffreigabe_XIX_Klima
    delegate Grundumfang_XIX_Klima.RP_IF_ACT407_Notlaufposition_XIX_Grundumfang_XIX_Klima <-> outer port RP_IF_ACT407_Notlaufposition_XIX_Klima
    delegate Grundumfang_XIX_Klima.RP_IF_ACT407_Positionsvorgabe_Status_XIX_Grundumfang_XIX_Klima <-> outer port RP_IF_ACT407_Positionsvorgabe_Status_XIX_Klima
    delegate Grundumfang_XIX_Klima.RP_IF_ACT407_Reset_XIX_Grundumfang_XIX_Klima <-> outer port RP_IF_ACT407_Reset_XIX_Klima
    delegate Grundumfang_XIX_Klima.RP_IF_ACT407_ResponseError_XIX_Grundumfang_XIX_Klima <-> outer port RP_IF_ACT407_ResponseError_XIX_Klima
    delegate Grundumfang_XIX_Klima.RP_IF_ACT407_Selbsthaltemoment_XIX_Grundumfang_XIX_Klima <-> outer port RP_IF_ACT407_Selbsthaltemoment_XIX_Klima
    delegate Grundumfang_XIX_Klima.RP_IF_ACT407_Sonderfunktionen_XIX_Grundumfang_XIX_Klima <-> outer port RP_IF_ACT407_Sonderfunktionen_XIX_Klima
    delegate Grundumfang_XIX_Klima.RP_IF_ACT407_Spulenbestromung_XIX_Grundumfang_XIX_Klima <-> outer port RP_IF_ACT407_Spulenbestromung_XIX_Klima
    delegate Grundumfang_XIX_Klima.RP_IF_ACT407_Stopmodus_XIX_Grundumfang_XIX_Klima <-> outer port RP_IF_ACT407_Stopmodus_XIX_Klima
    delegate Grundumfang_XIX_Klima.RP_IF_ACT407_Uebertemperatur_XIX_Grundumfang_XIX_Klima <-> outer port RP_IF_ACT407_Uebertemperatur_XIX_Klima
    delegate Grundumfang_XIX_Klima.RP_IF_ACT407_Variante_XIX_Grundumfang_XIX_Klima <-> outer port RP_IF_ACT407_Variante_XIX_Klima
    delegate Grundumfang_XIX_Klima.RP_IF_ACT407_Verfahrrichtung_XIX_Grundumfang_XIX_Klima <-> outer port RP_IF_ACT407_Verfahrrichtung_XIX_Klima
    delegate Grundumfang_XIX_Klima.RP_IF_ACT407_Versorgungsspannung_XIX_Grundumfang_XIX_Klima <-> outer port RP_IF_ACT407_Versorgungsspannung_XIX_Klima
    delegate Grundumfang_XIX_Klima.RP_IF_ACT408_Adresse_Aktuator_XIX_Grundumfang_XIX_Klima <-> outer port RP_IF_ACT408_Adresse_Aktuator_XIX_Klima
    delegate Grundumfang_XIX_Klima.RP_IF_ACT408_Blockierung_aufgetreten_XIX_Grundumfang_XIX_Klima <-> outer port RP_IF_ACT408_Blockierung_aufgetreten_XIX_Klima
    delegate Grundumfang_XIX_Klima.RP_IF_ACT408_Drehrichtung_XIX_Grundumfang_XIX_Klima <-> outer port RP_IF_ACT408_Drehrichtung_XIX_Klima
    delegate Grundumfang_XIX_Klima.RP_IF_ACT408_Elektr_Defekt_XIX_Grundumfang_XIX_Klima <-> outer port RP_IF_ACT408_Elektr_Defekt_XIX_Klima
    delegate Grundumfang_XIX_Klima.RP_IF_ACT408_Freigabe_Blockiererkennung_XIX_Grundumfang_XIX_Klima <-> outer port RP_IF_ACT408_Freigabe_Blockiererkennung_XIX_Klima
    delegate Grundumfang_XIX_Klima.RP_IF_ACT408_Geschwindigkeitsstatus_XIX_Grundumfang_XIX_Klima <-> outer port RP_IF_ACT408_Geschwindigkeitsstatus_XIX_Klima
    delegate Grundumfang_XIX_Klima.RP_IF_ACT408_Ist_Position_Aktuator_XIX_Grundumfang_XIX_Klima <-> outer port RP_IF_ACT408_Ist_Position_Aktuator_XIX_Klima
    delegate Grundumfang_XIX_Klima.RP_IF_ACT408_Notlauf_aufgetreten_XIX_Grundumfang_XIX_Klima <-> outer port RP_IF_ACT408_Notlauf_aufgetreten_XIX_Klima
    delegate Grundumfang_XIX_Klima.RP_IF_ACT408_Notlauffreigabe_XIX_Grundumfang_XIX_Klima <-> outer port RP_IF_ACT408_Notlauffreigabe_XIX_Klima
    delegate Grundumfang_XIX_Klima.RP_IF_ACT408_Notlaufposition_XIX_Grundumfang_XIX_Klima <-> outer port RP_IF_ACT408_Notlaufposition_XIX_Klima
    delegate Grundumfang_XIX_Klima.RP_IF_ACT408_Positionsvorgabe_Status_XIX_Grundumfang_XIX_Klima <-> outer port RP_IF_ACT408_Positionsvorgabe_Status_XIX_Klima
    delegate Grundumfang_XIX_Klima.RP_IF_ACT408_Reset_XIX_Grundumfang_XIX_Klima <-> outer port RP_IF_ACT408_Reset_XIX_Klima
    delegate Grundumfang_XIX_Klima.RP_IF_ACT408_ResponseError_XIX_Grundumfang_XIX_Klima <-> outer port RP_IF_ACT408_ResponseError_XIX_Klima
    delegate Grundumfang_XIX_Klima.RP_IF_ACT408_Selbsthaltemoment_XIX_Grundumfang_XIX_Klima <-> outer port RP_IF_ACT408_Selbsthaltemoment_XIX_Klima
    delegate Grundumfang_XIX_Klima.RP_IF_ACT408_Sonderfunktionen_XIX_Grundumfang_XIX_Klima <-> outer port RP_IF_ACT408_Sonderfunktionen_XIX_Klima
    delegate Grundumfang_XIX_Klima.RP_IF_ACT408_Spulenbestromung_XIX_Grundumfang_XIX_Klima <-> outer port RP_IF_ACT408_Spulenbestromung_XIX_Klima
    delegate Grundumfang_XIX_Klima.RP_IF_ACT408_Stopmodus_XIX_Grundumfang_XIX_Klima <-> outer port RP_IF_ACT408_Stopmodus_XIX_Klima
    delegate Grundumfang_XIX_Klima.RP_IF_ACT408_Uebertemperatur_XIX_Grundumfang_XIX_Klima <-> outer port RP_IF_ACT408_Uebertemperatur_XIX_Klima
    delegate Grundumfang_XIX_Klima.RP_IF_ACT408_Variante_XIX_Grundumfang_XIX_Klima <-> outer port RP_IF_ACT408_Variante_XIX_Klima
    delegate Grundumfang_XIX_Klima.RP_IF_ACT408_Verfahrrichtung_XIX_Grundumfang_XIX_Klima <-> outer port RP_IF_ACT408_Verfahrrichtung_XIX_Klima
    delegate Grundumfang_XIX_Klima.RP_IF_ACT408_Versorgungsspannung_XIX_Grundumfang_XIX_Klima <-> outer port RP_IF_ACT408_Versorgungsspannung_XIX_Klima
    delegate Grundumfang_XIX_Klima.RP_IF_ACT409_Adresse_Aktuator_XIX_Grundumfang_XIX_Klima <-> outer port RP_IF_ACT409_Adresse_Aktuator_XIX_Klima
    delegate Grundumfang_XIX_Klima.RP_IF_ACT409_Blockierung_aufgetreten_XIX_Grundumfang_XIX_Klima <-> outer port RP_IF_ACT409_Blockierung_aufgetreten_XIX_Klima
    delegate Grundumfang_XIX_Klima.RP_IF_ACT409_Drehrichtung_XIX_Grundumfang_XIX_Klima <-> outer port RP_IF_ACT409_Drehrichtung_XIX_Klima
    delegate Grundumfang_XIX_Klima.RP_IF_ACT409_Elektr_Defekt_XIX_Grundumfang_XIX_Klima <-> outer port RP_IF_ACT409_Elektr_Defekt_XIX_Klima
    delegate Grundumfang_XIX_Klima.RP_IF_ACT409_Freigabe_Blockiererkennung_XIX_Grundumfang_XIX_Klima <-> outer port RP_IF_ACT409_Freigabe_Blockiererkennung_XIX_Klima
    delegate Grundumfang_XIX_Klima.RP_IF_ACT409_Geschwindigkeitsstatus_XIX_Grundumfang_XIX_Klima <-> outer port RP_IF_ACT409_Geschwindigkeitsstatus_XIX_Klima
    delegate Grundumfang_XIX_Klima.RP_IF_ACT409_Ist_Position_Aktuator_XIX_Grundumfang_XIX_Klima <-> outer port RP_IF_ACT409_Ist_Position_Aktuator_XIX_Klima
    delegate Grundumfang_XIX_Klima.RP_IF_ACT409_Notlauf_aufgetreten_XIX_Grundumfang_XIX_Klima <-> outer port RP_IF_ACT409_Notlauf_aufgetreten_XIX_Klima
    delegate Grundumfang_XIX_Klima.RP_IF_ACT409_Notlauffreigabe_XIX_Grundumfang_XIX_Klima <-> outer port RP_IF_ACT409_Notlauffreigabe_XIX_Klima
    delegate Grundumfang_XIX_Klima.RP_IF_ACT409_Notlaufposition_XIX_Grundumfang_XIX_Klima <-> outer port RP_IF_ACT409_Notlaufposition_XIX_Klima
    delegate Grundumfang_XIX_Klima.RP_IF_ACT409_Positionsvorgabe_Status_XIX_Grundumfang_XIX_Klima <-> outer port RP_IF_ACT409_Positionsvorgabe_Status_XIX_Klima
    delegate Grundumfang_XIX_Klima.RP_IF_ACT409_Reset_XIX_Grundumfang_XIX_Klima <-> outer port RP_IF_ACT409_Reset_XIX_Klima
    delegate Grundumfang_XIX_Klima.RP_IF_ACT409_ResponseError_XIX_Grundumfang_XIX_Klima <-> outer port RP_IF_ACT409_ResponseError_XIX_Klima
    delegate Grundumfang_XIX_Klima.RP_IF_ACT409_Selbsthaltemoment_XIX_Grundumfang_XIX_Klima <-> outer port RP_IF_ACT409_Selbsthaltemoment_XIX_Klima
    delegate Grundumfang_XIX_Klima.RP_IF_ACT409_Sonderfunktionen_XIX_Grundumfang_XIX_Klima <-> outer port RP_IF_ACT409_Sonderfunktionen_XIX_Klima
    delegate Grundumfang_XIX_Klima.RP_IF_ACT409_Spulenbestromung_XIX_Grundumfang_XIX_Klima <-> outer port RP_IF_ACT409_Spulenbestromung_XIX_Klima
    delegate Grundumfang_XIX_Klima.RP_IF_ACT409_Stopmodus_XIX_Grundumfang_XIX_Klima <-> outer port RP_IF_ACT409_Stopmodus_XIX_Klima
    delegate Grundumfang_XIX_Klima.RP_IF_ACT409_Uebertemperatur_XIX_Grundumfang_XIX_Klima <-> outer port RP_IF_ACT409_Uebertemperatur_XIX_Klima
    delegate Grundumfang_XIX_Klima.RP_IF_ACT409_Variante_XIX_Grundumfang_XIX_Klima <-> outer port RP_IF_ACT409_Variante_XIX_Klima
    delegate Grundumfang_XIX_Klima.RP_IF_ACT409_Verfahrrichtung_XIX_Grundumfang_XIX_Klima <-> outer port RP_IF_ACT409_Verfahrrichtung_XIX_Klima
    delegate Grundumfang_XIX_Klima.RP_IF_ACT409_Versorgungsspannung_XIX_Grundumfang_XIX_Klima <-> outer port RP_IF_ACT409_Versorgungsspannung_XIX_Klima
    delegate Grundumfang_XIX_Klima.RP_IF_ACT410_Adresse_Aktuator_XIX_Grundumfang_XIX_Klima <-> outer port RP_IF_ACT410_Adresse_Aktuator_XIX_Klima
    delegate Grundumfang_XIX_Klima.RP_IF_ACT410_Blockierung_aufgetreten_XIX_Grundumfang_XIX_Klima <-> outer port RP_IF_ACT410_Blockierung_aufgetreten_XIX_Klima
    delegate Grundumfang_XIX_Klima.RP_IF_ACT410_Drehrichtung_XIX_Grundumfang_XIX_Klima <-> outer port RP_IF_ACT410_Drehrichtung_XIX_Klima
    delegate Grundumfang_XIX_Klima.RP_IF_ACT410_Elektr_Defekt_XIX_Grundumfang_XIX_Klima <-> outer port RP_IF_ACT410_Elektr_Defekt_XIX_Klima
    delegate Grundumfang_XIX_Klima.RP_IF_ACT410_Freigabe_Blockiererkennung_XIX_Grundumfang_XIX_Klima <-> outer port RP_IF_ACT410_Freigabe_Blockiererkennung_XIX_Klima
    delegate Grundumfang_XIX_Klima.RP_IF_ACT410_Geschwindigkeitsstatus_XIX_Grundumfang_XIX_Klima <-> outer port RP_IF_ACT410_Geschwindigkeitsstatus_XIX_Klima
    delegate Grundumfang_XIX_Klima.RP_IF_ACT410_Ist_Position_Aktuator_XIX_Grundumfang_XIX_Klima <-> outer port RP_IF_ACT410_Ist_Position_Aktuator_XIX_Klima
    delegate Grundumfang_XIX_Klima.RP_IF_ACT410_Notlauf_aufgetreten_XIX_Grundumfang_XIX_Klima <-> outer port RP_IF_ACT410_Notlauf_aufgetreten_XIX_Klima
    delegate Grundumfang_XIX_Klima.RP_IF_ACT410_Notlauffreigabe_XIX_Grundumfang_XIX_Klima <-> outer port RP_IF_ACT410_Notlauffreigabe_XIX_Klima
    delegate Grundumfang_XIX_Klima.RP_IF_ACT410_Notlaufposition_XIX_Grundumfang_XIX_Klima <-> outer port RP_IF_ACT410_Notlaufposition_XIX_Klima
    delegate Grundumfang_XIX_Klima.RP_IF_ACT410_Positionsvorgabe_Status_XIX_Grundumfang_XIX_Klima <-> outer port RP_IF_ACT410_Positionsvorgabe_Status_XIX_Klima
    delegate Grundumfang_XIX_Klima.RP_IF_ACT410_Reset_XIX_Grundumfang_XIX_Klima <-> outer port RP_IF_ACT410_Reset_XIX_Klima
    delegate Grundumfang_XIX_Klima.RP_IF_ACT410_ResponseError_XIX_Grundumfang_XIX_Klima <-> outer port RP_IF_ACT410_ResponseError_XIX_Klima
    delegate Grundumfang_XIX_Klima.RP_IF_ACT410_Selbsthaltemoment_XIX_Grundumfang_XIX_Klima <-> outer port RP_IF_ACT410_Selbsthaltemoment_XIX_Klima
    delegate Grundumfang_XIX_Klima.RP_IF_ACT410_Sonderfunktionen_XIX_Grundumfang_XIX_Klima <-> outer port RP_IF_ACT410_Sonderfunktionen_XIX_Klima
    delegate Grundumfang_XIX_Klima.RP_IF_ACT410_Spulenbestromung_XIX_Grundumfang_XIX_Klima <-> outer port RP_IF_ACT410_Spulenbestromung_XIX_Klima
    delegate Grundumfang_XIX_Klima.RP_IF_ACT410_Stopmodus_XIX_Grundumfang_XIX_Klima <-> outer port RP_IF_ACT410_Stopmodus_XIX_Klima
    delegate Grundumfang_XIX_Klima.RP_IF_ACT410_Uebertemperatur_XIX_Grundumfang_XIX_Klima <-> outer port RP_IF_ACT410_Uebertemperatur_XIX_Klima
    delegate Grundumfang_XIX_Klima.RP_IF_ACT410_Variante_XIX_Grundumfang_XIX_Klima <-> outer port RP_IF_ACT410_Variante_XIX_Klima
    delegate Grundumfang_XIX_Klima.RP_IF_ACT410_Verfahrrichtung_XIX_Grundumfang_XIX_Klima <-> outer port RP_IF_ACT410_Verfahrrichtung_XIX_Klima
    delegate Grundumfang_XIX_Klima.RP_IF_ACT410_Versorgungsspannung_XIX_Grundumfang_XIX_Klima <-> outer port RP_IF_ACT410_Versorgungsspannung_XIX_Klima
    delegate Grundumfang_XIX_Klima.RP_IF_ACT411_Adresse_Aktuator_XIX_Grundumfang_XIX_Klima <-> outer port RP_IF_ACT411_Adresse_Aktuator_XIX_Klima
    delegate Grundumfang_XIX_Klima.RP_IF_ACT411_Blockierung_aufgetreten_XIX_Grundumfang_XIX_Klima <-> outer port RP_IF_ACT411_Blockierung_aufgetreten_XIX_Klima
    delegate Grundumfang_XIX_Klima.RP_IF_ACT411_Drehrichtung_XIX_Grundumfang_XIX_Klima <-> outer port RP_IF_ACT411_Drehrichtung_XIX_Klima
    delegate Grundumfang_XIX_Klima.RP_IF_ACT411_Elektr_Defekt_XIX_Grundumfang_XIX_Klima <-> outer port RP_IF_ACT411_Elektr_Defekt_XIX_Klima
    delegate Grundumfang_XIX_Klima.RP_IF_ACT411_Freigabe_Blockiererkennung_XIX_Grundumfang_XIX_Klima <-> outer port RP_IF_ACT411_Freigabe_Blockiererkennung_XIX_Klima
    delegate Grundumfang_XIX_Klima.RP_IF_ACT411_Geschwindigkeitsstatus_XIX_Grundumfang_XIX_Klima <-> outer port RP_IF_ACT411_Geschwindigkeitsstatus_XIX_Klima
    delegate Grundumfang_XIX_Klima.RP_IF_ACT411_Ist_Position_Aktuator_XIX_Grundumfang_XIX_Klima <-> outer port RP_IF_ACT411_Ist_Position_Aktuator_XIX_Klima
    delegate Grundumfang_XIX_Klima.RP_IF_ACT411_Notlauf_aufgetreten_XIX_Grundumfang_XIX_Klima <-> outer port RP_IF_ACT411_Notlauf_aufgetreten_XIX_Klima
    delegate Grundumfang_XIX_Klima.RP_IF_ACT411_Notlauffreigabe_XIX_Grundumfang_XIX_Klima <-> outer port RP_IF_ACT411_Notlauffreigabe_XIX_Klima
    delegate Grundumfang_XIX_Klima.RP_IF_ACT411_Notlaufposition_XIX_Grundumfang_XIX_Klima <-> outer port RP_IF_ACT411_Notlaufposition_XIX_Klima
    delegate Grundumfang_XIX_Klima.RP_IF_ACT411_Positionsvorgabe_Status_XIX_Grundumfang_XIX_Klima <-> outer port RP_IF_ACT411_Positionsvorgabe_Status_XIX_Klima
    delegate Grundumfang_XIX_Klima.RP_IF_ACT411_Reset_XIX_Grundumfang_XIX_Klima <-> outer port RP_IF_ACT411_Reset_XIX_Klima
    delegate Grundumfang_XIX_Klima.RP_IF_ACT411_ResponseError_XIX_Grundumfang_XIX_Klima <-> outer port RP_IF_ACT411_ResponseError_XIX_Klima
    delegate Grundumfang_XIX_Klima.RP_IF_ACT411_Selbsthaltemoment_XIX_Grundumfang_XIX_Klima <-> outer port RP_IF_ACT411_Selbsthaltemoment_XIX_Klima
    delegate Grundumfang_XIX_Klima.RP_IF_ACT411_Sonderfunktionen_XIX_Grundumfang_XIX_Klima <-> outer port RP_IF_ACT411_Sonderfunktionen_XIX_Klima
    delegate Grundumfang_XIX_Klima.RP_IF_ACT411_Spulenbestromung_XIX_Grundumfang_XIX_Klima <-> outer port RP_IF_ACT411_Spulenbestromung_XIX_Klima
    delegate Grundumfang_XIX_Klima.RP_IF_ACT411_Stopmodus_XIX_Grundumfang_XIX_Klima <-> outer port RP_IF_ACT411_Stopmodus_XIX_Klima
    delegate Grundumfang_XIX_Klima.RP_IF_ACT411_Uebertemperatur_XIX_Grundumfang_XIX_Klima <-> outer port RP_IF_ACT411_Uebertemperatur_XIX_Klima
    delegate Grundumfang_XIX_Klima.RP_IF_ACT411_Variante_XIX_Grundumfang_XIX_Klima <-> outer port RP_IF_ACT411_Variante_XIX_Klima
    delegate Grundumfang_XIX_Klima.RP_IF_ACT411_Verfahrrichtung_XIX_Grundumfang_XIX_Klima <-> outer port RP_IF_ACT411_Verfahrrichtung_XIX_Klima
    delegate Grundumfang_XIX_Klima.RP_IF_ACT411_Versorgungsspannung_XIX_Grundumfang_XIX_Klima <-> outer port RP_IF_ACT411_Versorgungsspannung_XIX_Klima
    delegate Grundumfang_XIX_Klima.RP_IF_ACT412_Adresse_Aktuator_XIX_Grundumfang_XIX_Klima <-> outer port RP_IF_ACT412_Adresse_Aktuator_XIX_Klima
    delegate Grundumfang_XIX_Klima.RP_IF_ACT412_Blockierung_aufgetreten_XIX_Grundumfang_XIX_Klima <-> outer port RP_IF_ACT412_Blockierung_aufgetreten_XIX_Klima
    delegate Grundumfang_XIX_Klima.RP_IF_ACT412_Drehrichtung_XIX_Grundumfang_XIX_Klima <-> outer port RP_IF_ACT412_Drehrichtung_XIX_Klima
    delegate Grundumfang_XIX_Klima.RP_IF_ACT412_Elektr_Defekt_XIX_Grundumfang_XIX_Klima <-> outer port RP_IF_ACT412_Elektr_Defekt_XIX_Klima
    delegate Grundumfang_XIX_Klima.RP_IF_ACT412_Freigabe_Blockiererkennung_XIX_Grundumfang_XIX_Klima <-> outer port RP_IF_ACT412_Freigabe_Blockiererkennung_XIX_Klima
    delegate Grundumfang_XIX_Klima.RP_IF_ACT412_Geschwindigkeitsstatus_XIX_Grundumfang_XIX_Klima <-> outer port RP_IF_ACT412_Geschwindigkeitsstatus_XIX_Klima
    delegate Grundumfang_XIX_Klima.RP_IF_ACT412_Ist_Position_Aktuator_XIX_Grundumfang_XIX_Klima <-> outer port RP_IF_ACT412_Ist_Position_Aktuator_XIX_Klima
    delegate Grundumfang_XIX_Klima.RP_IF_ACT412_Notlauf_aufgetreten_XIX_Grundumfang_XIX_Klima <-> outer port RP_IF_ACT412_Notlauf_aufgetreten_XIX_Klima
    delegate Grundumfang_XIX_Klima.RP_IF_ACT412_Notlauffreigabe_XIX_Grundumfang_XIX_Klima <-> outer port RP_IF_ACT412_Notlauffreigabe_XIX_Klima
    delegate Grundumfang_XIX_Klima.RP_IF_ACT412_Notlaufposition_XIX_Grundumfang_XIX_Klima <-> outer port RP_IF_ACT412_Notlaufposition_XIX_Klima
    delegate Grundumfang_XIX_Klima.RP_IF_ACT412_Positionsvorgabe_Status_XIX_Grundumfang_XIX_Klima <-> outer port RP_IF_ACT412_Positionsvorgabe_Status_XIX_Klima
    delegate Grundumfang_XIX_Klima.RP_IF_ACT412_Reset_XIX_Grundumfang_XIX_Klima <-> outer port RP_IF_ACT412_Reset_XIX_Klima
    delegate Grundumfang_XIX_Klima.RP_IF_ACT412_ResponseError_XIX_Grundumfang_XIX_Klima <-> outer port RP_IF_ACT412_ResponseError_XIX_Klima
    delegate Grundumfang_XIX_Klima.RP_IF_ACT412_Selbsthaltemoment_XIX_Grundumfang_XIX_Klima <-> outer port RP_IF_ACT412_Selbsthaltemoment_XIX_Klima
    delegate Grundumfang_XIX_Klima.RP_IF_ACT412_Sonderfunktionen_XIX_Grundumfang_XIX_Klima <-> outer port RP_IF_ACT412_Sonderfunktionen_XIX_Klima
    delegate Grundumfang_XIX_Klima.RP_IF_ACT412_Spulenbestromung_XIX_Grundumfang_XIX_Klima <-> outer port RP_IF_ACT412_Spulenbestromung_XIX_Klima
    delegate Grundumfang_XIX_Klima.RP_IF_ACT412_Stopmodus_XIX_Grundumfang_XIX_Klima <-> outer port RP_IF_ACT412_Stopmodus_XIX_Klima
    delegate Grundumfang_XIX_Klima.RP_IF_ACT412_Uebertemperatur_XIX_Grundumfang_XIX_Klima <-> outer port RP_IF_ACT412_Uebertemperatur_XIX_Klima
    delegate Grundumfang_XIX_Klima.RP_IF_ACT412_Variante_XIX_Grundumfang_XIX_Klima <-> outer port RP_IF_ACT412_Variante_XIX_Klima
    delegate Grundumfang_XIX_Klima.RP_IF_ACT412_Verfahrrichtung_XIX_Grundumfang_XIX_Klima <-> outer port RP_IF_ACT412_Verfahrrichtung_XIX_Klima
    delegate Grundumfang_XIX_Klima.RP_IF_ACT412_Versorgungsspannung_XIX_Grundumfang_XIX_Klima <-> outer port RP_IF_ACT412_Versorgungsspannung_XIX_Klima
    delegate Grundumfang_XIX_Klima.RP_IF_AQS_COBereich_XIX_Grundumfang_XIX_Klima <-> outer port RP_IF_AQS_COBereich_XIX_Klima
    delegate Grundumfang_XIX_Klima.RP_IF_AQS_COStatus_XIX_Grundumfang_XIX_Klima <-> outer port RP_IF_AQS_COStatus_XIX_Klima
    delegate Grundumfang_XIX_Klima.RP_IF_AQS_COWert_XIX_Grundumfang_XIX_Klima <-> outer port RP_IF_AQS_COWert_XIX_Klima
    delegate Grundumfang_XIX_Klima.RP_IF_AQS_HW_XIX_Grundumfang_XIX_Klima <-> outer port RP_IF_AQS_HW_XIX_Klima
    delegate Grundumfang_XIX_Klima.RP_IF_AQS_Luftguete_XIX_Grundumfang_XIX_Klima <-> outer port RP_IF_AQS_Luftguete_XIX_Klima
    delegate Grundumfang_XIX_Klima.RP_IF_AQS_NoxBereich_XIX_Grundumfang_XIX_Klima <-> outer port RP_IF_AQS_NoxBereich_XIX_Klima
    delegate Grundumfang_XIX_Klima.RP_IF_AQS_NoxStatus_XIX_Grundumfang_XIX_Klima <-> outer port RP_IF_AQS_NoxStatus_XIX_Klima
    delegate Grundumfang_XIX_Klima.RP_IF_AQS_NoxWert_XIX_Grundumfang_XIX_Klima <-> outer port RP_IF_AQS_NoxWert_XIX_Klima
    delegate Grundumfang_XIX_Klima.RP_IF_AQS_Parameter_XIX_Grundumfang_XIX_Klima <-> outer port RP_IF_AQS_Parameter_XIX_Klima
    delegate Grundumfang_XIX_Klima.RP_IF_AQS_ResponseError_XIX_Grundumfang_XIX_Klima <-> outer port RP_IF_AQS_ResponseError_XIX_Klima
    delegate Grundumfang_XIX_Klima.RP_IF_AQS_Sensorheizung_Status_XIX_Grundumfang_XIX_Klima <-> outer port RP_IF_AQS_Sensorheizung_Status_XIX_Klima
    delegate Grundumfang_XIX_Klima.RP_IF_AQS_SW_XIX_Grundumfang_XIX_Klima <-> outer port RP_IF_AQS_SW_XIX_Klima
    delegate Grundumfang_XIX_Klima.RP_IF_AQS_Toggle_XIX_Grundumfang_XIX_Klima <-> outer port RP_IF_AQS_Toggle_XIX_Klima
    delegate Grundumfang_XIX_Klima.RP_IF_AQS_Traffic_XIX_Grundumfang_XIX_Klima <-> outer port RP_IF_AQS_Traffic_XIX_Klima
    delegate Grundumfang_XIX_Klima.RP_IF_BCM1_Aussen_Temp_ungef_XIX_Grundumfang_XIX_Klima <-> outer port RP_IF_BCM1_Aussen_Temp_ungef_XIX_Klima
    delegate Grundumfang_XIX_Klima.RP_IF_BCM1_FStatus_Aussentemp_ungef_XIX_Grundumfang_XIX_Klima <-> outer port RP_IF_BCM1_FStatus_Aussentemp_ungef_XIX_Klima
    delegate Grundumfang_XIX_Klima.RP_IF_BCM1_OBD_FStatus_ATemp_XIX_Grundumfang_XIX_Klima <-> outer port RP_IF_BCM1_OBD_FStatus_ATemp_XIX_Klima
    delegate Grundumfang_XIX_Klima.RP_IF_BEM_Red_Innengeblaese_XIX_Grundumfang_XIX_Klima <-> outer port RP_IF_BEM_Red_Innengeblaese_XIX_Klima
    delegate Grundumfang_XIX_Klima.RP_IF_BLOWER1_HW_XIX_Grundumfang_XIX_Klima <-> outer port RP_IF_BLOWER1_HW_XIX_Klima
    delegate Grundumfang_XIX_Klima.RP_IF_BLOWER1_IBATT_XIX_Grundumfang_XIX_Klima <-> outer port RP_IF_BLOWER1_IBATT_XIX_Klima
    delegate Grundumfang_XIX_Klima.RP_IF_BLOWER1_ResponseError_XIX_Grundumfang_XIX_Klima <-> outer port RP_IF_BLOWER1_ResponseError_XIX_Klima
    delegate Grundumfang_XIX_Klima.RP_IF_BLOWER1_STATUS1_XIX_Grundumfang_XIX_Klima <-> outer port RP_IF_BLOWER1_STATUS1_XIX_Klima
    delegate Grundumfang_XIX_Klima.RP_IF_BLOWER1_STATUS2_XIX_Grundumfang_XIX_Klima <-> outer port RP_IF_BLOWER1_STATUS2_XIX_Klima
    delegate Grundumfang_XIX_Klima.RP_IF_BLOWER1_SUPPLIER_XIX_Grundumfang_XIX_Klima <-> outer port RP_IF_BLOWER1_SUPPLIER_XIX_Klima
    delegate Grundumfang_XIX_Klima.RP_IF_BLOWER1_SW_XIX_Grundumfang_XIX_Klima <-> outer port RP_IF_BLOWER1_SW_XIX_Klima
    delegate Grundumfang_XIX_Klima.RP_IF_BLOWER1_TEMPERATURE_XIX_Grundumfang_XIX_Klima <-> outer port RP_IF_BLOWER1_TEMPERATURE_XIX_Klima
    delegate Grundumfang_XIX_Klima.RP_IF_BLOWER1_UBATT_XIX_Grundumfang_XIX_Klima <-> outer port RP_IF_BLOWER1_UBATT_XIX_Klima
    delegate Grundumfang_XIX_Klima.RP_IF_BLOWER1_UMOTOR_XIX_Grundumfang_XIX_Klima <-> outer port RP_IF_BLOWER1_UMOTOR_XIX_Klima
    delegate Grundumfang_XIX_Klima.RP_IF_BLOWER1b_HW_XIX_Grundumfang_XIX_Klima <-> outer port RP_IF_BLOWER1b_HW_XIX_Klima
    delegate Grundumfang_XIX_Klima.RP_IF_BLOWER1b_IBATT_XIX_Grundumfang_XIX_Klima <-> outer port RP_IF_BLOWER1b_IBATT_XIX_Klima
    delegate Grundumfang_XIX_Klima.RP_IF_BLOWER1b_ResponseError_XIX_Grundumfang_XIX_Klima <-> outer port RP_IF_BLOWER1b_ResponseError_XIX_Klima
    delegate Grundumfang_XIX_Klima.RP_IF_BLOWER1b_STATUS1_XIX_Grundumfang_XIX_Klima <-> outer port RP_IF_BLOWER1b_STATUS1_XIX_Klima
    delegate Grundumfang_XIX_Klima.RP_IF_BLOWER1b_STATUS2_XIX_Grundumfang_XIX_Klima <-> outer port RP_IF_BLOWER1b_STATUS2_XIX_Klima
    delegate Grundumfang_XIX_Klima.RP_IF_BLOWER1b_SUPPLIER_XIX_Grundumfang_XIX_Klima <-> outer port RP_IF_BLOWER1b_SUPPLIER_XIX_Klima
    delegate Grundumfang_XIX_Klima.RP_IF_BLOWER1b_SW_XIX_Grundumfang_XIX_Klima <-> outer port RP_IF_BLOWER1b_SW_XIX_Klima
    delegate Grundumfang_XIX_Klima.RP_IF_BLOWER1b_TEMPERATURE_XIX_Grundumfang_XIX_Klima <-> outer port RP_IF_BLOWER1b_TEMPERATURE_XIX_Klima
    delegate Grundumfang_XIX_Klima.RP_IF_BLOWER1b_UBATT_XIX_Grundumfang_XIX_Klima <-> outer port RP_IF_BLOWER1b_UBATT_XIX_Klima
    delegate Grundumfang_XIX_Klima.RP_IF_BLOWER1b_UMOTOR_XIX_Grundumfang_XIX_Klima <-> outer port RP_IF_BLOWER1b_UMOTOR_XIX_Klima
    delegate Grundumfang_XIX_Klima.RP_IF_BLOWER1c_HW_XIX_Grundumfang_XIX_Klima <-> outer port RP_IF_BLOWER1c_HW_XIX_Klima
    delegate Grundumfang_XIX_Klima.RP_IF_BLOWER1c_IBATT_XIX_Grundumfang_XIX_Klima <-> outer port RP_IF_BLOWER1c_IBATT_XIX_Klima
    delegate Grundumfang_XIX_Klima.RP_IF_BLOWER1c_ResponseError_XIX_Grundumfang_XIX_Klima <-> outer port RP_IF_BLOWER1c_ResponseError_XIX_Klima
    delegate Grundumfang_XIX_Klima.RP_IF_BLOWER1c_STATUS1_XIX_Grundumfang_XIX_Klima <-> outer port RP_IF_BLOWER1c_STATUS1_XIX_Klima
    delegate Grundumfang_XIX_Klima.RP_IF_BLOWER1c_STATUS2_XIX_Grundumfang_XIX_Klima <-> outer port RP_IF_BLOWER1c_STATUS2_XIX_Klima
    delegate Grundumfang_XIX_Klima.RP_IF_BLOWER1c_SUPPLIER_XIX_Grundumfang_XIX_Klima <-> outer port RP_IF_BLOWER1c_SUPPLIER_XIX_Klima
    delegate Grundumfang_XIX_Klima.RP_IF_BLOWER1c_SW_XIX_Grundumfang_XIX_Klima <-> outer port RP_IF_BLOWER1c_SW_XIX_Klima
    delegate Grundumfang_XIX_Klima.RP_IF_BLOWER1c_TEMPERATURE_XIX_Grundumfang_XIX_Klima <-> outer port RP_IF_BLOWER1c_TEMPERATURE_XIX_Klima
    delegate Grundumfang_XIX_Klima.RP_IF_BLOWER1c_UBATT_XIX_Grundumfang_XIX_Klima <-> outer port RP_IF_BLOWER1c_UBATT_XIX_Klima
    delegate Grundumfang_XIX_Klima.RP_IF_BLOWER1c_UMOTOR_XIX_Grundumfang_XIX_Klima <-> outer port RP_IF_BLOWER1c_UMOTOR_XIX_Klima
    delegate Grundumfang_XIX_Klima.RP_IF_BLOWER2_HW_XIX_Grundumfang_XIX_Klima <-> outer port RP_IF_BLOWER2_HW_XIX_Klima
    delegate Grundumfang_XIX_Klima.RP_IF_BLOWER2_IBATT_XIX_Grundumfang_XIX_Klima <-> outer port RP_IF_BLOWER2_IBATT_XIX_Klima
    delegate Grundumfang_XIX_Klima.RP_IF_BLOWER2_ResponseError_XIX_Grundumfang_XIX_Klima <-> outer port RP_IF_BLOWER2_ResponseError_XIX_Klima
    delegate Grundumfang_XIX_Klima.RP_IF_BLOWER2_STATUS1_INVALID_XIX_Grundumfang_XIX_Klima <-> outer port RP_IF_BLOWER2_STATUS1_INVALID_XIX_Klima
    delegate Grundumfang_XIX_Klima.RP_IF_BLOWER2_STATUS1_XIX_Grundumfang_XIX_Klima <-> outer port RP_IF_BLOWER2_STATUS1_XIX_Klima
    delegate Grundumfang_XIX_Klima.RP_IF_BLOWER2_STATUS2_XIX_Grundumfang_XIX_Klima <-> outer port RP_IF_BLOWER2_STATUS2_XIX_Klima
    delegate Grundumfang_XIX_Klima.RP_IF_BLOWER2_SUPPLIER_XIX_Grundumfang_XIX_Klima <-> outer port RP_IF_BLOWER2_SUPPLIER_XIX_Klima
    delegate Grundumfang_XIX_Klima.RP_IF_BLOWER2_SW_XIX_Grundumfang_XIX_Klima <-> outer port RP_IF_BLOWER2_SW_XIX_Klima
    delegate Grundumfang_XIX_Klima.RP_IF_BLOWER2_TEMPERATURE_XIX_Grundumfang_XIX_Klima <-> outer port RP_IF_BLOWER2_TEMPERATURE_XIX_Klima
    delegate Grundumfang_XIX_Klima.RP_IF_BLOWER2_UBATT_XIX_Grundumfang_XIX_Klima <-> outer port RP_IF_BLOWER2_UBATT_XIX_Klima
    delegate Grundumfang_XIX_Klima.RP_IF_BLOWER2_UMOTOR_XIX_Grundumfang_XIX_Klima <-> outer port RP_IF_BLOWER2_UMOTOR_XIX_Klima
    delegate Grundumfang_XIX_Klima.RP_IF_BLOWER2b_HW_XIX_Grundumfang_XIX_Klima <-> outer port RP_IF_BLOWER2b_HW_XIX_Klima
    delegate Grundumfang_XIX_Klima.RP_IF_BLOWER2b_IBATT_XIX_Grundumfang_XIX_Klima <-> outer port RP_IF_BLOWER2b_IBATT_XIX_Klima
    delegate Grundumfang_XIX_Klima.RP_IF_BLOWER2b_ResponseError_XIX_Grundumfang_XIX_Klima <-> outer port RP_IF_BLOWER2b_ResponseError_XIX_Klima
    delegate Grundumfang_XIX_Klima.RP_IF_BLOWER2b_STATUS1_INVALID_XIX_Grundumfang_XIX_Klima <-> outer port RP_IF_BLOWER2b_STATUS1_INVALID_XIX_Klima
    delegate Grundumfang_XIX_Klima.RP_IF_BLOWER2b_STATUS1_XIX_Grundumfang_XIX_Klima <-> outer port RP_IF_BLOWER2b_STATUS1_XIX_Klima
    delegate Grundumfang_XIX_Klima.RP_IF_BLOWER2b_STATUS2_XIX_Grundumfang_XIX_Klima <-> outer port RP_IF_BLOWER2b_STATUS2_XIX_Klima
    delegate Grundumfang_XIX_Klima.RP_IF_BLOWER2b_SUPPLIER_XIX_Grundumfang_XIX_Klima <-> outer port RP_IF_BLOWER2b_SUPPLIER_XIX_Klima
    delegate Grundumfang_XIX_Klima.RP_IF_BLOWER2b_SW_XIX_Grundumfang_XIX_Klima <-> outer port RP_IF_BLOWER2b_SW_XIX_Klima
    delegate Grundumfang_XIX_Klima.RP_IF_BLOWER2b_TEMPERATURE_XIX_Grundumfang_XIX_Klima <-> outer port RP_IF_BLOWER2b_TEMPERATURE_XIX_Klima
    delegate Grundumfang_XIX_Klima.RP_IF_BLOWER2b_UBATT_XIX_Grundumfang_XIX_Klima <-> outer port RP_IF_BLOWER2b_UBATT_XIX_Klima
    delegate Grundumfang_XIX_Klima.RP_IF_BLOWER2b_UMOTOR_XIX_Grundumfang_XIX_Klima <-> outer port RP_IF_BLOWER2b_UMOTOR_XIX_Klima
    delegate Grundumfang_XIX_Klima.RP_IF_BLOWER_DIAG_FLAG1_XIX_Grundumfang_XIX_Klima <-> outer port RP_IF_BLOWER_DIAG_FLAG1_XIX_Klima
    delegate Grundumfang_XIX_Klima.RP_IF_BLOWER_DIAG_FLAG2_XIX_Grundumfang_XIX_Klima <-> outer port RP_IF_BLOWER_DIAG_FLAG2_XIX_Klima
    delegate Grundumfang_XIX_Klima.RP_IF_BLOWER_IBATT_XIX_Grundumfang_XIX_Klima <-> outer port RP_IF_BLOWER_IBATT_XIX_Klima
    delegate Grundumfang_XIX_Klima.RP_IF_BLOWER_ResponseError_XIX_Grundumfang_XIX_Klima <-> outer port RP_IF_BLOWER_ResponseError_XIX_Klima
    delegate Grundumfang_XIX_Klima.RP_IF_BLOWER_ROTATION_SPEED_XIX_Grundumfang_XIX_Klima <-> outer port RP_IF_BLOWER_ROTATION_SPEED_XIX_Klima
    delegate Grundumfang_XIX_Klima.RP_IF_BLOWER_STATUS_MOTOR_XIX_Grundumfang_XIX_Klima <-> outer port RP_IF_BLOWER_STATUS_MOTOR_XIX_Klima
    delegate Grundumfang_XIX_Klima.RP_IF_BLOWER_SUPPLIER_XIX_Grundumfang_XIX_Klima <-> outer port RP_IF_BLOWER_SUPPLIER_XIX_Klima
    delegate Grundumfang_XIX_Klima.RP_IF_BLOWER_TEMPERATURE_XIX_Grundumfang_XIX_Klima <-> outer port RP_IF_BLOWER_TEMPERATURE_XIX_Klima
    delegate Grundumfang_XIX_Klima.RP_IF_BLOWER_TORQUE_XIX_Grundumfang_XIX_Klima <-> outer port RP_IF_BLOWER_TORQUE_XIX_Klima
    delegate Grundumfang_XIX_Klima.RP_IF_BLOWER_UBATT_XIX_Grundumfang_XIX_Klima <-> outer port RP_IF_BLOWER_UBATT_XIX_Klima
    delegate Grundumfang_XIX_Klima.RP_IF_BLOWER_UMOTOR_XIX_Grundumfang_XIX_Klima <-> outer port RP_IF_BLOWER_UMOTOR_XIX_Klima
    delegate Grundumfang_XIX_Klima.RP_IF_BMS_BattHeizung_Anf_XIX_Grundumfang_XIX_Klima <-> outer port RP_IF_BMS_BattHeizung_Anf_XIX_Klima
    delegate Grundumfang_XIX_Klima.RP_IF_BMS_DC_Ladeprofil_XIX_Grundumfang_XIX_Klima <-> outer port RP_IF_BMS_DC_Ladeprofil_XIX_Klima
    delegate Grundumfang_XIX_Klima.RP_IF_BMS_Fehler_NTKreis_XIX_Grundumfang_XIX_Klima <-> outer port RP_IF_BMS_Fehler_NTKreis_XIX_Klima
    delegate Grundumfang_XIX_Klima.RP_IF_BMS_Kuehlung_Anf_XIX_Grundumfang_XIX_Klima <-> outer port RP_IF_BMS_Kuehlung_Anf_XIX_Klima
    delegate HVEM_Auto_NL_XIX_Klima.RP_IF_BMS_Kuehlung_Anf_XIX_HVEM_Auto_NL_XIX_Klima <-> outer port RP_IF_BMS_Kuehlung_Anf_XIX_Klima
    delegate Grundumfang_XIX_Klima.RP_IF_BMS_KundenWarnung_XIX_Grundumfang_XIX_Klima <-> outer port RP_IF_BMS_KundenWarnung_XIX_Klima
    delegate Grundumfang_XIX_Klima.RP_IF_BMS_Ladezustand_XIX_Grundumfang_XIX_Klima <-> outer port RP_IF_BMS_Ladezustand_XIX_Klima
    delegate Grundumfang_XIX_Klima.RP_IF_BMS_Pumpe1_Ansteuerung_XIX_Grundumfang_XIX_Klima <-> outer port RP_IF_BMS_Pumpe1_Ansteuerung_XIX_Klima
    delegate Grundumfang_XIX_Klima.RP_IF_BMS_Pumpe2_Ansteuerung_XIX_Grundumfang_XIX_Klima <-> outer port RP_IF_BMS_Pumpe2_Ansteuerung_XIX_Klima
    delegate Grundumfang_XIX_Klima.RP_IF_BMS_RuecklaufTemperatur_XIX_Grundumfang_XIX_Klima <-> outer port RP_IF_BMS_RuecklaufTemperatur_XIX_Klima
    delegate Grundumfang_XIX_Klima.RP_IF_BMS_SollVorlauftemperatur_XIX_Grundumfang_XIX_Klima <-> outer port RP_IF_BMS_SollVorlauftemperatur_XIX_Klima
    delegate Grundumfang_XIX_Klima.RP_IF_BMS_Spannung_XIX_Grundumfang_XIX_Klima <-> outer port RP_IF_BMS_Spannung_XIX_Klima
    delegate Grundumfang_XIX_Klima.RP_IF_BMS_Status_Ventil1_XIX_Grundumfang_XIX_Klima <-> outer port RP_IF_BMS_Status_Ventil1_XIX_Klima
    delegate Grundumfang_XIX_Klima.RP_IF_BMS_Status_Ventil2_XIX_Grundumfang_XIX_Klima <-> outer port RP_IF_BMS_Status_Ventil2_XIX_Klima
    delegate Grundumfang_XIX_Klima.RP_IF_BMS_Strom_XIX_Grundumfang_XIX_Klima <-> outer port RP_IF_BMS_Strom_XIX_Klima
    delegate Grundumfang_XIX_Klima.RP_IF_BMS_Temperatur_XIX_Grundumfang_XIX_Klima <-> outer port RP_IF_BMS_Temperatur_XIX_Klima
    delegate Grundumfang_XIX_Klima.RP_IF_BMS_Temperierung_Anf_XIX_Grundumfang_XIX_Klima <-> outer port RP_IF_BMS_Temperierung_Anf_XIX_Klima
    delegate Grundumfang_XIX_Klima.RP_IF_BMS_TMA_Betriebsart_XIX_Grundumfang_XIX_Klima <-> outer port RP_IF_BMS_TMA_Betriebsart_XIX_Klima
    delegate Grundumfang_XIX_Klima.RP_IF_BMS_TMA_Kuehlkreis_Status_XIX_Grundumfang_XIX_Klima <-> outer port RP_IF_BMS_TMA_Kuehlkreis_Status_XIX_Klima
    delegate HVEM_Auto_NL_XIX_Klima.RP_IF_BMS_UBE_T_XIX_HVEM_Auto_NL_XIX_Klima <-> outer port RP_IF_BMS_UBE_T_XIX_Klima
    delegate Grundumfang_XIX_Klima.RP_IF_BMS_VorlaufTemperatur_XIX_Grundumfang_XIX_Klima <-> outer port RP_IF_BMS_VorlaufTemperatur_XIX_Klima
    delegate Grundumfang_XIX_Klima.RP_IF_BT_FH_Oeffnung_XIX_Grundumfang_XIX_Klima <-> outer port RP_IF_BT_FH_Oeffnung_XIX_Klima
    delegate Grundumfang_XIX_Klima.RP_IF_BT_Tuer_geoeffnet_XIX_Grundumfang_XIX_Klima <-> outer port RP_IF_BT_Tuer_geoeffnet_XIX_Klima
    delegate Grundumfang_XIX_Klima.RP_IF_CHA_Fahrer_Umschaltung_XIX_Grundumfang_XIX_Klima <-> outer port RP_IF_CHA_Fahrer_Umschaltung_XIX_Klima
    delegate Grundumfang_XIX_Klima.RP_IF_CHA_Ziel_FahrPr_KL_XIX_Grundumfang_XIX_Klima <-> outer port RP_IF_CHA_Ziel_FahrPr_KL_XIX_Klima
    delegate Grundumfang_XIX_Klima.RP_IF_DGN_Verlernzaehler_XIX_Grundumfang_XIX_Klima <-> outer port RP_IF_DGN_Verlernzaehler_XIX_Klima  # _XIX_SC_738_ClassicAUTOSARBasicSoftwareICAS1Gateway_XIX_Softwareblock_XIX_ICAS1_X_Gateway_XIX_Grundumfang_XIX_Klima_XIX_DGN_Verlernzaehler
    delegate Grundumfang_XIX_Klima.RP_IF_DI_KL_58xd_XIX_Grundumfang_XIX_Klima <-> outer port RP_IF_DI_KL_58xd_XIX_Klima
    delegate Grundumfang_XIX_Klima.RP_IF_DI_KL_58xs_XIX_Grundumfang_XIX_Klima <-> outer port RP_IF_DI_KL_58xs_XIX_Klima
    delegate Grundumfang_XIX_Klima.RP_IF_DiETa_Defrost_Taste_XIX_Grundumfang_XIX_Klima <-> outer port RP_IF_DiETa_Defrost_Taste_XIX_Klima
    delegate Grundumfang_XIX_Klima.RP_IF_DiETa_FSH_Taste_XIX_Grundumfang_XIX_Klima <-> outer port RP_IF_DiETa_FSH_Taste_XIX_Klima
    delegate Grundumfang_XIX_Klima.RP_IF_DiETa_HSH_Taste_XIX_Grundumfang_XIX_Klima <-> outer port RP_IF_DiETa_HSH_Taste_XIX_Klima
    delegate Grundumfang_XIX_Klima.RP_IF_DiETa_Klima_XIX_Grundumfang_XIX_Klima <-> outer port RP_IF_DiETa_Klima_XIX_Klima
    delegate Grundumfang_XIX_Klima.RP_IF_DS_BitError_XIX_Grundumfang_XIX_Klima <-> outer port RP_IF_DS_BitError_XIX_Klima
    delegate Grundumfang_XIX_Klima.RP_IF_DS_ChecksumError_XIX_Grundumfang_XIX_Klima <-> outer port RP_IF_DS_ChecksumError_XIX_Klima
    delegate Grundumfang_XIX_Klima.RP_IF_DS_DruckError_XIX_Grundumfang_XIX_Klima <-> outer port RP_IF_DS_DruckError_XIX_Klima
    delegate Grundumfang_XIX_Klima.RP_IF_DS_HW_XIX_Grundumfang_XIX_Klima <-> outer port RP_IF_DS_HW_XIX_Klima
    delegate Grundumfang_XIX_Klima.RP_IF_DS_Kaeltemittel_P_XIX_Grundumfang_XIX_Klima <-> outer port RP_IF_DS_Kaeltemittel_P_XIX_Klima
    delegate Grundumfang_XIX_Klima.RP_IF_DS_SW_XIX_Grundumfang_XIX_Klima <-> outer port RP_IF_DS_SW_XIX_Klima
    delegate Grundumfang_XIX_Klima.RP_IF_DS_TempError_XIX_Grundumfang_XIX_Klima <-> outer port RP_IF_DS_TempError_XIX_Klima
    delegate Grundumfang_XIX_Klima.RP_IF_DTS1_Fehler_XIX_Grundumfang_XIX_Klima <-> outer port RP_IF_DTS1_Fehler_XIX_Klima
    delegate Grundumfang_XIX_Klima.RP_IF_DTS1_interne_Sensor_T_XIX_Grundumfang_XIX_Klima <-> outer port RP_IF_DTS1_interne_Sensor_T_XIX_Klima
    delegate Grundumfang_XIX_Klima.RP_IF_DTS1_Kaeltemittel_p_XIX_Grundumfang_XIX_Klima <-> outer port RP_IF_DTS1_Kaeltemittel_p_XIX_Klima
    delegate Grundumfang_XIX_Klima.RP_IF_DTS1_Kaeltemittel_T_XIX_Grundumfang_XIX_Klima <-> outer port RP_IF_DTS1_Kaeltemittel_T_XIX_Klima
    delegate Grundumfang_XIX_Klima.RP_IF_DTS1_Kommunikation_XIX_Grundumfang_XIX_Klima <-> outer port RP_IF_DTS1_Kommunikation_XIX_Klima
    delegate Grundumfang_XIX_Klima.RP_IF_DTS1_R744_Fehler_XIX_Grundumfang_XIX_Klima <-> outer port RP_IF_DTS1_R744_Fehler_XIX_Klima
    delegate Grundumfang_XIX_Klima.RP_IF_DTS1_R744_interne_Sensor_T_XIX_Grundumfang_XIX_Klima <-> outer port RP_IF_DTS1_R744_interne_Sensor_T_XIX_Klima
    delegate Grundumfang_XIX_Klima.RP_IF_DTS1_R744_Kaeltemittel_p_XIX_Grundumfang_XIX_Klima <-> outer port RP_IF_DTS1_R744_Kaeltemittel_p_XIX_Klima
    delegate Grundumfang_XIX_Klima.RP_IF_DTS1_R744_Kaeltemittel_t_XIX_Grundumfang_XIX_Klima <-> outer port RP_IF_DTS1_R744_Kaeltemittel_t_XIX_Klima
    delegate Grundumfang_XIX_Klima.RP_IF_DTS1_R744_Kommunikation_XIX_Grundumfang_XIX_Klima <-> outer port RP_IF_DTS1_R744_Kommunikation_XIX_Klima
    delegate Grundumfang_XIX_Klima.RP_IF_DTS1_R744_ResponseError_XIX_Grundumfang_XIX_Klima <-> outer port RP_IF_DTS1_R744_ResponseError_XIX_Klima
    delegate Grundumfang_XIX_Klima.RP_IF_DTS1_R744_TNCTOC_XIX_Grundumfang_XIX_Klima <-> outer port RP_IF_DTS1_R744_TNCTOC_XIX_Klima
    delegate Grundumfang_XIX_Klima.RP_IF_DTS1_ResponseError_XIX_Grundumfang_XIX_Klima <-> outer port RP_IF_DTS1_ResponseError_XIX_Klima
    delegate Grundumfang_XIX_Klima.RP_IF_DTS1_TNCTOC_XIX_Grundumfang_XIX_Klima <-> outer port RP_IF_DTS1_TNCTOC_XIX_Klima
    delegate Grundumfang_XIX_Klima.RP_IF_DTS2_Fehler_XIX_Grundumfang_XIX_Klima <-> outer port RP_IF_DTS2_Fehler_XIX_Klima
    delegate Grundumfang_XIX_Klima.RP_IF_DTS2_interne_Sensor_T_XIX_Grundumfang_XIX_Klima <-> outer port RP_IF_DTS2_interne_Sensor_T_XIX_Klima
    delegate Grundumfang_XIX_Klima.RP_IF_DTS2_Kaeltemittel_p_XIX_Grundumfang_XIX_Klima <-> outer port RP_IF_DTS2_Kaeltemittel_p_XIX_Klima
    delegate Grundumfang_XIX_Klima.RP_IF_DTS2_Kaeltemittel_T_XIX_Grundumfang_XIX_Klima <-> outer port RP_IF_DTS2_Kaeltemittel_T_XIX_Klima
    delegate Grundumfang_XIX_Klima.RP_IF_DTS2_Kommunikation_XIX_Grundumfang_XIX_Klima <-> outer port RP_IF_DTS2_Kommunikation_XIX_Klima
    delegate Grundumfang_XIX_Klima.RP_IF_DTS2_R744_Fehler_XIX_Grundumfang_XIX_Klima <-> outer port RP_IF_DTS2_R744_Fehler_XIX_Klima
    delegate Grundumfang_XIX_Klima.RP_IF_DTS2_R744_interne_Sensor_T_XIX_Grundumfang_XIX_Klima <-> outer port RP_IF_DTS2_R744_interne_Sensor_T_XIX_Klima
    delegate Grundumfang_XIX_Klima.RP_IF_DTS2_R744_Kaeltemittel_p_XIX_Grundumfang_XIX_Klima <-> outer port RP_IF_DTS2_R744_Kaeltemittel_p_XIX_Klima
    delegate Grundumfang_XIX_Klima.RP_IF_DTS2_R744_Kaeltemittel_t_XIX_Grundumfang_XIX_Klima <-> outer port RP_IF_DTS2_R744_Kaeltemittel_t_XIX_Klima
    delegate Grundumfang_XIX_Klima.RP_IF_DTS2_R744_Kommunikation_XIX_Grundumfang_XIX_Klima <-> outer port RP_IF_DTS2_R744_Kommunikation_XIX_Klima
    delegate Grundumfang_XIX_Klima.RP_IF_DTS2_R744_ResponseError_XIX_Grundumfang_XIX_Klima <-> outer port RP_IF_DTS2_R744_ResponseError_XIX_Klima
    delegate Grundumfang_XIX_Klima.RP_IF_DTS2_R744_TNCTOC_XIX_Grundumfang_XIX_Klima <-> outer port RP_IF_DTS2_R744_TNCTOC_XIX_Klima
    delegate Grundumfang_XIX_Klima.RP_IF_DTS2_ResponseError_XIX_Grundumfang_XIX_Klima <-> outer port RP_IF_DTS2_ResponseError_XIX_Klima
    delegate Grundumfang_XIX_Klima.RP_IF_DTS2_TNCTOC_XIX_Grundumfang_XIX_Klima <-> outer port RP_IF_DTS2_TNCTOC_XIX_Klima
    delegate Grundumfang_XIX_Klima.RP_IF_DTS2b_R744_Fehler_XIX_Grundumfang_XIX_Klima <-> outer port RP_IF_DTS2b_R744_Fehler_XIX_Klima
    delegate Grundumfang_XIX_Klima.RP_IF_DTS2b_R744_interne_Sensor_T_XIX_Grundumfang_XIX_Klima <-> outer port RP_IF_DTS2b_R744_interne_Sensor_T_XIX_Klima
    delegate Grundumfang_XIX_Klima.RP_IF_DTS2b_R744_Kaeltemittel_p_XIX_Grundumfang_XIX_Klima <-> outer port RP_IF_DTS2b_R744_Kaeltemittel_p_XIX_Klima
    delegate Grundumfang_XIX_Klima.RP_IF_DTS2b_R744_Kaeltemittel_t_XIX_Grundumfang_XIX_Klima <-> outer port RP_IF_DTS2b_R744_Kaeltemittel_t_XIX_Klima
    delegate Grundumfang_XIX_Klima.RP_IF_DTS2b_R744_Kommunikation_XIX_Grundumfang_XIX_Klima <-> outer port RP_IF_DTS2b_R744_Kommunikation_XIX_Klima
    delegate Grundumfang_XIX_Klima.RP_IF_DTS2b_R744_ResponseError_XIX_Grundumfang_XIX_Klima <-> outer port RP_IF_DTS2b_R744_ResponseError_XIX_Klima
    delegate Grundumfang_XIX_Klima.RP_IF_DTS2b_R744_TNCTOC_XIX_Grundumfang_XIX_Klima <-> outer port RP_IF_DTS2b_R744_TNCTOC_XIX_Klima
    delegate Grundumfang_XIX_Klima.RP_IF_DTS2c_R744_Fehler_XIX_Grundumfang_XIX_Klima <-> outer port RP_IF_DTS2c_R744_Fehler_XIX_Klima
    delegate Grundumfang_XIX_Klima.RP_IF_DTS2c_R744_interne_Sensor_T_XIX_Grundumfang_XIX_Klima <-> outer port RP_IF_DTS2c_R744_interne_Sensor_T_XIX_Klima
    delegate Grundumfang_XIX_Klima.RP_IF_DTS2c_R744_Kaeltemittel_p_XIX_Grundumfang_XIX_Klima <-> outer port RP_IF_DTS2c_R744_Kaeltemittel_p_XIX_Klima
    delegate Grundumfang_XIX_Klima.RP_IF_DTS2c_R744_Kaeltemittel_t_XIX_Grundumfang_XIX_Klima <-> outer port RP_IF_DTS2c_R744_Kaeltemittel_t_XIX_Klima
    delegate Grundumfang_XIX_Klima.RP_IF_DTS2c_R744_Kommunikation_XIX_Grundumfang_XIX_Klima <-> outer port RP_IF_DTS2c_R744_Kommunikation_XIX_Klima
    delegate Grundumfang_XIX_Klima.RP_IF_DTS2c_R744_ResponseError_XIX_Grundumfang_XIX_Klima <-> outer port RP_IF_DTS2c_R744_ResponseError_XIX_Klima
    delegate Grundumfang_XIX_Klima.RP_IF_DTS2c_R744_TNCTOC_XIX_Grundumfang_XIX_Klima <-> outer port RP_IF_DTS2c_R744_TNCTOC_XIX_Klima
    delegate Grundumfang_XIX_Klima.RP_IF_DTS3_Fehler_XIX_Grundumfang_XIX_Klima <-> outer port RP_IF_DTS3_Fehler_XIX_Klima
    delegate Grundumfang_XIX_Klima.RP_IF_DTS3_interne_Sensor_T_XIX_Grundumfang_XIX_Klima <-> outer port RP_IF_DTS3_interne_Sensor_T_XIX_Klima
    delegate Grundumfang_XIX_Klima.RP_IF_DTS3_Kaeltemittel_p_XIX_Grundumfang_XIX_Klima <-> outer port RP_IF_DTS3_Kaeltemittel_p_XIX_Klima
    delegate Grundumfang_XIX_Klima.RP_IF_DTS3_Kaeltemittel_T_XIX_Grundumfang_XIX_Klima <-> outer port RP_IF_DTS3_Kaeltemittel_T_XIX_Klima
    delegate Grundumfang_XIX_Klima.RP_IF_DTS3_Kommunikation_XIX_Grundumfang_XIX_Klima <-> outer port RP_IF_DTS3_Kommunikation_XIX_Klima
    delegate Grundumfang_XIX_Klima.RP_IF_DTS3_R744_Fehler_XIX_Grundumfang_XIX_Klima <-> outer port RP_IF_DTS3_R744_Fehler_XIX_Klima
    delegate Grundumfang_XIX_Klima.RP_IF_DTS3_R744_interne_Sensor_T_XIX_Grundumfang_XIX_Klima <-> outer port RP_IF_DTS3_R744_interne_Sensor_T_XIX_Klima
    delegate Grundumfang_XIX_Klima.RP_IF_DTS3_R744_Kaeltemittel_p_XIX_Grundumfang_XIX_Klima <-> outer port RP_IF_DTS3_R744_Kaeltemittel_p_XIX_Klima
    delegate Grundumfang_XIX_Klima.RP_IF_DTS3_R744_Kaeltemittel_t_XIX_Grundumfang_XIX_Klima <-> outer port RP_IF_DTS3_R744_Kaeltemittel_t_XIX_Klima
    delegate Grundumfang_XIX_Klima.RP_IF_DTS3_R744_Kommunikation_XIX_Grundumfang_XIX_Klima <-> outer port RP_IF_DTS3_R744_Kommunikation_XIX_Klima
    delegate Grundumfang_XIX_Klima.RP_IF_DTS3_R744_ResponseError_XIX_Grundumfang_XIX_Klima <-> outer port RP_IF_DTS3_R744_ResponseError_XIX_Klima
    delegate Grundumfang_XIX_Klima.RP_IF_DTS3_R744_TNCTOC_XIX_Grundumfang_XIX_Klima <-> outer port RP_IF_DTS3_R744_TNCTOC_XIX_Klima
    delegate Grundumfang_XIX_Klima.RP_IF_DTS3_ResponseError_XIX_Grundumfang_XIX_Klima <-> outer port RP_IF_DTS3_ResponseError_XIX_Klima
    delegate Grundumfang_XIX_Klima.RP_IF_DTS3_TNCTOC_XIX_Grundumfang_XIX_Klima <-> outer port RP_IF_DTS3_TNCTOC_XIX_Klima
    delegate Grundumfang_XIX_Klima.RP_IF_DTS3b_R744_Fehler_XIX_Grundumfang_XIX_Klima <-> outer port RP_IF_DTS3b_R744_Fehler_XIX_Klima
    delegate Grundumfang_XIX_Klima.RP_IF_DTS3b_R744_interne_Sensor_T_XIX_Grundumfang_XIX_Klima <-> outer port RP_IF_DTS3b_R744_interne_Sensor_T_XIX_Klima
    delegate Grundumfang_XIX_Klima.RP_IF_DTS3b_R744_Kaeltemittel_p_XIX_Grundumfang_XIX_Klima <-> outer port RP_IF_DTS3b_R744_Kaeltemittel_p_XIX_Klima
    delegate Grundumfang_XIX_Klima.RP_IF_DTS3b_R744_Kaeltemittel_t_XIX_Grundumfang_XIX_Klima <-> outer port RP_IF_DTS3b_R744_Kaeltemittel_t_XIX_Klima
    delegate Grundumfang_XIX_Klima.RP_IF_DTS3b_R744_Kommunikation_XIX_Grundumfang_XIX_Klima <-> outer port RP_IF_DTS3b_R744_Kommunikation_XIX_Klima
    delegate Grundumfang_XIX_Klima.RP_IF_DTS3b_R744_ResponseError_XIX_Grundumfang_XIX_Klima <-> outer port RP_IF_DTS3b_R744_ResponseError_XIX_Klima
    delegate Grundumfang_XIX_Klima.RP_IF_DTS3b_R744_TNCTOC_XIX_Grundumfang_XIX_Klima <-> outer port RP_IF_DTS3b_R744_TNCTOC_XIX_Klima
    delegate Grundumfang_XIX_Klima.RP_IF_EASV1_Err_Blockierung_TF_XIX_Grundumfang_XIX_Klima <-> outer port RP_IF_EASV1_Err_Blockierung_TF_XIX_Klima
    delegate Grundumfang_XIX_Klima.RP_IF_EASV1_Err_Blockierung_TNCTOC_XIX_Grundumfang_XIX_Klima <-> outer port RP_IF_EASV1_Err_Blockierung_TNCTOC_XIX_Klima
    delegate Grundumfang_XIX_Klima.RP_IF_EASV1_Err_EDefekt_MoKomp_TF_XIX_Grundumfang_XIX_Klima <-> outer port RP_IF_EASV1_Err_EDefekt_MoKomp_TF_XIX_Klima
    delegate Grundumfang_XIX_Klima.RP_IF_EASV1_Err_EDefekt_MoKomp_TNCTOC_XIX_Grundumfang_XIX_Klima <-> outer port RP_IF_EASV1_Err_EDefekt_MoKomp_TNCTOC_XIX_Klima
    delegate Grundumfang_XIX_Klima.RP_IF_EASV1_Err_EDefekt_TSens_TF_XIX_Grundumfang_XIX_Klima <-> outer port RP_IF_EASV1_Err_EDefekt_TSens_TF_XIX_Klima
    delegate Grundumfang_XIX_Klima.RP_IF_EASV1_Err_EDefekt_TSens_TNCTOC_XIX_Grundumfang_XIX_Klima <-> outer port RP_IF_EASV1_Err_EDefekt_TSens_TNCTOC_XIX_Klima
    delegate Grundumfang_XIX_Klima.RP_IF_EASV1_Err_Notlaufpos_TF_XIX_Grundumfang_XIX_Klima <-> outer port RP_IF_EASV1_Err_Notlaufpos_TF_XIX_Klima
    delegate Grundumfang_XIX_Klima.RP_IF_EASV1_Err_Notlaufpos_TNCTOC_XIX_Grundumfang_XIX_Klima <-> outer port RP_IF_EASV1_Err_Notlaufpos_TNCTOC_XIX_Klima
    delegate Grundumfang_XIX_Klima.RP_IF_EASV1_Err_RAMROMNADChange_TF_XIX_Grundumfang_XIX_Klima <-> outer port RP_IF_EASV1_Err_RAMROMNADChange_TF_XIX_Klima
    delegate Grundumfang_XIX_Klima.RP_IF_EASV1_Err_RAMROMNADChange_TNCTOC_XIX_Grundumfang_XIX_Klima <-> outer port RP_IF_EASV1_Err_RAMROMNADChange_TNCTOC_XIX_Klima
    delegate Grundumfang_XIX_Klima.RP_IF_EASV1_Err_Ueberspannung_TF_XIX_Grundumfang_XIX_Klima <-> outer port RP_IF_EASV1_Err_Ueberspannung_TF_XIX_Klima
    delegate Grundumfang_XIX_Klima.RP_IF_EASV1_Err_Ueberspannung_TNCTOC_XIX_Grundumfang_XIX_Klima <-> outer port RP_IF_EASV1_Err_Ueberspannung_TNCTOC_XIX_Klima
    delegate Grundumfang_XIX_Klima.RP_IF_EASV1_Err_Uebertemperatur_TF_XIX_Grundumfang_XIX_Klima <-> outer port RP_IF_EASV1_Err_Uebertemperatur_TF_XIX_Klima
    delegate Grundumfang_XIX_Klima.RP_IF_EASV1_Err_Uebertemperatur_TNCTOC_XIX_Grundumfang_XIX_Klima <-> outer port RP_IF_EASV1_Err_Uebertemperatur_TNCTOC_XIX_Klima
    delegate Grundumfang_XIX_Klima.RP_IF_EASV1_Err_Unterspannung_TF_XIX_Grundumfang_XIX_Klima <-> outer port RP_IF_EASV1_Err_Unterspannung_TF_XIX_Klima
    delegate Grundumfang_XIX_Klima.RP_IF_EASV1_Err_Unterspannung_TNCTOC_XIX_Grundumfang_XIX_Klima <-> outer port RP_IF_EASV1_Err_Unterspannung_TNCTOC_XIX_Klima
    delegate Grundumfang_XIX_Klima.RP_IF_EASV1_ErrMem_State_XIX_Grundumfang_XIX_Klima <-> outer port RP_IF_EASV1_ErrMem_State_XIX_Klima
    delegate Grundumfang_XIX_Klima.RP_IF_EASV1_Geschwindigkeitsstatus_XIX_Grundumfang_XIX_Klima <-> outer port RP_IF_EASV1_Geschwindigkeitsstatus_XIX_Klima
    delegate Grundumfang_XIX_Klima.RP_IF_EASV1_Ist_Position_Aktuator_XIX_Grundumfang_XIX_Klima <-> outer port RP_IF_EASV1_Ist_Position_Aktuator_XIX_Klima
    delegate Grundumfang_XIX_Klima.RP_IF_EASV1_ResponseError_TNCTOC_XIX_Grundumfang_XIX_Klima <-> outer port RP_IF_EASV1_ResponseError_TNCTOC_XIX_Klima
    delegate Grundumfang_XIX_Klima.RP_IF_EASV1_ResponseError_XIX_Grundumfang_XIX_Klima <-> outer port RP_IF_EASV1_ResponseError_XIX_Klima
    delegate Grundumfang_XIX_Klima.RP_IF_EASV1_Spulenbestromung_XIX_Grundumfang_XIX_Klima <-> outer port RP_IF_EASV1_Spulenbestromung_XIX_Klima
    delegate Grundumfang_XIX_Klima.RP_IF_EASV1_Temp_Warning_XIX_Grundumfang_XIX_Klima <-> outer port RP_IF_EASV1_Temp_Warning_XIX_Klima
    delegate Grundumfang_XIX_Klima.RP_IF_EASV1_Temp_XIX_Grundumfang_XIX_Klima <-> outer port RP_IF_EASV1_Temp_XIX_Klima
    delegate Grundumfang_XIX_Klima.RP_IF_EASV2_Err_Blockierung_TF_XIX_Grundumfang_XIX_Klima <-> outer port RP_IF_EASV2_Err_Blockierung_TF_XIX_Klima
    delegate Grundumfang_XIX_Klima.RP_IF_EASV2_Err_Blockierung_TNCTOC_XIX_Grundumfang_XIX_Klima <-> outer port RP_IF_EASV2_Err_Blockierung_TNCTOC_XIX_Klima
    delegate Grundumfang_XIX_Klima.RP_IF_EASV2_Err_EDefekt_MoKomp_TF_XIX_Grundumfang_XIX_Klima <-> outer port RP_IF_EASV2_Err_EDefekt_MoKomp_TF_XIX_Klima
    delegate Grundumfang_XIX_Klima.RP_IF_EASV2_Err_EDefekt_MoKomp_TNCTOC_XIX_Grundumfang_XIX_Klima <-> outer port RP_IF_EASV2_Err_EDefekt_MoKomp_TNCTOC_XIX_Klima
    delegate Grundumfang_XIX_Klima.RP_IF_EASV2_Err_EDefekt_TSens_TF_XIX_Grundumfang_XIX_Klima <-> outer port RP_IF_EASV2_Err_EDefekt_TSens_TF_XIX_Klima
    delegate Grundumfang_XIX_Klima.RP_IF_EASV2_Err_EDefekt_TSens_TNCTOC_XIX_Grundumfang_XIX_Klima <-> outer port RP_IF_EASV2_Err_EDefekt_TSens_TNCTOC_XIX_Klima
    delegate Grundumfang_XIX_Klima.RP_IF_EASV2_Err_Notlaufpos_TF_XIX_Grundumfang_XIX_Klima <-> outer port RP_IF_EASV2_Err_Notlaufpos_TF_XIX_Klima
